VERSION ""

NS_ :

BS_:

BU_: TestTool AFL_AHL LDM_LH LDM_RH
VAL_TABLE_ GFAVity 1 "present" 0 "not present" ;

BO_ 3221225472 VECTOR__INDEPENDENT_SIG_MSG: 0 Vector__XXX
 SG_ HdLmpLvlgMtrRtdCurr : 0|11@0+ (1,0) [0|0] "" Vector__XXX
 SG_ LftPrkLmpDimValue : 0|8@0+ (1,0) [0|0] "" Vector__XXX
 SG_ LftPrkLmpCmd : 0|3@0+ (1,0) [0|0] "" Vector__XXX
 SG_ SystmStat_OvrVltgFail_GFHB_LH : 0|1@0+ (1,0) [0|1] "" Vector__XXX
 SG_ SystmStat_IntrnlSysFail_GFHB_LH : 0|1@0+ (1,0) [0|1] "" Vector__XXX
 SG_ SystmStat_OpnLoadFail_GFHB_LH : 0|1@0+ (1,0) [0|1] "" Vector__XXX
 SG_ SystmStat_ShrtCirctFail_GFHB_LH : 0|1@0+ (1,0) [0|1] "" Vector__XXX
 SG_ SystmStat_OverTempFail_GFHB_LH : 0|1@0+ (1,0) [0|1] "" Vector__XXX
 SG_ SystmStat_MstrMsgFail_GFHB_LH : 0|1@0+ (1,0) [0|1] "" Vector__XXX
 SG_ SystmStat_FanFail_GFHB_LH : 0|1@0+ (1,0) [0|1] "" Vector__XXX
 SG_ SystmStat_CurntCdngFail_GFHB_LH : 0|1@0+ (1,0) [0|1] "" Vector__XXX
 SG_ SystmStat_ExtTempFail_GFHB_LH : 0|1@0+ (1,0) [0|1] "" Vector__XXX
 SG_ SystmStat_IntnlTempFail_GFHB_LH : 0|1@0+ (1,0) [0|1] "" Vector__XXX
 SG_ SystmStat_ActutorFail_GFHB_LH : 0|1@0+ (1,0) [0|1] "" Vector__XXX
 SG_ SystmStat_UndVltgFail_GFHB_LH : 0|1@0+ (1,0) [0|1] "" Vector__XXX
 SG_ SystmStat_FnctnStat_GFHB_LH : 0|1@0+ (1,0) [0|1] "" Vector__XXX
 SG_ SystmStat_R_L_DtctnFail_GFHB_LH : 0|1@0+ (1,0) [0|1] "" Vector__XXX
 SG_ SystmStat_CSorMCFail_GFHB_LH : 0|1@0+ (1,0) [0|1] "" Vector__XXX
 SG_ SystmStat_IncCompFail_GFHB_LH : 0|1@0+ (1,0) [0|1] "" Vector__XXX
 SG_ SystmStat_OvrVltgFail_GFHB_RH : 0|1@0+ (1,0) [0|1] "" Vector__XXX
 SG_ SystmStat_IntrnlSysFail_GFHB_RH : 0|1@0+ (1,0) [0|1] "" Vector__XXX
 SG_ SystmStat_OpnLoadFail_GFHB_RH : 0|1@0+ (1,0) [0|1] "" Vector__XXX
 SG_ SystmStat_ShrtCirctFail_GFHB_RH : 0|1@0+ (1,0) [0|1] "" Vector__XXX
 SG_ SystmStat_OverTempFail_GFHB_RH : 0|1@0+ (1,0) [0|1] "" Vector__XXX
 SG_ SystmStat_MstrMsgFail_GFHB_RH : 0|1@0+ (1,0) [0|1] "" Vector__XXX
 SG_ SystmStat_FanFail_GFHB_RH : 0|1@0+ (1,0) [0|1] "" Vector__XXX
 SG_ SystmStat_CurntCdngFail_GFHB_RH : 0|1@0+ (1,0) [0|1] "" Vector__XXX
 SG_ SystmStat_ExtTempFail_GFHB_RH : 0|1@0+ (1,0) [0|1] "" Vector__XXX
 SG_ SystmStat_IntnlTempFail_GFHB_RH : 0|1@0+ (1,0) [0|1] "" Vector__XXX
 SG_ SystmStat_ActutorFail_GFHB_RH : 0|1@0+ (1,0) [0|1] "" Vector__XXX
 SG_ SystmStat_UndVltgFail_GFHB_RH : 0|1@0+ (1,0) [0|1] "" Vector__XXX
 SG_ SystmStat_FnctnStat_GFHB_RH : 0|1@0+ (1,0) [0|1] "" Vector__XXX
 SG_ SystmStat_R_L_DtctnFail_GFHB_RH : 0|1@0+ (1,0) [0|1] "" Vector__XXX
 SG_ SystmStat_CSorMCFail_GFHB_RH : 0|1@0+ (1,0) [0|1] "" Vector__XXX
 SG_ SystmStat_IncCompFail_GFHB_RH : 0|1@0+ (1,0) [0|1] "" Vector__XXX
 SG_ SystmStat_OvrVltgFail_LDS_LH : 0|1@0+ (1,0) [0|0] "" Vector__XXX
 SG_ SystmStat_IntrnlSysFail_LDS_LH : 0|1@0+ (1,0) [0|1] "" Vector__XXX
 SG_ SystmStat_OpnLoadFail_LDS_LH : 0|1@0+ (1,0) [0|0] "" Vector__XXX
 SG_ SystmStat_ShrtCirctFail_LDS_LH : 0|1@0+ (1,0) [0|0] "" Vector__XXX
 SG_ SystmStat_OverTempFail_LDS_LH : 0|1@0+ (1,0) [0|0] "" Vector__XXX
 SG_ SystmStat_MstrMsgFail_LDS_LH : 0|1@0+ (1,0) [0|0] "" Vector__XXX
 SG_ SystmStat_FanFail_LDS_LH : 0|1@0+ (1,0) [0|0] "" Vector__XXX
 SG_ SystmStat_CurntCdngFail_LDS_LH : 0|1@0+ (1,0) [0|0] "" Vector__XXX
 SG_ SystmStat_ExtTempFail_LDS_LH : 0|1@0+ (1,0) [0|0] "" Vector__XXX
 SG_ SystmStat_IntnlTempFail_LDS_LH : 0|1@0+ (1,0) [0|0] "" Vector__XXX
 SG_ SystmStat_ActutorFail_LDS_LH : 0|1@0+ (1,0) [0|0] "" Vector__XXX
 SG_ SystmStat_UndVltgFail_LDS_LH : 0|1@0+ (1,0) [0|0] "" Vector__XXX
 SG_ SystmStat_FnctnStat_LDS_LH : 0|1@0+ (1,0) [0|1] "" Vector__XXX
 SG_ SystmStat_R_L_DtctnFail_LDS_LH : 0|1@0+ (1,0) [0|0] "" Vector__XXX
 SG_ SystmStat_CSorMCFail_LDS_LH : 0|1@0+ (1,0) [0|0] "" Vector__XXX
 SG_ SystmStat_IncCompFail_LDS_LH : 0|1@0+ (1,0) [0|0] "" Vector__XXX
 SG_ SystmStat_OvrVltgFail_LDS_RH : 0|1@0+ (1,0) [0|0] "" Vector__XXX
 SG_ SystmStat_IntrnlSysFail_LDS_RH : 0|1@0+ (1,0) [0|0] "" Vector__XXX
 SG_ SystmStat_OpnLoadFail_LDS_RH : 0|1@0+ (1,0) [0|0] "" Vector__XXX
 SG_ SystmStat_ShrtCirctFail_LDS_RH : 0|1@0+ (1,0) [0|0] "" Vector__XXX
 SG_ SystmStat_OverTempFail_LDS_RH : 0|1@0+ (1,0) [0|0] "" Vector__XXX
 SG_ SystmStat_MstrMsgFail_LDS_RH : 0|1@0+ (1,0) [0|0] "" Vector__XXX
 SG_ SystmStat_FanFail_LDS_RH : 0|1@0+ (1,0) [0|0] "" Vector__XXX
 SG_ SystmStat_CurntCdngFail_LDS_RH : 0|1@0+ (1,0) [0|0] "" Vector__XXX
 SG_ SystmStat_ExtTempFail_LDS_RH : 0|1@0+ (1,0) [0|0] "" Vector__XXX
 SG_ SystmStat_IntnlTempFail_LDS_RH : 0|1@0+ (1,0) [0|0] "" Vector__XXX
 SG_ SystmStat_ActutorFail_LDS_RH : 0|1@0+ (1,0) [0|0] "" Vector__XXX
 SG_ SystmStat_UndVltgFail_LDS_RH : 0|1@0+ (1,0) [0|0] "" Vector__XXX
 SG_ SystmStat_FnctnStat_LDS_RH : 0|1@0+ (1,0) [0|1] "" Vector__XXX
 SG_ SystmStat_R_L_DtctnFail_LDS_RH : 0|1@0+ (1,0) [0|0] "" Vector__XXX
 SG_ SystmStat_CSorMCFail_LDS_RH : 0|1@0+ (1,0) [0|0] "" Vector__XXX
 SG_ SystmStat_IncCompFail_LDS_RH : 0|1@0+ (1,0) [0|0] "" Vector__XXX
 SG_ SystmStat_OvrVltgFail_SBLS_LH : 0|1@0+ (1,0) [0|1] "" Vector__XXX
 SG_ SystmStat_IntrnlSysFail_SBLS_LH : 0|1@0+ (1,0) [0|1] "" Vector__XXX
 SG_ SystmStat_OpnLoadFail_SBLS_LH : 0|1@0+ (1,0) [0|1] "" Vector__XXX
 SG_ SystmStat_ShrtCirctFail_SBLS_LH : 0|1@0+ (1,0) [0|1] "" Vector__XXX
 SG_ SystmStat_OverTempFail_SBLS_LH : 0|1@0+ (1,0) [0|1] "" Vector__XXX
 SG_ SystmStat_MstrMsgFail_SBLS_LH : 0|1@0+ (1,0) [0|1] "" Vector__XXX
 SG_ SystmStat_FanFail_SBLS_LH : 0|1@0+ (1,0) [0|1] "" Vector__XXX
 SG_ SystmStat_CurntCdngFail_SBLS_LH : 0|1@0+ (1,0) [0|1] "" Vector__XXX
 SG_ SystmStat_ExtTempFail_SBLS_LH : 0|1@0+ (1,0) [0|1] "" Vector__XXX
 SG_ SystmStat_IntnlTempFail_SBLS_LH : 0|1@0+ (1,0) [0|1] "" Vector__XXX
 SG_ SystmStat_ActutorFail_SBLS_LH : 0|1@0+ (1,0) [0|1] "" Vector__XXX
 SG_ SystmStat_UndVltgFail_SBLS_LH : 0|1@0+ (1,0) [0|1] "" Vector__XXX
 SG_ SystmStat_FnctnStat_SBLS_LH : 0|1@0+ (1,0) [0|1] "" Vector__XXX
 SG_ SystmStat_R_L_DtctnFail_SBLS_LH : 0|1@0+ (1,0) [0|1] "" Vector__XXX
 SG_ SystmStat_CSorMCFail_SBLS_LH : 0|1@0+ (1,0) [0|0] "" Vector__XXX
 SG_ SystmStat_IncCompFail_SBLS_LH : 0|1@0+ (1,0) [0|1] "" Vector__XXX
 SG_ SystmStat_OvrVltgFail_SBLS_RH : 0|1@0+ (1,0) [0|1] "" Vector__XXX
 SG_ SystmStat_IntrnlSysFail_SBLS_RH : 0|1@0+ (1,0) [0|1] "" Vector__XXX
 SG_ SystmStat_OpnLoadFail_SBLS_RH : 0|1@0+ (1,0) [0|1] "" Vector__XXX
 SG_ SystmStat_ShrtCirctFail_SBLS_RH : 0|1@0+ (1,0) [0|1] "" Vector__XXX
 SG_ SystmStat_OverTempFail_SBLS_RH : 0|1@0+ (1,0) [0|1] "" Vector__XXX
 SG_ SystmStat_MstrMsgFail_SBLS_RH : 0|1@0+ (1,0) [0|1] "" Vector__XXX
 SG_ SystmStat_FanFail_SBLS_RH : 0|1@0+ (1,0) [0|1] "" Vector__XXX
 SG_ SystmStat_CurntCdngFail_SBLS_RH : 0|1@0+ (1,0) [0|1] "" Vector__XXX
 SG_ SystmStat_ExtTempFail_SBLS_RH : 0|1@0+ (1,0) [0|1] "" Vector__XXX
 SG_ SystmStat_IntnlTempFail_SBLS_RH : 0|1@0+ (1,0) [0|1] "" Vector__XXX
 SG_ SystmStat_ActutorFail_SBLS_RH : 0|1@0+ (1,0) [0|1] "" Vector__XXX
 SG_ SystmStat_UndVltgFail_SBLS_RH : 0|1@0+ (1,0) [0|1] "" Vector__XXX
 SG_ SystmStat_FnctnStat_SBLS_RH : 0|1@0+ (1,0) [0|1] "" Vector__XXX
 SG_ SystmStat_R_L_DtctnFail_SBLS_RH : 0|1@0+ (1,0) [0|1] "" Vector__XXX
 SG_ SystmStat_CSorMCFail_SBLS_RH : 0|1@0+ (1,0) [0|1] "" Vector__XXX
 SG_ SystmStat_IncCompFail_SBLS_RH : 0|1@0+ (1,0) [0|1] "" Vector__XXX
 SG_ LftGFHBMsgCnt : 0|4@0+ (1,0) [0|15] "" Vector__XXX
 SG_ LftGFHBSysPwr : 0|8@0+ (0.1,0) [0|25.5] "V" Vector__XXX
 SG_ LftGFHBLampTemp : 0|8@0+ (1,-50) [-50|205] "°„C" Vector__XXX
 SG_ LftGFHBLdmTemp : 0|8@0+ (1,-50) [-50|205] "°„C" Vector__XXX
 SG_ LftGFHBVINSts : 0|1@0+ (1,0) [0|1] "Enum" Vector__XXX
 SG_ LftGFHBSysCaliSts : 0|2@0+ (1,0) [0|3] "Enum" Vector__XXX
 SG_ LftGFHBDerateSts : 0|2@0+ (1,0) [0|3] "Enum" Vector__XXX
 SG_ LftGFHBDhlInitSts : 0|2@0+ (1,0) [0|3] "" Vector__XXX
 SG_ GFHBMsgCnt : 0|4@0+ (1,0) [0|15] "" Vector__XXX
 SG_ RtGFHBSysPwr : 0|8@0+ (0.1,0) [0|25.5] "V" Vector__XXX
 SG_ RtGFHBLampTemp : 0|8@0+ (1,-50) [-50|205] "°„C" Vector__XXX
 SG_ RtGFHBLdmTemp : 0|8@0+ (1,-50) [-50|205] "°„C" Vector__XXX
 SG_ RtGFHBVINSts : 0|1@0+ (1,0) [0|1] "Enum" Vector__XXX
 SG_ RtGFHBSysCaliSts : 0|2@0+ (1,0) [0|3] "Enum" Vector__XXX
 SG_ RtGFHBDerateSts : 0|2@0+ (1,0) [0|3] "Enum" Vector__XXX
 SG_ RtGFHBDhlInitSts : 0|2@0+ (1,0) [0|3] "" Vector__XXX
 SG_ LftDistrMsgCnt : 0|4@0+ (1,0) [0|15] "" Vector__XXX
 SG_ LftDistrSysPwr : 0|8@0+ (0.1,0) [0|25.5] "V" Vector__XXX
 SG_ LftDistrLampTemp : 0|8@0+ (1,-50) [-50|205] "deg" Vector__XXX
 SG_ LftDistrLdmTemp : 0|8@0+ (1,-50) [-50|205] "deg" Vector__XXX
 SG_ LftDistrVINSts : 0|1@0+ (1,0) [0|1] "" Vector__XXX
 SG_ LftDistrSysCaliSts : 0|2@0+ (1,0) [0|3] "" Vector__XXX
 SG_ LftDistrDerateSts : 0|2@0+ (1,0) [0|3] "" Vector__XXX
 SG_ LftDistrDhlInitSts : 0|2@0+ (1,0) [0|3] "" Vector__XXX
 SG_ DistrMsgCnt : 0|4@0+ (1,0) [0|15] "" Vector__XXX
 SG_ RtDistrSysPwr : 0|8@0+ (0.1,0) [0|25.5] "V" Vector__XXX
 SG_ RtDistrLampTemp : 0|8@0+ (1,-50) [-50|205] "deg" Vector__XXX
 SG_ RtDistrLdmTemp : 0|8@0+ (1,-50) [-50|205] "deg" Vector__XXX
 SG_ RtDistrVINSts : 0|1@0+ (1,0) [0|1] "" Vector__XXX
 SG_ RtDistrSysCaliSts : 0|2@0+ (1,0) [0|3] "" Vector__XXX
 SG_ RtDistrDerateSts : 0|2@0+ (1,0) [0|3] "" Vector__XXX
 SG_ RtDistrDhlInitSts : 0|2@0+ (1,0) [0|4] "" Vector__XXX
 SG_ LftBndSysPwr : 0|8@0+ (0.1,0) [0|25.5] "V" Vector__XXX
 SG_ LftBndLampTemp : 0|8@0+ (1,-50) [-50|205] "°„C" Vector__XXX
 SG_ LftBndLdmTemp : 0|8@0+ (1,-50) [-50|205] "°„C" Vector__XXX
 SG_ LftBndVINSts : 0|1@0+ (1,0) [0|0] "" Vector__XXX
 SG_ LftBndSysCaliSts : 0|2@0+ (1,0) [0|3] "Enum" Vector__XXX
 SG_ LftBndDerateSts : 0|2@0+ (1,0) [0|3] "Enum" Vector__XXX
 SG_ LftBndDhlInitSts : 0|2@0+ (1,0) [0|3] "Enum" Vector__XXX
 SG_ RtBndSysPwr : 0|8@0+ (0.1,0) [0|25.5] "V" Vector__XXX
 SG_ RtBndLampTemp : 0|8@0+ (1,-50) [-50|205] "°„C" Vector__XXX
 SG_ RtBndLdmTemp : 0|8@0+ (1,-50) [-50|205] "°„C" Vector__XXX
 SG_ RtBndVINSts : 0|1@0+ (1,0) [0|1] "Enum" Vector__XXX
 SG_ RtBndSysCaliSts : 0|2@0+ (1,0) [0|3] "Enum" Vector__XXX
 SG_ RtBndDerateSts : 0|2@0+ (1,0) [0|3] "Enum" Vector__XXX
 SG_ RtBndDhlInitSts : 0|2@0+ (1,0) [0|3] "Enum" Vector__XXX
 SG_ RtLdmInfoId0 : 0|8@0+ (1,0) [0|255] "" Vector__XXX
 SG_ RtLdmInfoId1 : 0|8@0+ (1,0) [0|255] "" Vector__XXX
 SG_ RtLdmInfoId2 : 0|8@0+ (1,0) [0|255] "" Vector__XXX
 SG_ RtLdmInfoId3 : 0|8@0+ (1,0) [0|255] "" Vector__XXX
 SG_ RtLdmInfoId4 : 0|8@0+ (1,0) [0|255] "" Vector__XXX
 SG_ RtLdmInfoId5 : 0|8@0+ (1,0) [0|255] "" Vector__XXX
 SG_ RtLdmInfoId6 : 0|8@0+ (1,0) [0|255] "" Vector__XXX
 SG_ RtLdmInfoId7 : 0|8@0+ (1,0) [0|255] "" Vector__XXX
 SG_ RtLdmInfoId0 : 0|8@0+ (1,0) [0|255] "" Vector__XXX
 SG_ RtLdmInfoId1 : 0|8@0+ (1,0) [0|255] "" Vector__XXX
 SG_ RtLdmInfoId2 : 0|8@0+ (1,0) [0|255] "" Vector__XXX
 SG_ RtLdmInfoId3 : 0|8@0+ (1,0) [0|255] "" Vector__XXX
 SG_ RtLdmInfoId4 : 0|8@0+ (1,0) [0|255] "" Vector__XXX
 SG_ RtLdmInfoId5 : 0|8@0+ (1,0) [0|255] "" Vector__XXX
 SG_ RtLdmInfoId6 : 0|8@0+ (1,0) [0|255] "" Vector__XXX
 SG_ RtLdmInfoId7 : 0|8@0+ (1,0) [0|255] "" Vector__XXX
 SG_ RtLdmInfoId0 : 0|8@0+ (1,0) [0|255] "" Vector__XXX
 SG_ RtLdmInfoId1 : 0|8@0+ (1,0) [0|255] "" Vector__XXX
 SG_ RtLdmInfoId2 : 0|8@0+ (1,0) [0|255] "" Vector__XXX
 SG_ RtLdmInfoId3 : 0|8@0+ (1,0) [0|255] "" Vector__XXX
 SG_ RtLdmInfoId4 : 0|8@0+ (1,0) [0|255] "" Vector__XXX
 SG_ RtLdmInfoId5 : 0|8@0+ (1,0) [0|255] "" Vector__XXX
 SG_ RtLdmInfoId6 : 0|8@0+ (1,0) [0|255] "" Vector__XXX
 SG_ RtLdmInfoId7 : 0|8@0+ (1,0) [0|255] "" Vector__XXX
 SG_ VIN_7 : 0|8@0+ (1,0) [0|0] "VIN_7_Units" Vector__XXX
 SG_ SystmStat_OvrVltgFail_DRLS_LH : 0|1@0+ (1,0) [0|0] "" Vector__XXX
 SG_ SystmStat_IntrnlSysFail_DRLS_LH : 0|1@0+ (1,0) [0|0] "" Vector__XXX
 SG_ SystmStat_OpnLoadFail_DRLS_LH : 0|1@0+ (1,0) [0|0] "" Vector__XXX
 SG_ SystmStat_ShrtCirctFail_DRLS_LH : 0|1@0+ (1,0) [0|0] "" Vector__XXX
 SG_ SystmStat_OverTempFail_DRLS_LH : 0|1@0+ (1,0) [0|0] "" Vector__XXX
 SG_ SystmStat_MstrMsgFail_DRLS_LH : 0|1@0+ (1,0) [0|0] "" Vector__XXX
 SG_ SystmStat_FanFail_DRLS_LH : 0|1@0+ (1,0) [0|0] "" Vector__XXX
 SG_ SystmStat_CurntCdngFail_DRLS_LH : 0|1@0+ (1,0) [0|0] "" Vector__XXX
 SG_ SystmStat_ExtTempFail_DRLS_LH : 0|1@0+ (1,0) [0|0] "" Vector__XXX
 SG_ SystmStat_IntnlTempFail_DRLS_LH : 0|1@0+ (1,0) [0|0] "" Vector__XXX
 SG_ SystmStat_ActutorFail_DRLS_LH : 0|1@0+ (1,0) [0|0] "" Vector__XXX
 SG_ SystmStat_UndVltgFail_DRLS_LH : 0|1@0+ (1,0) [0|0] "" Vector__XXX
 SG_ SystmStat_FnctnStat_DRLS_LH : 0|1@0+ (1,0) [0|0] "" Vector__XXX
 SG_ SystmStat_R_L_DtctnFail_DRLS_LH : 0|1@0+ (1,0) [0|0] "" Vector__XXX
 SG_ SystmStat_CSorMCFail_DRLS_LH : 0|1@0+ (1,0) [0|0] "" Vector__XXX
 SG_ SystmStat_IncCompFail_DRLS_LH : 0|1@0+ (1,0) [0|0] "" Vector__XXX
 SG_ SystmStat_SpplyVltgVal_DRLS_LH : 0|8@0+ (1,0) [0|0] "SystmStat_SpplyVltgVal_DRLS_LH_U" Vector__XXX
 SG_ SystmStat_ExtTempVal_DRLS_LH : 0|8@0+ (1,0) [0|0] "SystmStat_ExtTempVal_DRLS_LH_Uni" Vector__XXX
 SG_ SystmStat_IntTempVal_DRLS_LH : 0|8@0+ (1,0) [0|0] "SystmStat_IntTempVal_DRLS_LH_Uni" Vector__XXX
 SG_ SystmStat_VINStat_DRLS_LH : 0|1@0+ (1,0) [0|0] "" Vector__XXX
 SG_ SystmStat_SysCalibStat_DRLS_LH : 0|2@0+ (1,0) [0|0] "" Vector__XXX
 SG_ SystmStat_DertngStat_DRLS_LH : 0|2@0+ (1,0) [0|0] "" Vector__XXX
 SG_ SystmStat_RefrncRunStat_DRLS_LH : 0|2@0+ (1,0) [0|0] "" Vector__XXX
 SG_ SystmStat_OvrVltgFail_DRLS_RH : 0|1@0+ (1,0) [0|0] "" Vector__XXX
 SG_ SystmStat_IntrnlSysFail_DRLS_RH : 0|1@0+ (1,0) [0|0] "" Vector__XXX
 SG_ SystmStat_OpnLoadFail_DRLS_RH : 0|1@0+ (1,0) [0|0] "" Vector__XXX
 SG_ SystmStat_ShrtCirctFail_DRLS_RH : 0|1@0+ (1,0) [0|0] "" Vector__XXX
 SG_ SystmStat_OverTempFail_DRLS_RH : 0|1@0+ (1,0) [0|0] "" Vector__XXX
 SG_ SystmStat_MstrMsgFail_DRLS_RH : 0|1@0+ (1,0) [0|0] "" Vector__XXX
 SG_ SystmStat_FanFail_DRLS_RH : 0|1@0+ (1,0) [0|0] "" Vector__XXX
 SG_ SystmStat_CurntCdngFail_DRLS_RH : 0|1@0+ (1,0) [0|0] "" Vector__XXX
 SG_ SystmStat_ExtTempFail_DRLS_RH : 0|1@0+ (1,0) [0|0] "" Vector__XXX
 SG_ SystmStat_IntnlTempFail_DRLS_RH : 0|1@0+ (1,0) [0|0] "" Vector__XXX
 SG_ SystmStat_ActutorFail_DRLS_RH : 0|1@0+ (1,0) [0|0] "" Vector__XXX
 SG_ SystmStat_UndVltgFail_DRLS_RH : 0|1@0+ (1,0) [0|0] "" Vector__XXX
 SG_ SystmStat_FnctnStat_DRLS_RH : 0|1@0+ (1,0) [0|0] "" Vector__XXX
 SG_ SystmStat_R_L_DtctnFail_DRLS_RH : 0|1@0+ (1,0) [0|0] "" Vector__XXX
 SG_ SystmStat_CSorMCFail_DRLS_RH : 0|1@0+ (1,0) [0|0] "" Vector__XXX
 SG_ SystmStat_IncCompFail_DRLS_RH : 0|1@0+ (1,0) [0|0] "" Vector__XXX
 SG_ SystmStat_SpplyVltgVal_DRLS_RH : 0|8@0+ (1,0) [0|0] "SystmStat_SpplyVltgVal_DRLS_RH_U" Vector__XXX
 SG_ SystmStat_ExtTempVal_DRLS_RH : 0|8@0+ (1,0) [0|0] "SystmStat_ExtTempVal_DRLS_RH_Uni" Vector__XXX
 SG_ SystmStat_IntTempVal_DRLS_RH : 0|8@0+ (1,0) [0|0] "SystmStat_IntTempVal_DRLS_RH_Uni" Vector__XXX
 SG_ SystmStat_VINStat_DRLS_RH : 0|1@0+ (1,0) [0|0] "" Vector__XXX
 SG_ SystmStat_SysCalibStat_DRLS_RH : 0|2@0+ (1,0) [0|0] "" Vector__XXX
 SG_ SystmStat_DertngStat_DRLS_RH : 0|2@0+ (1,0) [0|0] "" Vector__XXX
 SG_ SystmStat_RefrncRunStat_DRLS_RH : 0|2@0+ (1,0) [0|0] "" Vector__XXX
 SG_ SystmStat_Chcksm_HLS_LH : 0|8@0+ (1,0) [0|255] "" Vector__XXX
 SG_ SystmStat_OvrVltgFail_HLS_LH : 0|1@0+ (1,0) [0|1] "" Vector__XXX
 SG_ SystmStat_IntrnlSysFail_HLS_LH : 0|1@0+ (1,0) [0|1] "" Vector__XXX
 SG_ SystmStat_OpnLoadFail_HLS_LH : 0|1@0+ (1,0) [0|1] "" Vector__XXX
 SG_ SystmStat_ShrtCirctFail_HLS_LH : 0|1@0+ (1,0) [0|1] "" Vector__XXX
 SG_ SystmStat_MssgCntr_HLS_LH : 0|4@0+ (1,0) [0|15] "" Vector__XXX
 SG_ SystmStat_OverTempFail_HLS_LH : 0|1@0+ (1,0) [0|1] "" Vector__XXX
 SG_ SystmStat_MstrMsgFail_HLS_LH : 0|1@0+ (1,0) [0|1] "" Vector__XXX
 SG_ SystmStat_FanFail_HLS_LH : 0|1@0+ (1,0) [0|1] "" Vector__XXX
 SG_ SystmStat_CurntCdngFail_HLS_LH : 0|1@0+ (1,0) [0|1] "" Vector__XXX
 SG_ SystmStat_ExtTempFail_HLS_LH : 0|1@0+ (1,0) [0|1] "" Vector__XXX
 SG_ SystmStat_IntnlTempFail_HLS_LH : 0|1@0+ (1,0) [0|1] "" Vector__XXX
 SG_ SystmStat_ActutorFail_HLS_LH : 0|1@0+ (1,0) [0|1] "" Vector__XXX
 SG_ SystmStat_UndVltgFail_HLS_LH : 0|1@0+ (1,0) [0|1] "" Vector__XXX
 SG_ SystmStat_FnctnStat_HLS_LH : 0|1@0+ (1,0) [0|1] "" Vector__XXX
 SG_ SystmStat_R_L_DtctnFail_HLS_LH : 0|1@0+ (1,0) [0|1] "" Vector__XXX
 SG_ SystmStat_CSorMCFail_HLS_LH : 0|1@0+ (1,0) [0|1] "" Vector__XXX
 SG_ SystmStat_IncCompFail_HLS_LH : 0|1@0+ (1,0) [0|1] "" Vector__XXX
 SG_ SystmStat_SpplyVltgVal_HLS_LH : 0|8@0+ (0.1,0) [0|25.5] "V" Vector__XXX
 SG_ SystmStat_ExtTempVal_HLS_LH : 0|8@0+ (1,-50) [-50|205] "°„C" Vector__XXX
 SG_ SystmStat_IntTempVal_HLS_LH : 0|8@0+ (1,-50) [-50|205] "°„C" Vector__XXX
 SG_ SystmStat_VINStat_HLS_LH : 0|1@0+ (1,0) [0|1] "Enum" Vector__XXX
 SG_ SystmStat_SysCalibStat_HLS_LH : 0|2@0+ (1,0) [0|3] "Enum" Vector__XXX
 SG_ SystmStat_DertngStat_HLS_LH : 0|2@0+ (1,0) [0|3] "Enum" Vector__XXX
 SG_ SystmStat_RefrncRunStat_HLS_LH : 0|2@0+ (1,0) [0|3] "Enum" Vector__XXX
 SG_ SystmStat_Chcksm_HLS_RH : 0|8@0+ (1,0) [0|255] "" Vector__XXX
 SG_ SystmStat_OvrVltgFail_HLS_RH : 0|1@0+ (1,0) [0|1] "" Vector__XXX
 SG_ SystmStat_IntrnlSysFail_HLS_RH : 0|1@0+ (1,0) [0|1] "" Vector__XXX
 SG_ SystmStat_OpnLoadFail_HLS_RH : 0|1@0+ (1,0) [0|1] "" Vector__XXX
 SG_ SystmStat_ShrtCirctFail_HLS_RH : 0|1@0+ (1,0) [0|1] "" Vector__XXX
 SG_ SystmStat_MssgCntr_HLS_RH : 0|4@0+ (1,0) [0|15] "" Vector__XXX
 SG_ SystmStat_OverTempFail_HLS_RH : 0|1@0+ (1,0) [0|1] "" Vector__XXX
 SG_ SystmStat_MstrMsgFail_HLS_RH : 0|1@0+ (1,0) [0|1] "" Vector__XXX
 SG_ SystmStat_FanFail_HLS_RH : 0|1@0+ (1,0) [0|1] "" Vector__XXX
 SG_ SystmStat_CurntCdngFail_HLS_RH : 0|1@0+ (1,0) [0|1] "" Vector__XXX
 SG_ SystmStat_ExtTempFail_HLS_RH : 0|1@0+ (1,0) [0|1] "" Vector__XXX
 SG_ SystmStat_IntnlTempFail_HLS_RH : 0|1@0+ (1,0) [0|1] "" Vector__XXX
 SG_ SystmStat_ActutorFail_HLS_RH : 0|1@0+ (1,0) [0|1] "" Vector__XXX
 SG_ SystmStat_UndVltgFail_HLS_RH : 0|1@0+ (1,0) [0|1] "" Vector__XXX
 SG_ SystmStat_FnctnStat_HLS_RH : 0|1@0+ (1,0) [0|1] "" Vector__XXX
 SG_ SystmStat_R_L_DtctnFail_HLS_RH : 0|1@0+ (1,0) [0|1] "" Vector__XXX
 SG_ SystmStat_CSorMCFail_HLS_RH : 0|1@0+ (1,0) [0|1] "" Vector__XXX
 SG_ SystmStat_IncCompFail_HLS_RH : 0|1@0+ (1,0) [0|1] "" Vector__XXX
 SG_ SystmStat_SpplyVltgVal_HLS_RH : 0|8@0+ (0.1,0) [0|25.5] "V" Vector__XXX
 SG_ SystmStat_ExtTempVal_HLS_RH : 0|8@0+ (1,-50) [-50|205] "°„C" Vector__XXX
 SG_ SystmStat_IntTempVal_HLS_RH : 0|8@0+ (1,-50) [-50|205] "°„C" Vector__XXX
 SG_ SystmStat_VINStat_HLS_RH : 0|1@0+ (1,0) [0|1] "Enum" Vector__XXX
 SG_ SystmStat_SysCalibStat_HLS_RH : 0|2@0+ (1,0) [0|3] "Enum" Vector__XXX
 SG_ SystmStat_DertngStat_HLS_RH : 0|2@0+ (1,0) [0|3] "Enum" Vector__XXX
 SG_ SystmStat_RefrncRunStat_HLS_RH : 0|2@0+ (1,0) [0|3] "" Vector__XXX
 SG_ SystmStat_Chcksm_DBLS_LH : 0|8@0+ (1,0) [0|0] "" Vector__XXX
 SG_ SystmStat_OvrVltgFail_DBLS_LH : 0|1@0+ (1,0) [0|0] "" Vector__XXX
 SG_ SystmStat_IntrnlSysFail_DBLS_LH : 0|1@0+ (1,0) [0|0] "" Vector__XXX
 SG_ SystmStat_OpnLoadFail_DBLS_LH : 0|1@0+ (1,0) [0|0] "" Vector__XXX
 SG_ SystmStat_ShrtCirctFail_DBLS_LH : 0|1@0+ (1,0) [0|0] "" Vector__XXX
 SG_ SystmStat_MssgCntr_DBLS_LH : 0|4@0+ (1,0) [0|0] "" Vector__XXX
 SG_ SystmStat_OverTempFail_DBLS_LH : 0|1@0+ (1,0) [0|0] "" Vector__XXX
 SG_ SystmStat_MstrMsgFail_DBLS_LH : 0|1@0+ (1,0) [0|0] "" Vector__XXX
 SG_ SystmStat_FanFail_DBLS_LH : 0|1@0+ (1,0) [0|0] "" Vector__XXX
 SG_ SystmStat_CurntCdngFail_DBLS_LH : 0|1@0+ (1,0) [0|0] "" Vector__XXX
 SG_ SystmStat_ExtTempFail_DBLS_LH : 0|1@0+ (1,0) [0|0] "" Vector__XXX
 SG_ SystmStat_IntnlTempFail_DBLS_LH : 0|1@0+ (1,0) [0|0] "" Vector__XXX
 SG_ SystmStat_ActutorFail_DBLS_LH : 0|1@0+ (1,0) [0|0] "" Vector__XXX
 SG_ SystmStat_UndVltgFail_DBLS_LH : 0|1@0+ (1,0) [0|0] "" Vector__XXX
 SG_ SystmStat_FnctnStat_DBLS_LH : 0|1@0+ (1,0) [0|0] "" Vector__XXX
 SG_ SystmStat_R_L_DtctnFail_DBLS_LH : 0|1@0+ (1,0) [0|0] "" Vector__XXX
 SG_ SystmStat_CSorMCFail_DBLS_LH : 0|1@0+ (1,0) [0|0] "" Vector__XXX
 SG_ SystmStat_IncCompFail_DBLS_LH : 0|1@0+ (1,0) [0|0] "" Vector__XXX
 SG_ SystmStat_SpplyVltgVal_DBLS_LH : 0|8@0+ (1,0) [0|0] "SystmStat_SpplyVltgVal_DBLS_LH_U" Vector__XXX
 SG_ SystmStat_ExtTempVal_DBLS_LH : 0|8@0+ (1,0) [0|0] "SystmStat_ExtTempVal_DBLS_LH_Uni" Vector__XXX
 SG_ SystmStat_IntTempVal_DBLS_LH : 0|8@0+ (1,0) [0|0] "SystmStat_IntTempVal_DBLS_LH_Uni" Vector__XXX
 SG_ SystmStat_VINStat_DBLS_LH : 0|1@0+ (1,0) [0|0] "" Vector__XXX
 SG_ SystmStat_SysCalibStat_DBLS_LH : 0|2@0+ (1,0) [0|0] "" Vector__XXX
 SG_ SystmStat_DertngStat_DBLS_LH : 0|2@0+ (1,0) [0|0] "" Vector__XXX
 SG_ SystmStat_RefrncRunStat_DBLS_LH : 0|2@0+ (1,0) [0|0] "" Vector__XXX
 SG_ SystmStat_Chcksm_DBLS_RH : 0|8@0+ (1,0) [0|0] "" Vector__XXX
 SG_ SystmStat_OvrVltgFail_DBLS_RH : 0|1@0+ (1,0) [0|0] "" Vector__XXX
 SG_ SystmStat_IntrnlSysFail_DBLS_RH : 0|1@0+ (1,0) [0|0] "" Vector__XXX
 SG_ SystmStat_OpnLoadFail_DBLS_RH : 0|1@0+ (1,0) [0|0] "" Vector__XXX
 SG_ SystmStat_ShrtCirctFail_DBLS_RH : 0|1@0+ (1,0) [0|0] "" Vector__XXX
 SG_ SystmStat_MssgCntr_DBLS_RH : 0|4@0+ (1,0) [0|0] "" Vector__XXX
 SG_ SystmStat_OverTempFail_DBLS_RH : 0|1@0+ (1,0) [0|0] "" Vector__XXX
 SG_ SystmStat_MstrMsgFail_DBLS_RH : 0|1@0+ (1,0) [0|0] "" Vector__XXX
 SG_ SystmStat_FanFail_DBLS_RH : 0|1@0+ (1,0) [0|0] "" Vector__XXX
 SG_ SystmStat_CurntCdngFail_DBLS_RH : 0|1@0+ (1,0) [0|0] "" Vector__XXX
 SG_ SystmStat_ExtTempFail_DBLS_RH : 0|1@0+ (1,0) [0|0] "" Vector__XXX
 SG_ SystmStat_IntnlTempFail_DBLS_RH : 0|1@0+ (1,0) [0|0] "" Vector__XXX
 SG_ SystmStat_ActutorFail_DBLS_RH : 0|1@0+ (1,0) [0|0] "" Vector__XXX
 SG_ SystmStat_UndVltgFail_DBLS_RH : 0|1@0+ (1,0) [0|0] "" Vector__XXX
 SG_ SystmStat_FnctnStat_DBLS_RH : 0|1@0+ (1,0) [0|0] "" Vector__XXX
 SG_ SystmStat_R_L_DtctnFail_DBLS_RH : 0|1@0+ (1,0) [0|0] "" Vector__XXX
 SG_ SystmStat_CSorMCFail_DBLS_RH : 0|1@0+ (1,0) [0|0] "" Vector__XXX
 SG_ SystmStat_IncCompFail_DBLS_RH : 0|1@0+ (1,0) [0|0] "" Vector__XXX
 SG_ SystmStat_SpplyVltgVal_DBLS_RH : 0|8@0+ (1,0) [0|0] "SystmStat_SpplyVltgVal_DBLS_RH_U" Vector__XXX
 SG_ SystmStat_ExtTempVal_DBLS_RH : 0|8@0+ (1,0) [0|0] "SystmStat_ExtTempVal_DBLS_RH_Uni" Vector__XXX
 SG_ SystmStat_IntTempVal_DBLS_RH : 0|8@0+ (1,0) [0|0] "SystmStat_IntTempVal_DBLS_RH_Uni" Vector__XXX
 SG_ SystmStat_VINStat_DBLS_RH : 0|1@0+ (1,0) [0|0] "" Vector__XXX
 SG_ SystmStat_SysCalibStat_DBLS_RH : 0|2@0+ (1,0) [0|0] "" Vector__XXX
 SG_ SystmStat_DertngStat_DBLS_RH : 0|2@0+ (1,0) [0|0] "" Vector__XXX
 SG_ SystmStat_RefrncRunStat_DBLS_RH : 0|2@0+ (1,0) [0|0] "" Vector__XXX
 SG_ SystmStat_Chcksm_MLS_LH : 0|8@0+ (1,0) [0|0] "" Vector__XXX
 SG_ SystmStat_OvrVltgFail_MLS_LH : 0|1@0+ (1,0) [0|0] "" Vector__XXX
 SG_ SystmStat_IntrnlSysFail_MLS_LH : 0|1@0+ (1,0) [0|0] "" Vector__XXX
 SG_ SystmStat_OpnLoadFail_MLS_LH : 0|1@0+ (1,0) [0|0] "" Vector__XXX
 SG_ SystmStat_ShrtCirctFail_MLS_LH : 0|1@0+ (1,0) [0|0] "" Vector__XXX
 SG_ SystmStat_MssgCntr_MLS_LH : 0|4@0+ (1,0) [0|0] "" Vector__XXX
 SG_ SystmStat_OverTempFail_MLS_LH : 0|1@0+ (1,0) [0|0] "" Vector__XXX
 SG_ SystmStat_MstrMsgFail_MLS_LH : 0|1@0+ (1,0) [0|0] "" Vector__XXX
 SG_ SystmStat_FanFail_MLS_LH : 0|1@0+ (1,0) [0|0] "" Vector__XXX
 SG_ SystmStat_CurntCdngFail_MLS_LH : 0|1@0+ (1,0) [0|0] "" Vector__XXX
 SG_ SystmStat_ExtTempFail_MLS_LH : 0|1@0+ (1,0) [0|0] "" Vector__XXX
 SG_ SystmStat_IntnlTempFail_MLS_LH : 0|1@0+ (1,0) [0|0] "" Vector__XXX
 SG_ SystmStat_ActutorFail_MLS_LH : 0|1@0+ (1,0) [0|0] "" Vector__XXX
 SG_ SystmStat_UndVltgFail_MLS_LH : 0|1@0+ (1,0) [0|0] "" Vector__XXX
 SG_ SystmStat_FnctnStat_MLS_LH : 0|1@0+ (1,0) [0|0] "" Vector__XXX
 SG_ SystmStat_R_L_DtctnFail_MLS_LH : 0|1@0+ (1,0) [0|0] "" Vector__XXX
 SG_ SystmStat_CSorMCFail_MLS_LH : 0|1@0+ (1,0) [0|0] "" Vector__XXX
 SG_ SystmStat_IncCompFail_MLS_LH : 0|1@0+ (1,0) [0|0] "" Vector__XXX
 SG_ SystmStat_SpplyVltgVal_MLS_LH : 0|8@0+ (1,0) [0|0] "SystmStat_SpplyVltgVal_MLS_LH_Un" Vector__XXX
 SG_ SystmStat_ExtTempVal_MLS_LH : 0|8@0+ (1,0) [0|0] "SystmStat_ExtTempVal_MLS_LH_Unit" Vector__XXX
 SG_ SystmStat_IntTempVal_MLS_LH : 0|8@0+ (1,0) [0|0] "SystmStat_IntTempVal_MLS_LH_Unit" Vector__XXX
 SG_ SystmStat_VINStat_MLS_LH : 0|1@0+ (1,0) [0|0] "" Vector__XXX
 SG_ SystmStat_SysCalibStat_MLS_LH : 0|2@0+ (1,0) [0|0] "" Vector__XXX
 SG_ SystmStat_DertngStat_MLS_LH : 0|2@0+ (1,0) [0|0] "" Vector__XXX
 SG_ SystmStat_RefrncRunStat_MLS_LH : 0|2@0+ (1,0) [0|0] "" Vector__XXX
 SG_ SystmStat_Chcksm_MLS_RH : 0|8@0+ (1,0) [0|0] "" Vector__XXX
 SG_ SystmStat_OvrVltgFail_MLS_RH : 0|1@0+ (1,0) [0|0] "" Vector__XXX
 SG_ SystmStat_IntrnlSysFail_MLS_RH : 0|1@0+ (1,0) [0|0] "" Vector__XXX
 SG_ SystmStat_OpnLoadFail_MLS_RH : 0|1@0+ (1,0) [0|0] "" Vector__XXX
 SG_ SystmStat_ShrtCirctFail_MLS_RH : 0|1@0+ (1,0) [0|0] "" Vector__XXX
 SG_ SystmStat_MssgCntr_MLS_RH : 0|4@0+ (1,0) [0|0] "" Vector__XXX
 SG_ SystmStat_OverTempFail_MLS_RH : 0|1@0+ (1,0) [0|0] "" Vector__XXX
 SG_ SystmStat_MstrMsgFail_MLS_RH : 0|1@0+ (1,0) [0|0] "" Vector__XXX
 SG_ SystmStat_FanFail_MLS_RH : 0|1@0+ (1,0) [0|0] "" Vector__XXX
 SG_ SystmStat_CurntCdngFail_MLS_RH : 0|1@0+ (1,0) [0|0] "" Vector__XXX
 SG_ SystmStat_ExtTempFail_MLS_RH : 0|1@0+ (1,0) [0|0] "" Vector__XXX
 SG_ SystmStat_IntnlTempFail_MLS_RH : 0|1@0+ (1,0) [0|0] "" Vector__XXX
 SG_ SystmStat_ActutorFail_MLS_RH : 0|1@0+ (1,0) [0|0] "" Vector__XXX
 SG_ SystmStat_UndVltgFail_MLS_RH : 0|1@0+ (1,0) [0|0] "" Vector__XXX
 SG_ SystmStat_FnctnStat_MLS_RH : 0|1@0+ (1,0) [0|0] "" Vector__XXX
 SG_ SystmStat_R_L_DtctnFail_MLS_RH : 0|1@0+ (1,0) [0|0] "" Vector__XXX
 SG_ SystmStat_CSorMCFail_MLS_RH : 0|1@0+ (1,0) [0|0] "" Vector__XXX
 SG_ SystmStat_IncCompFail_MLS_RH : 0|1@0+ (1,0) [0|0] "" Vector__XXX
 SG_ SystmStat_SpplyVltgVal_MLS_RH : 0|8@0+ (1,0) [0|0] "SystmStat_SpplyVltgVal_MLS_RH_Un" Vector__XXX
 SG_ SystmStat_ExtTempVal_MLS_RH : 0|8@0+ (1,0) [0|0] "SystmStat_ExtTempVal_MLS_RH_Unit" Vector__XXX
 SG_ SystmStat_IntTempVal_MLS_RH : 0|8@0+ (1,0) [0|0] "SystmStat_IntTempVal_MLS_RH_Unit" Vector__XXX
 SG_ SystmStat_VINStat_MLS_RH : 0|1@0+ (1,0) [0|0] "" Vector__XXX
 SG_ SystmStat_SysCalibStat_MLS_RH : 0|2@0+ (1,0) [0|0] "" Vector__XXX
 SG_ SystmStat_DertngStat_MLS_RH : 0|2@0+ (1,0) [0|0] "" Vector__XXX
 SG_ SystmStat_RefrncRunStat_MLS_RH : 0|2@0+ (1,0) [0|0] "" Vector__XXX
 SG_ SystmStat_OvrVltgFail_PLS_LH : 0|1@0+ (1,0) [0|0] "" Vector__XXX
 SG_ SystmStat_IntrnlSysFail_PLS_LH : 0|1@0+ (1,0) [0|0] "" Vector__XXX
 SG_ SystmStat_OpnLoadFail_PLS_LH : 0|1@0+ (1,0) [0|0] "" Vector__XXX
 SG_ SystmStat_ShrtCirctFail_PLS_LH : 0|1@0+ (1,0) [0|0] "" Vector__XXX
 SG_ SystmStat_OverTempFail_PLS_LH : 0|1@0+ (1,0) [0|0] "" Vector__XXX
 SG_ SystmStat_MstrMsgFail_PLS_LH : 0|1@0+ (1,0) [0|0] "" Vector__XXX
 SG_ SystmStat_FanFail_PLS_LH : 0|1@0+ (1,0) [0|0] "" Vector__XXX
 SG_ SystmStat_CurntCdngFail_PLS_LH : 0|1@0+ (1,0) [0|0] "" Vector__XXX
 SG_ SystmStat_ExtTempFail_PLS_LH : 0|1@0+ (1,0) [0|0] "" Vector__XXX
 SG_ SystmStat_IntnlTempFail_PLS_LH : 0|1@0+ (1,0) [0|0] "" Vector__XXX
 SG_ SystmStat_ActutorFail_PLS_LH : 0|1@0+ (1,0) [0|0] "" Vector__XXX
 SG_ SystmStat_UndVltgFail_PLS_LH : 0|1@0+ (1,0) [0|0] "" Vector__XXX
 SG_ SystmStat_FnctnStat_PLS_LH : 0|1@0+ (1,0) [0|0] "" Vector__XXX
 SG_ SystmStat_R_L_DtctnFail_PLS_LH : 0|1@0+ (1,0) [0|0] "" Vector__XXX
 SG_ SystmStat_CSorMCFail_PLS_LH : 0|1@0+ (1,0) [0|0] "" Vector__XXX
 SG_ SystmStat_IncCompFail_PLS_LH : 0|1@0+ (1,0) [0|0] "" Vector__XXX
 SG_ SystmStat_SpplyVltgVal_PLS_LH : 0|8@0+ (1,0) [0|0] "SystmStat_SpplyVltgVal_PLS_LH_Un" Vector__XXX
 SG_ SystmStat_ExtTempVal_PLS_LH : 0|8@0+ (1,0) [0|0] "SystmStat_ExtTempVal_PLS_LH_Unit" Vector__XXX
 SG_ SystmStat_IntTempVal_PLS_LH : 0|8@0+ (1,0) [0|0] "SystmStat_IntTempVal_PLS_LH_Unit" Vector__XXX
 SG_ SystmStat_VINStat_PLS_LH : 0|1@0+ (1,0) [0|0] "" Vector__XXX
 SG_ SystmStat_SysCalibStat_PLS_LH : 0|2@0+ (1,0) [0|0] "" Vector__XXX
 SG_ SystmStat_DertngStat_PLS_LH : 0|2@0+ (1,0) [0|0] "" Vector__XXX
 SG_ SystmStat_RefrncRunStat_PLS_LH : 0|2@0+ (1,0) [0|0] "" Vector__XXX
 SG_ SystmStat_OvrVltgFail_PLS_RH : 0|1@0+ (1,0) [0|0] "" Vector__XXX
 SG_ SystmStat_IntrnlSysFail_PLS_RH : 0|1@0+ (1,0) [0|0] "" Vector__XXX
 SG_ SystmStat_OpnLoadFail_PLS_RH : 0|1@0+ (1,0) [0|0] "" Vector__XXX
 SG_ SystmStat_ShrtCirctFail_PLS_RH : 0|1@0+ (1,0) [0|0] "" Vector__XXX
 SG_ SystmStat_OverTempFail_PLS_RH : 0|1@0+ (1,0) [0|0] "" Vector__XXX
 SG_ SystmStat_MstrMsgFail_PLS_RH : 0|1@0+ (1,0) [0|0] "" Vector__XXX
 SG_ SystmStat_FanFail_PLS_RH : 0|1@0+ (1,0) [0|0] "" Vector__XXX
 SG_ SystmStat_CurntCdngFail_PLS_RH : 0|1@0+ (1,0) [0|0] "" Vector__XXX
 SG_ SystmStat_ExtTempFail_PLS_RH : 0|1@0+ (1,0) [0|0] "" Vector__XXX
 SG_ SystmStat_IntnlTempFail_PLS_RH : 0|1@0+ (1,0) [0|0] "" Vector__XXX
 SG_ SystmStat_ActutorFail_PLS_RH : 0|1@0+ (1,0) [0|0] "" Vector__XXX
 SG_ SystmStat_UndVltgFail_PLS_RH : 0|1@0+ (1,0) [0|0] "" Vector__XXX
 SG_ SystmStat_FnctnStat_PLS_RH : 0|1@0+ (1,0) [0|0] "" Vector__XXX
 SG_ SystmStat_R_L_DtctnFail_PLS_RH : 0|1@0+ (1,0) [0|0] "" Vector__XXX
 SG_ SystmStat_CSorMCFail_PLS_RH : 0|1@0+ (1,0) [0|0] "" Vector__XXX
 SG_ SystmStat_IncCompFail_PLS_RH : 0|1@0+ (1,0) [0|0] "" Vector__XXX
 SG_ SystmStat_SpplyVltgVal_PLS_RH : 0|8@0+ (1,0) [0|0] "SystmStat_SpplyVltgVal_PLS_RH_Un" Vector__XXX
 SG_ SystmStat_ExtTempVal_PLS_RH : 0|8@0+ (1,0) [0|0] "SystmStat_ExtTempVal_PLS_RH_Unit" Vector__XXX
 SG_ SystmStat_IntTempVal_PLS_RH : 0|8@0+ (1,0) [0|0] "SystmStat_IntTempVal_PLS_RH_Unit" Vector__XXX
 SG_ SystmStat_VINStat_PLS_RH : 0|1@0+ (1,0) [0|0] "" Vector__XXX
 SG_ SystmStat_SysCalibStat_PLS_RH : 0|2@0+ (1,0) [0|0] "" Vector__XXX
 SG_ SystmStat_DertngStat_PLS_RH : 0|2@0+ (1,0) [0|0] "" Vector__XXX
 SG_ SystmStat_RefrncRunStat_PLS_RH : 0|2@0+ (1,0) [0|0] "" Vector__XXX
 SG_ SystmStat_Chcksm_TILS_LH : 0|8@0+ (1,0) [0|0] "" Vector__XXX
 SG_ SystmStat_OvrVltgFail_TILS_LH : 0|1@0+ (1,0) [0|0] "" Vector__XXX
 SG_ SystmStat_IntrnlSysFail_TILS_LH : 0|1@0+ (1,0) [0|0] "" Vector__XXX
 SG_ SystmStat_OpnLoadFail_TILS_LH : 0|1@0+ (1,0) [0|0] "" Vector__XXX
 SG_ SystmStat_ShrtCirctFail_TILS_LH : 0|1@0+ (1,0) [0|0] "" Vector__XXX
 SG_ SystmStat_MssgCntr_TILS_LH : 0|4@0+ (1,0) [0|0] "" Vector__XXX
 SG_ SystmStat_OverTempFail_TILS_LH : 0|1@0+ (1,0) [0|0] "" Vector__XXX
 SG_ SystmStat_MstrMsgFail_TILS_LH : 0|1@0+ (1,0) [0|0] "" Vector__XXX
 SG_ SystmStat_FanFail_TILS_LH : 0|1@0+ (1,0) [0|0] "" Vector__XXX
 SG_ SystmStat_CurntCdngFail_TILS_LH : 0|1@0+ (1,0) [0|0] "" Vector__XXX
 SG_ SystmStat_ExtTempFail_TILS_LH : 0|1@0+ (1,0) [0|0] "" Vector__XXX
 SG_ SystmStat_IntnlTempFail_TILS_LH : 0|1@0+ (1,0) [0|0] "" Vector__XXX
 SG_ SystmStat_ActutorFail_TILS_LH : 0|1@0+ (1,0) [0|0] "" Vector__XXX
 SG_ SystmStat_UndVltgFail_TILS_LH : 0|1@0+ (1,0) [0|0] "" Vector__XXX
 SG_ SystmStat_FnctnStat_TILS_LH : 0|1@0+ (1,0) [0|0] "" Vector__XXX
 SG_ SystmStat_R_L_DtctnFail_TILS_LH : 0|1@0+ (1,0) [0|0] "" Vector__XXX
 SG_ SystmStat_CSorMCFail_TILS_LH : 0|1@0+ (1,0) [0|0] "" Vector__XXX
 SG_ SystmStat_IncCompFail_TILS_LH : 0|1@0+ (1,0) [0|0] "" Vector__XXX
 SG_ SystmStat_SpplyVltgVal_TILS_LH : 0|8@0+ (1,0) [0|0] "SystmStat_SpplyVltgVal_TILS_LH_U" Vector__XXX
 SG_ SystmStat_ExtTempVal_TILS_LH : 0|8@0+ (1,0) [0|0] "SystmStat_ExtTempVal_TILS_LH_Uni" Vector__XXX
 SG_ SystmStat_IntTempVal_TILS_LH : 0|8@0+ (1,0) [0|0] "SystmStat_IntTempVal_TILS_LH_Uni" Vector__XXX
 SG_ SystmStat_VINStat_TILS_LH : 0|1@0+ (1,0) [0|0] "" Vector__XXX
 SG_ SystmStat_SysCalibStat_TILS_LH : 0|2@0+ (1,0) [0|0] "" Vector__XXX
 SG_ SystmStat_DertngStat_TILS_LH : 0|2@0+ (1,0) [0|0] "" Vector__XXX
 SG_ SystmStat_RefrncRunStat_TILS_LH : 0|2@0+ (1,0) [0|0] "" Vector__XXX
 SG_ SystmStat_Chcksm_TILS_RH : 0|8@0+ (1,0) [0|0] "" Vector__XXX
 SG_ SystmStat_OvrVltgFail_TILS_RH : 0|1@0+ (1,0) [0|0] "" Vector__XXX
 SG_ SystmStat_IntrnlSysFail_TILS_RH : 0|1@0+ (1,0) [0|0] "" Vector__XXX
 SG_ SystmStat_OpnLoadFail_TILS_RH : 0|1@0+ (1,0) [0|0] "" Vector__XXX
 SG_ SystmStat_ShrtCirctFail_TILS_RH : 0|1@0+ (1,0) [0|0] "" Vector__XXX
 SG_ SystmStat_MssgCntr_TILS_RH : 0|4@0+ (1,0) [0|0] "" Vector__XXX
 SG_ SystmStat_OverTempFail_TILS_RH : 0|1@0+ (1,0) [0|0] "" Vector__XXX
 SG_ SystmStat_MstrMsgFail_TILS_RH : 0|1@0+ (1,0) [0|0] "" Vector__XXX
 SG_ SystmStat_FanFail_TILS_RH : 0|1@0+ (1,0) [0|0] "" Vector__XXX
 SG_ SystmStat_CurntCdngFail_TILS_RH : 0|1@0+ (1,0) [0|0] "" Vector__XXX
 SG_ SystmStat_ExtTempFail_TILS_RH : 0|1@0+ (1,0) [0|0] "" Vector__XXX
 SG_ SystmStat_IntnlTempFail_TILS_RH : 0|1@0+ (1,0) [0|0] "" Vector__XXX
 SG_ SystmStat_ActutorFail_TILS_RH : 0|1@0+ (1,0) [0|0] "" Vector__XXX
 SG_ SystmStat_UndVltgFail_TILS_RH : 0|1@0+ (1,0) [0|0] "" Vector__XXX
 SG_ SystmStat_FnctnStat_TILS_RH : 0|1@0+ (1,0) [0|0] "" Vector__XXX
 SG_ SystmStat_R_L_DtctnFail_TILS_RH : 0|1@0+ (1,0) [0|0] "" Vector__XXX
 SG_ SystmStat_CSorMCFail_TILS_RH : 0|1@0+ (1,0) [0|0] "" Vector__XXX
 SG_ SystmStat_IncCompFail_TILS_RH : 0|1@0+ (1,0) [0|0] "" Vector__XXX
 SG_ SystmStat_SpplyVltgVal_TILS_RH : 0|8@0+ (1,0) [0|0] "SystmStat_SpplyVltgVal_TILS_RH_U" Vector__XXX
 SG_ SystmStat_ExtTempVal_TILS_RH : 0|8@0+ (1,0) [0|0] "SystmStat_ExtTempVal_TILS_RH_Uni" Vector__XXX
 SG_ SystmStat_IntTempVal_TILS_RH : 0|8@0+ (1,0) [0|0] "SystmStat_IntTempVal_TILS_RH_Uni" Vector__XXX
 SG_ SystmStat_VINStat_TILS_RH : 0|1@0+ (1,0) [0|0] "" Vector__XXX
 SG_ SystmStat_SysCalibStat_TILS_RH : 0|2@0+ (1,0) [0|0] "" Vector__XXX
 SG_ SystmStat_DertngStat_TILS_RH : 0|2@0+ (1,0) [0|0] "" Vector__XXX
 SG_ SystmStat_RefrncRunStat_TILS_RH : 0|2@0+ (1,0) [0|0] "" Vector__XXX
 SG_ SystmStat_Chcksm_LBLS_LH : 0|8@0+ (1,0) [0|0] "" Vector__XXX
 SG_ SystmStat_OvrVltgFail_LBLS_LH : 0|1@0+ (1,0) [0|0] "" Vector__XXX
 SG_ SystmStat_IntrnlSysFail_LBLS_LH : 0|1@0+ (1,0) [0|0] "" Vector__XXX
 SG_ SystmStat_OpnLoadFail_LBLS_LH : 0|1@0+ (1,0) [0|0] "" Vector__XXX
 SG_ SystmStat_ShrtCirctFail_LBLS_LH : 0|1@0+ (1,0) [0|0] "" Vector__XXX
 SG_ SystmStat_MssgCntr_LBLS_LH : 0|4@0+ (1,0) [0|0] "" Vector__XXX
 SG_ SystmStat_OverTempFail_LBLS_LH : 0|1@0+ (1,0) [0|0] "" Vector__XXX
 SG_ SystmStat_MstrMsgFail_LBLS_LH : 0|1@0+ (1,0) [0|0] "" Vector__XXX
 SG_ SystmStat_FanFail_LBLS_LH : 0|1@0+ (1,0) [0|0] "" Vector__XXX
 SG_ SystmStat_CurntCdngFail_LBLS_LH : 0|1@0+ (1,0) [0|0] "" Vector__XXX
 SG_ SystmStat_ExtTempFail_LBLS_LH : 0|1@0+ (1,0) [0|0] "" Vector__XXX
 SG_ SystmStat_IntnlTempFail_LBLS_LH : 0|1@0+ (1,0) [0|0] "" Vector__XXX
 SG_ SystmStat_ActutorFail_LBLS_LH : 0|1@0+ (1,0) [0|0] "" Vector__XXX
 SG_ SystmStat_UndVltgFail_LBLS_LH : 0|1@0+ (1,0) [0|0] "" Vector__XXX
 SG_ SystmStat_FnctnStat_LBLS_LH : 0|1@0+ (1,0) [0|0] "" Vector__XXX
 SG_ SystmStat_R_L_DtctnFail_LBLS_LH : 0|1@0+ (1,0) [0|0] "" Vector__XXX
 SG_ SystmStat_CSorMCFail_LBLS_LH : 0|1@0+ (1,0) [0|0] "" Vector__XXX
 SG_ SystmStat_IncCompFail_LBLS_LH : 0|1@0+ (1,0) [0|0] "" Vector__XXX
 SG_ SystmStat_SpplyVltgVal_LBLS_LH : 0|8@0+ (1,0) [0|0] "SystmStat_SpplyVltgVal_LBLS_LH_U" Vector__XXX
 SG_ SystmStat_ExtTempVal_LBLS_LH : 0|8@0+ (1,0) [0|0] "SystmStat_ExtTempVal_LBLS_LH_Uni" Vector__XXX
 SG_ SystmStat_IntTempVal_LBLS_LH : 0|8@0+ (1,0) [0|0] "SystmStat_IntTempVal_LBLS_LH_Uni" Vector__XXX
 SG_ SystmStat_VINStat_LBLS_LH : 0|1@0+ (1,0) [0|0] "" Vector__XXX
 SG_ SystmStat_SysCalibStat_LBLS_LH : 0|2@0+ (1,0) [0|0] "" Vector__XXX
 SG_ SystmStat_DertngStat_LBLS_LH : 0|2@0+ (1,0) [0|0] "" Vector__XXX
 SG_ SystmStat_RefrncRunStat_LBLS_LH : 0|2@0+ (1,0) [0|0] "" Vector__XXX
 SG_ SystmStat_Chcksm_LBLS_RH : 0|8@0+ (1,0) [0|0] "" Vector__XXX
 SG_ SystmStat_OvrVltgFail_LBLS_RH : 0|1@0+ (1,0) [0|0] "" Vector__XXX
 SG_ SystmStat_IntrnlSysFail_LBLS_RH : 0|1@0+ (1,0) [0|0] "" Vector__XXX
 SG_ SystmStat_OpnLoadFail_LBLS_RH : 0|1@0+ (1,0) [0|0] "" Vector__XXX
 SG_ SystmStat_ShrtCirctFail_LBLS_RH : 0|1@0+ (1,0) [0|0] "" Vector__XXX
 SG_ SystmStat_MssgCntr_LBLS_RH : 0|4@0+ (1,0) [0|0] "" Vector__XXX
 SG_ SystmStat_OverTempFail_LBLS_RH : 0|1@0+ (1,0) [0|0] "" Vector__XXX
 SG_ SystmStat_MstrMsgFail_LBLS_RH : 0|1@0+ (1,0) [0|0] "" Vector__XXX
 SG_ SystmStat_FanFail_LBLS_RH : 0|1@0+ (1,0) [0|0] "" Vector__XXX
 SG_ SystmStat_CurntCdngFail_LBLS_RH : 0|1@0+ (1,0) [0|0] "" Vector__XXX
 SG_ SystmStat_ExtTempFail_LBLS_RH : 0|1@0+ (1,0) [0|0] "" Vector__XXX
 SG_ SystmStat_IntnlTempFail_LBLS_RH : 0|1@0+ (1,0) [0|0] "" Vector__XXX
 SG_ SystmStat_ActutorFail_LBLS_RH : 0|1@0+ (1,0) [0|0] "" Vector__XXX
 SG_ SystmStat_UndVltgFail_LBLS_RH : 0|1@0+ (1,0) [0|0] "" Vector__XXX
 SG_ SystmStat_FnctnStat_LBLS_RH : 0|1@0+ (1,0) [0|0] "" Vector__XXX
 SG_ SystmStat_R_L_DtctnFail_LBLS_RH : 0|1@0+ (1,0) [0|0] "" Vector__XXX
 SG_ SystmStat_CSorMCFail_LBLS_RH : 0|1@0+ (1,0) [0|0] "" Vector__XXX
 SG_ SystmStat_IncCompFail_LBLS_RH : 0|1@0+ (1,0) [0|0] "" Vector__XXX
 SG_ SystmStat_SpplyVltgVal_LBLS_RH : 0|8@0+ (1,0) [0|0] "SystmStat_SpplyVltgVal_LBLS_RH_U" Vector__XXX
 SG_ SystmStat_ExtTempVal_LBLS_RH : 0|8@0+ (1,0) [0|0] "SystmStat_ExtTempVal_LBLS_RH_Uni" Vector__XXX
 SG_ SystmStat_IntTempVal_LBLS_RH : 0|8@0+ (1,0) [0|0] "SystmStat_IntTempVal_LBLS_RH_Uni" Vector__XXX
 SG_ SystmStat_VINStat_LBLS_RH : 0|1@0+ (1,0) [0|0] "" Vector__XXX
 SG_ SystmStat_SysCalibStat_LBLS_RH : 0|2@0+ (1,0) [0|0] "" Vector__XXX
 SG_ SystmStat_DertngStat_LBLS_RH : 0|2@0+ (1,0) [0|0] "" Vector__XXX
 SG_ SystmStat_RefrncRunStat_LBLS_RH : 0|2@0+ (1,0) [0|0] "" Vector__XXX
 SG_ SystmStat_Chcksm_HBLS_LH : 0|8@0+ (1,0) [0|0] "" Vector__XXX
 SG_ SystmStat_OvrVltgFail_HBLS_LH : 0|1@0+ (1,0) [0|0] "" Vector__XXX
 SG_ SystmStat_IntrnlSysFail_HBLS_LH : 0|1@0+ (1,0) [0|0] "" Vector__XXX
 SG_ SystmStat_OpnLoadFail_HBLS_LH : 0|1@0+ (1,0) [0|0] "" Vector__XXX
 SG_ SystmStat_ShrtCirctFail_HBLS_LH : 0|1@0+ (1,0) [0|0] "" Vector__XXX
 SG_ SystmStat_MssgCntr_HBLS_LH : 0|4@0+ (1,0) [0|0] "" Vector__XXX
 SG_ SystmStat_OverTempFail_HBLS_LH : 0|1@0+ (1,0) [0|0] "" Vector__XXX
 SG_ SystmStat_MstrMsgFail_HBLS_LH : 0|1@0+ (1,0) [0|0] "" Vector__XXX
 SG_ SystmStat_FanFail_HBLS_LH : 0|1@0+ (1,0) [0|0] "" Vector__XXX
 SG_ SystmStat_CurntCdngFail_HBLS_LH : 0|1@0+ (1,0) [0|0] "" Vector__XXX
 SG_ SystmStat_ExtTempFail_HBLS_LH : 0|1@0+ (1,0) [0|0] "" Vector__XXX
 SG_ SystmStat_IntnlTempFail_HBLS_LH : 0|1@0+ (1,0) [0|0] "" Vector__XXX
 SG_ SystmStat_ActutorFail_HBLS_LH : 0|1@0+ (1,0) [0|0] "" Vector__XXX
 SG_ SystmStat_UndVltgFail_HBLS_LH : 0|1@0+ (1,0) [0|0] "" Vector__XXX
 SG_ SystmStat_FnctnStat_HBLS_LH : 0|1@0+ (1,0) [0|1] "Enum" Vector__XXX
 SG_ SystmStat_R_L_DtctnFail_HBLS_LH : 0|1@0+ (1,0) [0|0] "" Vector__XXX
 SG_ SystmStat_CSorMCFail_HBLS_LH : 0|1@0+ (1,0) [0|0] "" Vector__XXX
 SG_ SystmStat_IncCompFail_HBLS_LH : 0|1@0+ (1,0) [0|0] "" Vector__XXX
 SG_ SystmStat_SpplyVltgVal_HBLS_LH : 0|8@0+ (1,0) [0|0] "SystmStat_SpplyVltgVal_HBLS_LH_U" Vector__XXX
 SG_ SystmStat_ExtTempVal_HBLS_LH : 0|8@0+ (1,0) [0|0] "SystmStat_ExtTempVal_HBLS_LH_Uni" Vector__XXX
 SG_ SystmStat_IntTempVal_HBLS_LH : 0|8@0+ (1,0) [0|0] "SystmStat_IntTempVal_HBLS_LH_Uni" Vector__XXX
 SG_ SystmStat_VINStat_HBLS_LH : 0|1@0+ (1,0) [0|0] "" Vector__XXX
 SG_ SystmStat_SysCalibStat_HBLS_LH : 0|2@0+ (1,0) [0|0] "" Vector__XXX
 SG_ SystmStat_DertngStat_HBLS_LH : 0|2@0+ (1,0) [0|0] "" Vector__XXX
 SG_ SystmStat_RefrncRunStat_HBLS_LH : 0|2@0+ (1,0) [0|0] "" Vector__XXX
 SG_ SystmStat_Chcksm_HBLS_RH : 0|8@0+ (1,0) [0|0] "" Vector__XXX
 SG_ SystmStat_OvrVltgFail_HBLS_RH : 0|1@0+ (1,0) [0|0] "" Vector__XXX
 SG_ SystmStat_IntrnlSysFail_HBLS_RH : 0|1@0+ (1,0) [0|0] "" Vector__XXX
 SG_ SystmStat_OpnLoadFail_HBLS_RH : 0|1@0+ (1,0) [0|0] "" Vector__XXX
 SG_ SystmStat_ShrtCirctFail_HBLS_RH : 0|1@0+ (1,0) [0|0] "" Vector__XXX
 SG_ SystmStat_MssgCntr_HBLS_RH : 0|4@0+ (1,0) [0|0] "" Vector__XXX
 SG_ SystmStat_OverTempFail_HBLS_RH : 0|1@0+ (1,0) [0|0] "" Vector__XXX
 SG_ SystmStat_MstrMsgFail_HBLS_RH : 0|1@0+ (1,0) [0|0] "" Vector__XXX
 SG_ SystmStat_FanFail_HBLS_RH : 0|1@0+ (1,0) [0|0] "" Vector__XXX
 SG_ SystmStat_CurntCdngFail_HBLS_RH : 0|1@0+ (1,0) [0|0] "" Vector__XXX
 SG_ SystmStat_ExtTempFail_HBLS_RH : 0|1@0+ (1,0) [0|0] "" Vector__XXX
 SG_ SystmStat_IntnlTempFail_HBLS_RH : 0|1@0+ (1,0) [0|0] "" Vector__XXX
 SG_ SystmStat_ActutorFail_HBLS_RH : 0|1@0+ (1,0) [0|0] "" Vector__XXX
 SG_ SystmStat_UndVltgFail_HBLS_RH : 0|1@0+ (1,0) [0|0] "" Vector__XXX
 SG_ SystmStat_FnctnStat_HBLS_RH : 0|1@0+ (1,0) [0|0] "" Vector__XXX
 SG_ SystmStat_R_L_DtctnFail_HBLS_RH : 0|1@0+ (1,0) [0|0] "" Vector__XXX
 SG_ SystmStat_CSorMCFail_HBLS_RH : 0|1@0+ (1,0) [0|0] "" Vector__XXX
 SG_ SystmStat_IncCompFail_HBLS_RH : 0|1@0+ (1,0) [0|0] "" Vector__XXX
 SG_ SystmStat_SpplyVltgVal_HBLS_RH : 0|8@0+ (1,0) [0|0] "SystmStat_SpplyVltgVal_HBLS_RH_U" Vector__XXX
 SG_ SystmStat_ExtTempVal_HBLS_RH : 0|8@0+ (1,0) [0|0] "SystmStat_ExtTempVal_HBLS_RH_Uni" Vector__XXX
 SG_ SystmStat_IntTempVal_HBLS_RH : 0|8@0+ (1,0) [0|0] "SystmStat_IntTempVal_HBLS_RH_Uni" Vector__XXX
 SG_ SystmStat_VINStat_HBLS_RH : 0|1@0+ (1,0) [0|0] "" Vector__XXX
 SG_ SystmStat_SysCalibStat_HBLS_RH : 0|2@0+ (1,0) [0|0] "" Vector__XXX
 SG_ SystmStat_DertngStat_HBLS_RH : 0|2@0+ (1,0) [0|0] "" Vector__XXX
 SG_ SystmStat_RefrncRunStat_HBLS_RH : 0|2@0+ (1,0) [0|0] "" Vector__XXX
 SG_ RtAuxDrlPlCtrlSts : 0|3@0+ (1,0) [0|7] "" Vector__XXX
 SG_ RtAuxLbCtrlSts : 0|3@0+ (1,0) [0|7] "" Vector__XXX
 SG_ RtDrlPlCtrlSts : 0|3@0+ (1,0) [0|7] "" Vector__XXX
 SG_ RtLdmConf : 0|2@0+ (1,0) [0|0] "" Vector__XXX
 SG_ RtFrtTrnCtrlSts : 0|2@0+ (1,0) [0|3] "" Vector__XXX
 SG_ RtBndCtrlSts : 0|1@0+ (1,0) [0|0] "" Vector__XXX
 SG_ RtBndActDim : 0|7@0+ (1,0) [0|127] "" Vector__XXX
 SG_ RtHgBmCtrlSts : 0|3@0+ (1,0) [0|7] "" Vector__XXX
 SG_ RtLwBmCtrlSts : 0|3@0+ (1,0) [0|7] "" Vector__XXX
 SG_ RtHdlmpLgtShowWrkSts : 0|5@0+ (1,0) [0|31] "" Vector__XXX
 SG_ LftAuxDrlPlCtrlSts : 0|2@0+ (1,0) [0|3] "" Vector__XXX
 SG_ LftAuxLbCtrlSts : 0|3@0+ (1,0) [0|7] "" Vector__XXX
 SG_ LftDrlPlCtrlSts : 0|3@0+ (1,0) [0|7] "" Vector__XXX
 SG_ LftLdmConf : 0|2@0+ (1,0) [0|0] "" Vector__XXX
 SG_ LftFrtTrnCtrlSts : 0|3@0+ (1,0) [0|7] "" Vector__XXX
 SG_ LftBndCtrlSts : 0|1@0+ (1,0) [0|0] "" Vector__XXX
 SG_ LftBndActDim : 0|7@0+ (1,0) [0|127] "" Vector__XXX
 SG_ LftHgBmCtrlSts : 0|3@0+ (1,0) [0|7] "" Vector__XXX
 SG_ LftLwBmCtrlSts : 0|3@0+ (1,0) [0|7] "" Vector__XXX
 SG_ LftHdlmpLgtShowWrkSts : 0|5@0+ (1,0) [0|31] "" Vector__XXX
 SG_ RtLdmPwrChn9Flt : 0|1@0+ (1,0) [0|0] "" Vector__XXX
 SG_ RtLdmUnderVltgFlt : 0|1@0+ (1,0) [0|0] "" Vector__XXX
 SG_ RtLdmOverVltgFlt : 0|1@0+ (1,0) [0|0] "" Vector__XXX
 SG_ RtLdmBstFlt : 0|1@0+ (1,0) [0|0] "" Vector__XXX
 SG_ RtLdmUartCan2Flt : 0|2@0+ (1,0) [0|3] "" Vector__XXX
 SG_ RtLdmUartCan1Flt : 0|2@0+ (1,0) [0|3] "" Vector__XXX
 SG_ RtLdmMtrDrvLst : 0|1@0+ (1,0) [0|0] "" Vector__XXX
 SG_ RtLdmBcmLst : 0|1@0+ (1,0) [0|0] "" Vector__XXX
 SG_ RtLdmSubCanBusOff : 0|1@0+ (1,0) [0|0] "" Vector__XXX
 SG_ RtLdmMtrxLedFlt : 0|8@0+ (1,0) [0|0] "" Vector__XXX
 SG_ RtLdmMtrxLst : 0|8@0+ (1,0) [0|0] "" Vector__XXX
 SG_ RtLdmPwrChnFlt : 0|8@0+ (1,0) [0|0] "" Vector__XXX
 SG_ RtLdmNtcFlt : 0|8@0+ (1,0) [0|0] "" Vector__XXX
 SG_ RtLdmBinFlt : 0|8@0+ (1,0) [0|0] "" Vector__XXX
 SG_ LftLdmPwrChn9Flt : 0|1@0+ (1,0) [0|0] "" Vector__XXX
 SG_ LftLdmUnderVltgFlt : 0|1@0+ (1,0) [0|0] "" Vector__XXX
 SG_ LftLdmOverVltgFlt : 0|1@0+ (1,0) [0|0] "" Vector__XXX
 SG_ LftLdmBstFlt : 0|1@0+ (1,0) [0|0] "" Vector__XXX
 SG_ LftLdmUartCan2Flt : 0|2@0+ (1,0) [0|3] "" Vector__XXX
 SG_ LftLdmUartCan1Flt : 0|2@0+ (1,0) [0|3] "" Vector__XXX
 SG_ LftLdmMtrDrvLst : 0|1@0+ (1,0) [0|0] "" Vector__XXX
 SG_ LftLdmBcmLst : 0|1@0+ (1,0) [0|0] "" Vector__XXX
 SG_ LftLdmSubCanBusOff : 0|1@0+ (1,0) [0|0] "" Vector__XXX
 SG_ LftLdmMtrxLedFlt : 0|8@0+ (1,0) [0|0] "" Vector__XXX
 SG_ LftLdmMtrxLst : 0|8@0+ (1,0) [0|0] "" Vector__XXX
 SG_ LftLdmPwrChnFlt : 0|8@0+ (1,0) [0|0] "" Vector__XXX
 SG_ LftLdmNtcFlt : 0|8@0+ (1,0) [0|0] "" Vector__XXX
 SG_ LftLdmBinFlt : 0|8@0+ (1,0) [0|0] "" Vector__XXX
 SG_ LftPlCksm : 0|8@0+ (1,0) [0|255] "" Vector__XXX
 SG_ RtPlCksm : 0|8@0+ (1,0) [0|255] "" Vector__XXX
 SG_ RtBndCmd : 0|8@0+ (1,0) [0|0] "" Vector__XXX
 SG_ LftBndCmd : 0|8@0+ (1,0) [0|0] "" Vector__XXX
 SG_ HgBmMdSelt : 0|3@0+ (1,0) [0|7] "" Vector__XXX
 SG_ SlpRdy : 0|1@0+ (1,0) [0|0] "" Vector__XXX
 SG_ LghtDstrbtnSelt : 0|4@0+ (1,0) [0|0] "" Vector__XXX
 SG_ LDS_GFHBLghtDstrbtnMtrwyLvl_3_RH : 0|1@0+ (1,0) [0|1] "" Vector__XXX
 SG_ LDS_GFHBLghtDstrbtnMtrwyLvl_2_RH : 0|1@0+ (1,0) [0|1] "" Vector__XXX
 SG_ LDS_GFHBLghtDstrbtnMtrwyLvl_3_LH : 0|1@0+ (1,0) [0|1] "" Vector__XXX
 SG_ LDS_GFHBLghtDstrbtnMtrwyLvl_2_LH : 0|1@0+ (1,0) [0|1] "" Vector__XXX
 SG_ LDS_MtrwyLghtDstrbtnLvl_E0_RH : 0|1@0+ (1,0) [0|1] "" Vector__XXX
 SG_ LDS_MtrwyLghtDstrbtnLvl_E3_LH : 0|1@0+ (1,0) [0|1] "" Vector__XXX
 SG_ LDS_MtrwyLghtDstrbtnLvl_E3_RH : 0|1@0+ (1,0) [0|1] "" Vector__XXX
 SG_ LDS_MtrwyLghtDstrbtnLvl_E1_RH : 0|1@0+ (1,0) [0|1] "" Vector__XXX
 SG_ Resp_LDML_DgnInf : 0|64@0+ (1,0) [0|1.84467440737096E+019] "" Vector__XXX
 SG_ Req_LDMR_DgnInf : 0|64@0+ (1,0) [0|1.84467440737096E+019] "" Vector__XXX
 SG_ Req_LDML_DgnInf : 0|64@0+ (1,0) [0|1.84467440737096E+019] "" Vector__XXX
 SG_ LghtDistrbMd : 0|32@0+ (1,0) [0|4294967295] "" Vector__XXX
 SG_ LghtDistrCksm : 0|8@0+ (1,0) [0|255] "" Vector__XXX
 SG_ LftPrkLmpDimValue : 0|7@0+ (1,0) [0|0] "" Vector__XXX
 SG_ LftPrkLmpCmd : 0|3@0+ (1,0) [0|0] "" Vector__XXX
 SG_ LftFrtTrnLmpCmd : 0|3@0+ (1,0) [0|0] "" Vector__XXX
 SG_ LftDRLDimValue : 0|7@0+ (1,0) [0|0] "" Vector__XXX
 SG_ RtPrkLmpDimValue : 0|7@0+ (1,0) [0|0] "" Vector__XXX
 SG_ RtPrkLmpCmd : 0|3@0+ (1,0) [0|7] "" Vector__XXX
 SG_ RtFrtTrnLmpCmd : 0|3@0+ (1,0) [0|7] "" Vector__XXX
 SG_ RtDRLDimValue : 0|7@0+ (1,0) [0|0] "" Vector__XXX
 SG_ RtDRLCmd : 0|3@0+ (1,0) [0|7] "" Vector__XXX
 SG_ LftDRLCmd : 0|3@0+ (1,0) [0|0] "" Vector__XXX
 SG_ LftHgBmDimValue : 0|7@0+ (1,0) [0|0] "" Vector__XXX
 SG_ LftHgBmCmd : 0|3@0+ (1,0) [0|0] "" Vector__XXX
 SG_ RtHgBmDimValue : 0|7@0+ (1,0) [0|0] "" Vector__XXX
 SG_ RtHgBmCmd : 0|3@0+ (1,0) [0|0] "" Vector__XXX
 SG_ RtLowBmDimValue : 0|7@0+ (1,0) [0|0] "" Vector__XXX
 SG_ RtLowBmCmd : 0|3@0+ (1,0) [0|0] "" Vector__XXX
 SG_ LftLowBmDimValue : 0|7@0+ (1,0) [0|0] "" Vector__XXX
 SG_ LftLowBmCmd : 0|3@0+ (1,0) [0|0] "" Vector__XXX
 SG_ FrntShwType : 0|3@0+ (1,0) [0|0] "" Vector__XXX
 SG_ FrntShwMd : 0|5@0+ (1,0) [0|0] "" Vector__XXX
 SG_ NMData7 : 0|8@0+ (1,0) [0|0] "" Vector__XXX
 SG_ NMData6 : 0|8@0+ (1,0) [0|0] "" Vector__XXX
 SG_ NMData5 : 0|8@0+ (1,0) [0|0] "" Vector__XXX
 SG_ NMData4 : 0|8@0+ (1,0) [0|0] "" Vector__XXX
 SG_ NMData3 : 0|8@0+ (1,0) [0|0] "" Vector__XXX
 SG_ NMData2 : 0|8@0+ (1,0) [0|0] "" Vector__XXX
 SG_ NMData1 : 0|8@0+ (1,0) [0|0] "" Vector__XXX
 SG_ NMData0 : 0|8@0+ (1,0) [0|0] "" Vector__XXX
 SG_ RespFromECU1_SoftwareProg_LH : 0|64@1+ (1,0) [0|1.84467440737096E+019] "" Vector__XXX
 SG_ ReqToECU3_SoftwareProg_LH : 0|64@1+ (1,0) [0|1.84467440737096E+019] "" Vector__XXX
 SG_ RespFromECU3_SoftwareProg_RH : 0|64@1+ (1,0) [0|1.84467440737096E+019] "" Vector__XXX
 SG_ ReqToECU1_SoftwareProg_LH : 0|64@1+ (1,0) [0|1.84467440737096E+019] "" Vector__XXX
 SG_ ReqToECU1_SoftwareProg_RH : 0|64@1+ (1,0) [0|1.84467440737096E+019] "" Vector__XXX
 SG_ RespFromECU3_SoftwareProg_LH : 0|64@1+ (1,0) [0|1.84467440737096E+019] "" Vector__XXX
 SG_ ReqToECU3_SoftwareProg_RH : 0|64@1+ (1,0) [0|1.84467440737096E+019] "" Vector__XXX
 SG_ LftLdm2Info : 0|56@0+ (1,0) [0|7.20575940379279E+016] "" Vector__XXX
 SG_ LftLdm2InfoIdx : 0|8@0+ (1,0) [0|255] "" Vector__XXX
 SG_ RtLdm2Info : 0|56@0+ (1,0) [0|7.20575940379279E+016] "" Vector__XXX
 SG_ RtLdm2InfoIdx : 0|8@0+ (1,0) [0|255] "" Vector__XXX
 SG_ LftLdm3InfoIdx : 0|8@0+ (1,0) [0|255] "" Vector__XXX
 SG_ LftLdm3Info : 0|56@0+ (1,0) [0|7.20575940379279E+016] "" Vector__XXX
 SG_ RtLdm3InfoIdx : 0|8@0+ (1,0) [0|255] "" Vector__XXX
 SG_ RtLdm3Info : 0|56@0+ (1,0) [0|7.20575940379279E+016] "" Vector__XXX
 SG_ LftFuncReq_8 : 0|1@0+ (1,0) [0|1] "" Vector__XXX
 SG_ LftFuncReq_7 : 0|1@0+ (1,0) [0|1] "" Vector__XXX
 SG_ LftFuncReq_6 : 0|1@0+ (1,0) [0|1] "" Vector__XXX
 SG_ LftFuncReq_5 : 0|1@0+ (1,0) [0|1] "" Vector__XXX
 SG_ LftFuncReq_4 : 0|1@0+ (1,0) [0|1] "" Vector__XXX
 SG_ LftFuncReq_3 : 0|1@0+ (1,0) [0|1] "" Vector__XXX
 SG_ LftFuncReq_2 : 0|1@0+ (1,0) [0|1] "" Vector__XXX
 SG_ RtFuncReq_8 : 0|1@0+ (1,0) [0|1] "" Vector__XXX
 SG_ RtFuncReq_7 : 0|1@0+ (1,0) [0|1] "" Vector__XXX
 SG_ RtFuncReq_6 : 0|1@0+ (1,0) [0|1] "" Vector__XXX
 SG_ RtFuncReq_5 : 0|1@0+ (1,0) [0|1] "" Vector__XXX
 SG_ RtFuncReq_4 : 0|1@0+ (1,0) [0|1] "" Vector__XXX
 SG_ RtFuncReq_3 : 0|1@0+ (1,0) [0|1] "" Vector__XXX
 SG_ RtFuncReq_2 : 0|1@0+ (1,0) [0|1] "" Vector__XXX
 SG_ VIN : 0|56@0+ (1,0) [0|7.20575940379279E+016] "" Vector__XXX
 SG_ LftRoutineCtrl : 0|1@0+ (1,0) [0|1] "" Vector__XXX
 SG_ LftFuncReq : 0|9@0+ (1,0) [0|1] "" Vector__XXX
 SG_ RtRoutineCtrl : 0|1@0+ (1,0) [0|1] "" Vector__XXX
 SG_ RtFuncReq : 0|8@0+ (1,0) [0|1] "" Vector__XXX
 SG_ LftDiagLed8 : 0|1@0+ (1,0) [0|0] "" Vector__XXX
 SG_ LftDiagLed7 : 0|1@0+ (1,0) [0|0] "" Vector__XXX
 SG_ LftDiagLed6 : 0|1@0+ (1,0) [0|0] "" Vector__XXX
 SG_ LftDiagLed5 : 0|1@0+ (1,0) [0|0] "" Vector__XXX
 SG_ LftDiagLed4 : 0|1@0+ (1,0) [0|0] "" Vector__XXX
 SG_ LftDiagLed3 : 0|1@0+ (1,0) [0|0] "" Vector__XXX
 SG_ LftDiagLed2 : 0|1@0+ (1,0) [0|0] "" Vector__XXX
 SG_ RtDiagLed8 : 0|1@0+ (1,0) [0|0] "" Vector__XXX
 SG_ RtDiagLed7 : 0|1@0+ (1,0) [0|0] "" Vector__XXX
 SG_ RtDiagLed6 : 0|1@0+ (1,0) [0|0] "" Vector__XXX
 SG_ RtDiagLed5 : 0|1@0+ (1,0) [0|0] "" Vector__XXX
 SG_ RtDiagLed4 : 0|1@0+ (1,0) [0|0] "" Vector__XXX
 SG_ RtDiagLed3 : 0|1@0+ (1,0) [0|0] "" Vector__XXX
 SG_ RtDiagLed2 : 0|1@0+ (1,0) [0|0] "" Vector__XXX

BO_ 480 GlareFreeHighBeamControl_LH: 2 AFL_AHL
 SG_ LftDiagLed : 15|8@0+ (1,0) [0|0] ""  LDM_LH
 SG_ LftRoutineCtrl : 7|1@0+ (1,0) [0|0] ""  LDM_LH

BO_ 370 AHL_AFL_NM_Frame: 8 AFL_AHL
 SG_ NM_Signal : 23|48@0+ (1,0) [0|0] ""  LDM_LH,LDM_RH

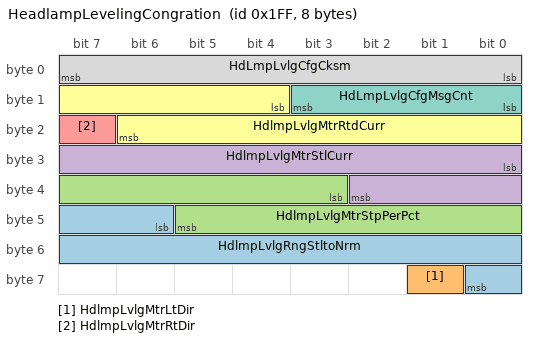
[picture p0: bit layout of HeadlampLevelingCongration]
BO_ 511 HeadlampLevelingCongration: 8 AFL_AHL
 SG_ HdlmpLvlgRngStltoNrm : 46|11@1- (0.01,0) [-10.24|10.23] ""  LDM_RH,LDM_LH
 SG_ HdlmpLvlgMtrLtDir : 57|1@1+ (1,0) [0|1] ""  LDM_RH,LDM_LH
 SG_ HdlmpLvlgMtrStpPerPct : 35|11@1+ (1,0) [0|0] ""  LDM_RH,LDM_LH
 SG_ HdlmpLvlgMtrStlCurr : 24|11@1+ (1,0) [0|2048] ""  LDM_RH,LDM_LH
 SG_ HdlmpLvlgMtrRtDir : 23|1@1+ (1,0) [0|1] ""  LDM_LH,LDM_RH
 SG_ HdlmpLvlgMtrRtdCurr : 12|11@1+ (1,0) [0|2048] ""  LDM_RH,LDM_LH
 SG_ HdLmpLvlgCfgMsgCnt : 8|4@1+ (1,0) [0|15] ""  LDM_RH,LDM_LH
 SG_ HdLmpLvlgCfgCksm : 0|8@1+ (1,0) [0|255] ""  LDM_RH,LDM_LH

CM_ BO_ 3221225472 "This is a message for not used signals, created by Vector CANdb++ DBC OLE DB Provider.";
CM_ SG_ 3221225472 SystmStat_OvrVltgFail_GFHB_LH "System Status Glare Free High Beam Left Headlamp Information : Left Headlamp Glare Free High Beam Over Voltage Failed";
CM_ SG_ 3221225472 SystmStat_IntrnlSysFail_GFHB_LH "System Status Glare Free High Beam Left Headlamp Information : Left Headlamp Glare Free High Beam Internal System Failed";
CM_ SG_ 3221225472 SystmStat_OpnLoadFail_GFHB_LH "System Status Glare Free High Beam Left Headlamp Information : Left Headlamp Glare Free High Beam Open Load Failed";
CM_ SG_ 3221225472 SystmStat_ShrtCirctFail_GFHB_LH "System Status Glare Free High Beam Left Headlamp Information : Left Headlamp Glare Free High Beam Short Circuit Failed";
CM_ SG_ 3221225472 SystmStat_OverTempFail_GFHB_LH "System Status Glare Free High Beam Left Headlamp Information : Left Headlamp Glare Free High Beam Over Temperature Failed";
CM_ SG_ 3221225472 SystmStat_MstrMsgFail_GFHB_LH "System Status Glare Free High Beam Left Headlamp Information : Left Headlamp Glare Free High Beam Master ECU Message Failed";
CM_ SG_ 3221225472 SystmStat_FanFail_GFHB_LH "System Status Glare Free High Beam Left Headlamp Information : Left Headlamp Glare Free High Beam FAN Failed";
CM_ SG_ 3221225472 SystmStat_CurntCdngFail_GFHB_LH "System Status Glare Free High Beam Left Headlamp Information : Left Headlamp Glare Free High Beam Current Coding Failed";
CM_ SG_ 3221225472 SystmStat_ExtTempFail_GFHB_LH "System Status Glare Free High Beam Left Headlamp Information : Left Headlamp Glare Free High Beam External Temperature Failed";
CM_ SG_ 3221225472 SystmStat_IntnlTempFail_GFHB_LH "System Status Glare Free High Beam Left Headlamp Information : Left Headlamp Glare Free High Beam Internal Temperature Failed";
CM_ SG_ 3221225472 SystmStat_ActutorFail_GFHB_LH "System Status Glare Free High Beam Left Headlamp Information : Left Headlamp Glare Free High Beam Actuator Failed";
CM_ SG_ 3221225472 SystmStat_UndVltgFail_GFHB_LH "System Status Glare Free High Beam Left Headlamp Information : Left Headlamp Glare Free High Beam Under Voltage Failed";
CM_ SG_ 3221225472 SystmStat_FnctnStat_GFHB_LH "System Status Glare Free High Beam Left Headlamp Information : Left Headlamp Glare Free High Beam Function Status";
CM_ SG_ 3221225472 SystmStat_R_L_DtctnFail_GFHB_LH "System Status Glare Free High Beam Left Headlamp Information : Left Headlamp Glare Free High Beam Right/Left Side Detection Failed";
CM_ SG_ 3221225472 SystmStat_CSorMCFail_GFHB_LH "System Status Glare Free High Beam Left Headlamp Information : Left Headlamp Glare Free High Beam Cksm or Message Counter Failed";
CM_ SG_ 3221225472 SystmStat_IncCompFail_GFHB_LH "System Status Glare Free High Beam Left Headlamp Information : Left Headlamp Glare Free High Beam Incorrect Component Failed";
CM_ SG_ 3221225472 SystmStat_OvrVltgFail_GFHB_RH "System Status Glare Free High Beam Right Headlamp Information : Right Headlamp Glare Free High Beam Over Voltage Failed";
CM_ SG_ 3221225472 SystmStat_IntrnlSysFail_GFHB_RH "System Status Glare Free High Beam Right Headlamp Information : Right Headlamp Glare Free High Beam Internal System Failed";
CM_ SG_ 3221225472 SystmStat_OpnLoadFail_GFHB_RH "System Status Glare Free High Beam Right Headlamp Information : Right Headlamp Glare Free High Beam Open Load Failed";
CM_ SG_ 3221225472 SystmStat_ShrtCirctFail_GFHB_RH "System Status Glare Free High Beam Right Headlamp Information : Right Headlamp Glare Free High Beam Short Circuit Failed";
CM_ SG_ 3221225472 SystmStat_OverTempFail_GFHB_RH "System Status Glare Free High Beam Right Headlamp Information : Right Headlamp Glare Free High Beam Over Temperature Failed";
CM_ SG_ 3221225472 SystmStat_MstrMsgFail_GFHB_RH "System Status Glare Free High Beam Right Headlamp Information : Right Headlamp Glare Free High Beam Master ECU Message Failed";
CM_ SG_ 3221225472 SystmStat_FanFail_GFHB_RH "System Status Glare Free High Beam Right Headlamp Information : Right Headlamp Glare Free High Beam FAN Failed";
CM_ SG_ 3221225472 SystmStat_CurntCdngFail_GFHB_RH "System Status Glare Free High Beam Right Headlamp Information : Right Headlamp Glare Free High Beam Current Coding Failed";
CM_ SG_ 3221225472 SystmStat_ExtTempFail_GFHB_RH "System Status Glare Free High Beam Right Headlamp Information : Right Headlamp Glare Free High Beam External Temperature Failed";
CM_ SG_ 3221225472 SystmStat_IntnlTempFail_GFHB_RH "System Status Glare Free High Beam Right Headlamp Information : Right Headlamp Glare Free High Beam Internal Temperature Failed";
CM_ SG_ 3221225472 SystmStat_ActutorFail_GFHB_RH "System Status Glare Free High Beam Right Headlamp Information : Right Headlamp Glare Free High Beam Actuator Failed";
CM_ SG_ 3221225472 SystmStat_UndVltgFail_GFHB_RH "System Status Glare Free High Beam Right Headlamp Information : Right Headlamp Glare Free High Beam Under Voltage Failed";
CM_ SG_ 3221225472 SystmStat_FnctnStat_GFHB_RH "System Status Glare Free High Beam Right Headlamp Information : Right Headlamp Glare Free High Beam Function Status";
CM_ SG_ 3221225472 SystmStat_R_L_DtctnFail_GFHB_RH "System Status Glare Free High Beam Right Headlamp Information : Right Headlamp Glare Free High Beam Right/Left Side Detection Failed";
CM_ SG_ 3221225472 SystmStat_CSorMCFail_GFHB_RH "System Status Glare Free High Beam Right Headlamp Information : Right Headlamp Glare Free High Beam Cksm or Message Counter Failed";
CM_ SG_ 3221225472 SystmStat_IncCompFail_GFHB_RH "System Status Glare Free High Beam Right Headlamp Information : Right Headlamp Glare Free High Beam Incorrect Component Failed";
CM_ SG_ 3221225472 SystmStat_OvrVltgFail_LDS_LH "System Status Light Distribution Left Headlamp Information : Left Headlamp Light Distribution Over Voltage Failed";
CM_ SG_ 3221225472 SystmStat_IntrnlSysFail_LDS_LH "System Status Light Distribution Left Headlamp Information : Left Headlamp Light Distribution Internal System Failed";
CM_ SG_ 3221225472 SystmStat_OpnLoadFail_LDS_LH "System Status Light Distribution Left Headlamp Information : Left Headlamp Light Distribution Open Load Failed";
CM_ SG_ 3221225472 SystmStat_ShrtCirctFail_LDS_LH "System Status Light Distribution Left Headlamp Information : Left Headlamp Light Distribution Short Circuit Failed";
CM_ SG_ 3221225472 SystmStat_OverTempFail_LDS_LH "System Status Light Distribution Left Headlamp Information : Left Headlamp Light Distribution Over Temperature Failed";
CM_ SG_ 3221225472 SystmStat_MstrMsgFail_LDS_LH "System Status Light Distribution Left Headlamp Information : Left Headlamp Light Distribution Master ECU Message Failed";
CM_ SG_ 3221225472 SystmStat_FanFail_LDS_LH "System Status Light Distribution Left Headlamp Information : Left Headlamp Light Distribution FAN Failed";
CM_ SG_ 3221225472 SystmStat_CurntCdngFail_LDS_LH "System Status Light Distribution Left Headlamp Information : Left Headlamp Light Distribution Current Coding Failed";
CM_ SG_ 3221225472 SystmStat_ExtTempFail_LDS_LH "System Status Light Distribution Left Headlamp Information : Left Headlamp Light Distribution External Temperature Failed";
CM_ SG_ 3221225472 SystmStat_IntnlTempFail_LDS_LH "System Status Light Distribution Left Headlamp Information : Left Headlamp Light Distribution Internal Temperature Failed";
CM_ SG_ 3221225472 SystmStat_ActutorFail_LDS_LH "System Status Light Distribution Left Headlamp Information : Left Headlamp Light Distribution Actuator Failed";
CM_ SG_ 3221225472 SystmStat_UndVltgFail_LDS_LH "System Status Light Distribution Left Headlamp Information : Left Headlamp Light Distribution Under Voltage Failed";
CM_ SG_ 3221225472 SystmStat_FnctnStat_LDS_LH "System Status Light Distribution Left Headlamp Information : Left Headlamp Light Distribution Function Status";
CM_ SG_ 3221225472 SystmStat_R_L_DtctnFail_LDS_LH "System Status Light Distribution Left Headlamp Information : Left Headlamp Light Distribution Right/Left Side Detection Failed";
CM_ SG_ 3221225472 SystmStat_CSorMCFail_LDS_LH "System Status Light Distribution Left Headlamp Information : Left Headlamp Light Distribution Cksm or Message Counter Failed";
CM_ SG_ 3221225472 SystmStat_IncCompFail_LDS_LH "System Status Light Distribution Left Headlamp Information : Left Headlamp Light Distribution Incorrect Component Failed";
CM_ SG_ 3221225472 SystmStat_OvrVltgFail_LDS_RH "System Status Light Distribution Right Headlamp Information : Right Headlamp Light Distribution Over Voltage Failed";
CM_ SG_ 3221225472 SystmStat_IntrnlSysFail_LDS_RH "System Status Light Distribution Right Headlamp Information : Right Headlamp Light Distribution Internal System Failed";
CM_ SG_ 3221225472 SystmStat_OpnLoadFail_LDS_RH "System Status Light Distribution Right Headlamp Information : Right Headlamp Light Distribution Open Load Failed";
CM_ SG_ 3221225472 SystmStat_ShrtCirctFail_LDS_RH "System Status Light Distribution Right Headlamp Information : Right Headlamp Light Distribution Short Circuit Failed";
CM_ SG_ 3221225472 SystmStat_OverTempFail_LDS_RH "System Status Light Distribution Right Headlamp Information : Right Headlamp Light Distribution Over Temperature Failed";
CM_ SG_ 3221225472 SystmStat_MstrMsgFail_LDS_RH "System Status Light Distribution Right Headlamp Information : Right Headlamp Light Distribution Master ECU Message Failed";
CM_ SG_ 3221225472 SystmStat_FanFail_LDS_RH "System Status Light Distribution Right Headlamp Information : Right Headlamp Light Distribution FAN Failed";
CM_ SG_ 3221225472 SystmStat_CurntCdngFail_LDS_RH "System Status Light Distribution Right Headlamp Information : Right Headlamp Light Distribution Current Coding Failed";
CM_ SG_ 3221225472 SystmStat_ExtTempFail_LDS_RH "System Status Light Distribution Right Headlamp Information : Right Headlamp Light Distribution External Temperature Failed";
CM_ SG_ 3221225472 SystmStat_IntnlTempFail_LDS_RH "System Status Light Distribution Right Headlamp Information : Right Headlamp Light Distribution Internal Temperature Failed";
CM_ SG_ 3221225472 SystmStat_ActutorFail_LDS_RH "System Status Light Distribution Right Headlamp Information : Right Headlamp Light Distribution Actuator Failed";
CM_ SG_ 3221225472 SystmStat_UndVltgFail_LDS_RH "System Status Light Distribution Right Headlamp Information : Right Headlamp Light Distribution Under Voltage Failed";
CM_ SG_ 3221225472 SystmStat_FnctnStat_LDS_RH "System Status Light Distribution Right Headlamp Information : Right Headlamp Light Distribution Function Status";
CM_ SG_ 3221225472 SystmStat_R_L_DtctnFail_LDS_RH "System Status Light Distribution Right Headlamp Information : Right Headlamp Light Distribution Right/Left Side Detection Failed";
CM_ SG_ 3221225472 SystmStat_CSorMCFail_LDS_RH "System Status Light Distribution Right Headlamp Information : Right Headlamp Light Distribution Cksm or Message Counter Failed";
CM_ SG_ 3221225472 SystmStat_IncCompFail_LDS_RH "System Status Light Distribution Right Headlamp Information : Right Headlamp Light Distribution Incorrect Component Failed";
CM_ SG_ 3221225472 SystmStat_OvrVltgFail_SBLS_LH "System Status Static Bending Light/Cornering Light Left Headlamp Information : Left Headlamp Static Bending Light Over Voltage Failed";
CM_ SG_ 3221225472 SystmStat_IntrnlSysFail_SBLS_LH "System Status Static Bending Light/Cornering Light Left Headlamp Information : Left Headlamp Static Bending Light Internal System Failed";
CM_ SG_ 3221225472 SystmStat_OpnLoadFail_SBLS_LH "System Status Static Bending Light/Cornering Light Left Headlamp Information : Left Headlamp Static Bending Light Open Load Failed";
CM_ SG_ 3221225472 SystmStat_ShrtCirctFail_SBLS_LH "System Status Static Bending Light/Cornering Light Left Headlamp Information : Left Headlamp Static Bending Light Short Circuit Failed";
CM_ SG_ 3221225472 SystmStat_OverTempFail_SBLS_LH "System Status Static Bending Light/Cornering Light Left Headlamp Information : Left Headlamp Static Bending Light Over Temperature Failed";
CM_ SG_ 3221225472 SystmStat_MstrMsgFail_SBLS_LH "System Status Static Bending Light/Cornering Light Left Headlamp Information : Left Headlamp Static Bending Light Master ECU Message Failed";
CM_ SG_ 3221225472 SystmStat_FanFail_SBLS_LH "System Status Static Bending Light/Cornering Light Left Headlamp Information : Left Headlamp Static Bending Light FAN Failed";
CM_ SG_ 3221225472 SystmStat_CurntCdngFail_SBLS_LH "System Status Static Bending Light/Cornering Light Left Headlamp Information : Left Headlamp Static Bending Light Current Coding Failed";
CM_ SG_ 3221225472 SystmStat_ExtTempFail_SBLS_LH "System Status Static Bending Light/Cornering Light Left Headlamp Information : Left Headlamp Static Bending Light External Temperature Failed";
CM_ SG_ 3221225472 SystmStat_IntnlTempFail_SBLS_LH "System Status Static Bending Light/Cornering Light Left Headlamp Information : Left Headlamp Static Bending Light Internal Temperature Failed";
CM_ SG_ 3221225472 SystmStat_ActutorFail_SBLS_LH "System Status Static Bending Light/Cornering Light Left Headlamp Information : Left Headlamp Static Bending Light Actuator Failed";
CM_ SG_ 3221225472 SystmStat_UndVltgFail_SBLS_LH "System Status Static Bending Light/Cornering Light Left Headlamp Information : Left Headlamp Static Bending Light Under Voltage Failed";
CM_ SG_ 3221225472 SystmStat_FnctnStat_SBLS_LH "System Status Static Bending Light/Cornering Light Left Headlamp Information : Left Headlamp Static Bending Light Function Status";
CM_ SG_ 3221225472 SystmStat_R_L_DtctnFail_SBLS_LH "System Status Static Bending Light/Cornering Light Left Headlamp Information : Left Headlamp Static Bending Light Right/Left Side Detection Failed";
CM_ SG_ 3221225472 SystmStat_CSorMCFail_SBLS_LH "System Status Static Bending Light/Cornering Light Left Headlamp Information : Left Headlamp Static Bending Light Cksm or Message Counter Failed";
CM_ SG_ 3221225472 SystmStat_IncCompFail_SBLS_LH "System Status Static Bending Light/Cornering Light Left Headlamp Information : Left Headlamp Static Bending Light Incorrect Component Failed";
CM_ SG_ 3221225472 SystmStat_OvrVltgFail_SBLS_RH "System Status Static Bending Light/Cornering Light Right Headlamp Information : Right Headlamp Static Bending Light Over Voltage Failed";
CM_ SG_ 3221225472 SystmStat_IntrnlSysFail_SBLS_RH "System Status Static Bending Light/Cornering Light Right Headlamp Information : Right Headlamp Static Bending Light Internal System Failed";
CM_ SG_ 3221225472 SystmStat_OpnLoadFail_SBLS_RH "System Status Static Bending Light/Cornering Light Right Headlamp Information : Right Headlamp Static Bending Light Open Load Failed";
CM_ SG_ 3221225472 SystmStat_ShrtCirctFail_SBLS_RH "System Status Static Bending Light/Cornering Light Right Headlamp Information : Right Headlamp Static Bending Light Short Circuit Failed";
CM_ SG_ 3221225472 SystmStat_OverTempFail_SBLS_RH "System Status Static Bending Light/Cornering Light Right Headlamp Information : Right Headlamp Static Bending Light Over Temperature Failed";
CM_ SG_ 3221225472 SystmStat_MstrMsgFail_SBLS_RH "System Status Static Bending Light/Cornering Light Right Headlamp Information : Right Headlamp Static Bending Light Master ECU Message Failed";
CM_ SG_ 3221225472 SystmStat_FanFail_SBLS_RH "System Status Static Bending Light/Cornering Light Right Headlamp Information : Right Headlamp Static Bending Light FAN Failed";
CM_ SG_ 3221225472 SystmStat_CurntCdngFail_SBLS_RH "System Status Static Bending Light/Cornering Light Right Headlamp Information : Right Headlamp Static Bending Light Current Coding Failed";
CM_ SG_ 3221225472 SystmStat_ExtTempFail_SBLS_RH "System Status Static Bending Light/Cornering Light Right Headlamp Information : Right Headlamp Static Bending Light External Temperature Failed";
CM_ SG_ 3221225472 SystmStat_IntnlTempFail_SBLS_RH "System Status Static Bending Light/Cornering Light Right Headlamp Information : Right Headlamp Static Bending Light Internal Temperature Failed";
CM_ SG_ 3221225472 SystmStat_ActutorFail_SBLS_RH "System Status Static Bending Light/Cornering Light Right Headlamp Information : Right Headlamp Static Bending Light Actuator Failed";
CM_ SG_ 3221225472 SystmStat_UndVltgFail_SBLS_RH "System Status Static Bending Light/Cornering Light Right Headlamp Information : Right Headlamp Static Bending Light Under Voltage Failed";
CM_ SG_ 3221225472 SystmStat_FnctnStat_SBLS_RH "System Status Static Bending Light/Cornering Light Right Headlamp Information : Right Headlamp Static Bending Light Function Status";
CM_ SG_ 3221225472 SystmStat_R_L_DtctnFail_SBLS_RH "System Status Static Bending Light/Cornering Light Right Headlamp Information : Right Headlamp Static Bending Light Right/Left Side Detection Failed";
CM_ SG_ 3221225472 SystmStat_CSorMCFail_SBLS_RH "System Status Static Bending Light/Cornering Light Right Headlamp Information : Right Headlamp Static Bending Light Cksm or Message Counter Failed";
CM_ SG_ 3221225472 SystmStat_IncCompFail_SBLS_RH "System Status Static Bending Light/Cornering Light Right Headlamp Information : Right Headlamp Static Bending Light Incorrect Component Failed";
CM_ SG_ 3221225472 LftGFHBMsgCnt "System Status Glare Free High Beam Left Headlamp Information : Left Headlamp Glare Free High Beam Message Counter";
CM_ SG_ 3221225472 LftGFHBSysPwr "System Status Glare Free High Beam Left Headlamp Information : Left Headlamp Glare Free High Beam Supply Voltage Value";
CM_ SG_ 3221225472 LftGFHBLampTemp "System Status Glare Free High Beam Left Headlamp Information : Left Headlamp Glare Free High Beam External Temperature Value";
CM_ SG_ 3221225472 LftGFHBLdmTemp "System Status Glare Free High Beam Left Headlamp Information : Left Headlamp Glare Free High Beam Internal Temperature Value";
CM_ SG_ 3221225472 LftGFHBVINSts "System Status Glare Free High Beam Left Headlamp Information : Left Headlamp Glare Free High Beam VIN Status";
CM_ SG_ 3221225472 LftGFHBSysCaliSts "System Status Glare Free High Beam Left Headlamp Information : Left Headlamp Glare Free High Beam System Calibration Status";
CM_ SG_ 3221225472 LftGFHBDerateSts "System Status Glare Free High Beam Left Headlamp Information : Left Headlamp Glare Free High Beam Derating Status";
CM_ SG_ 3221225472 LftGFHBDhlInitSts "System Status Glare Free High Beam Left Headlamp Information : Left Headlamp Glare Free High Beam Reference Run Status";
CM_ SG_ 3221225472 GFHBMsgCnt "System Status Glare Free High Beam Right Headlamp Information : Right Headlamp Glare Free High Beam Message Counter";
CM_ SG_ 3221225472 RtGFHBSysPwr "System Status Glare Free High Beam Right Headlamp Information : Right Headlamp Glare Free High Beam Supply Voltage Value";
CM_ SG_ 3221225472 RtGFHBLampTemp "System Status Glare Free High Beam Right Headlamp Information : Right Headlamp Glare Free High Beam External Temperature Value";
CM_ SG_ 3221225472 RtGFHBLdmTemp "System Status Glare Free High Beam Right Headlamp Information : Right Headlamp Glare Free High Beam Internal Temperature Value";
CM_ SG_ 3221225472 RtGFHBVINSts "System Status Glare Free High Beam Right Headlamp Information : Right Headlamp Glare Free High Beam VIN Status";
CM_ SG_ 3221225472 RtGFHBSysCaliSts "System Status Glare Free High Beam Right Headlamp Information : Right Headlamp Glare Free High Beam System Calibration Status";
CM_ SG_ 3221225472 RtGFHBDerateSts "System Status Glare Free High Beam Right Headlamp Information : Right Headlamp Glare Free High Beam Derating Status";
CM_ SG_ 3221225472 RtGFHBDhlInitSts "System Status Glare Free High Beam Right Headlamp Information : Right Headlamp Glare Free High Beam Reference Run Status";
CM_ SG_ 3221225472 LftDistrMsgCnt "System Status Light Distribution Left Headlamp Information : Left Headlamp Light Distribution Message Counter";
CM_ SG_ 3221225472 LftDistrSysPwr "System Status Light Distribution Left Headlamp Information : Left Headlamp Light Distribution Supply Voltage Value";
CM_ SG_ 3221225472 LftDistrLampTemp "System Status Light Distribution Left Headlamp Information : Left Headlamp Light Distribution External Temperature Value";
CM_ SG_ 3221225472 LftDistrLdmTemp "System Status Light Distribution Left Headlamp Information : Left Headlamp Light Distribution Internal Temperature Value";
CM_ SG_ 3221225472 LftDistrVINSts "System Status Light Distribution Left Headlamp Information : Left Headlamp Light Distribution VIN Status";
CM_ SG_ 3221225472 LftDistrSysCaliSts "System Status Light Distribution Left Headlamp Information : Left Headlamp Light Distribution System Information Calibration Status";
CM_ SG_ 3221225472 LftDistrDerateSts "System Status Light Distribution Left Headlamp Information : Left Headlamp Light Distribution Derating Status";
CM_ SG_ 3221225472 LftDistrDhlInitSts "System Status Light Distribution Left Headlamp Information : Left Headlamp Light Distribution Reference Run Status";
CM_ SG_ 3221225472 DistrMsgCnt "System Status Light Distribution Right Headlamp Information : Right Headlamp Light Distribution Message Counter";
CM_ SG_ 3221225472 RtDistrSysPwr "System Status Light Distribution Right Headlamp Information : Right Headlamp Light Distribution Supply Voltage Value";
CM_ SG_ 3221225472 RtDistrLampTemp "System Status Light Distribution Right Headlamp Information : Right Headlamp Light Distribution External Temperature Value";
CM_ SG_ 3221225472 RtDistrLdmTemp "System Status Light Distribution Right Headlamp Information : Right Headlamp Light Distribution Internal Temperature Value";
CM_ SG_ 3221225472 RtDistrVINSts "System Status Light Distribution Right Headlamp Information : Right Headlamp Light Distribution VIN Status";
CM_ SG_ 3221225472 RtDistrSysCaliSts "System Status Light Distribution Right Headlamp Information : Right Headlamp Light Distribution System Information Calibration Status";
CM_ SG_ 3221225472 RtDistrDerateSts "System Status Light Distribution Right Headlamp Information : Right Headlamp Light Distribution Derating Status";
CM_ SG_ 3221225472 RtDistrDhlInitSts "System Status Light Distribution Right Headlamp Information : Right Headlamp Light Distribution Reference Run Status";
CM_ SG_ 3221225472 LftBndSysPwr "System Status Static Bending Light/Cornering Light Left Headlamp Information : Left Headlamp Static Bending Light Supply Voltage Value";
CM_ SG_ 3221225472 LftBndLampTemp "System Status Static Bending Light/Cornering Light Left Headlamp Information : Left Headlamp Static Bending Light External Temperature Value";
CM_ SG_ 3221225472 LftBndLdmTemp "System Status Static Bending Light/Cornering Light Left Headlamp Information : Left Headlamp Static Bending Light Internal Temperature Value";
CM_ SG_ 3221225472 LftBndVINSts "System Status Static Bending Light/Cornering Light Left Headlamp Information : Left Headlamp Static Bending Light VIN Status";
CM_ SG_ 3221225472 LftBndSysCaliSts "System Status Static Bending Light/Cornering Light Left Headlamp Information : Left Headlamp Static Bending Light System Calibration Status";
CM_ SG_ 3221225472 LftBndDerateSts "System Status Static Bending Light/Cornering Light Left Headlamp Information : Left Headlamp Static Bending Light Derating Status";
CM_ SG_ 3221225472 LftBndDhlInitSts "System Status Static Bending Light/Cornering Light Left Headlamp Information : Left Headlamp Static Bending Light Reference Run Status";
CM_ SG_ 3221225472 RtBndSysPwr "System Status Static Bending Light/Cornering Light Right Headlamp Information : Right Headlamp Static Bending Light Supply Voltage Value";
CM_ SG_ 3221225472 RtBndLampTemp "System Status Static Bending Light/Cornering Light Right Headlamp Information : Right Headlamp Static Bending Light External Temperature Value";
CM_ SG_ 3221225472 RtBndLdmTemp "System Status Static Bending Light/Cornering Light Right Headlamp Information : Right Headlamp Static Bending Light Internal Temperature Value";
CM_ SG_ 3221225472 RtBndVINSts "System Status Static Bending Light/Cornering Light Right Headlamp Information : Right Headlamp Static Bending Light VIN Status";
CM_ SG_ 3221225472 RtBndSysCaliSts "System Status Static Bending Light/Cornering Light Right Headlamp Information : Right Headlamp Static Bending Light System Calibration Status";
CM_ SG_ 3221225472 RtBndDerateSts "System Status Static Bending Light/Cornering Light Right Headlamp Information : Right Headlamp Static Bending Light Derating Status";
CM_ SG_ 3221225472 RtBndDhlInitSts "System Status Static Bending Light/Cornering Light Right Headlamp Information : Right Headlamp Static Bending Light Reference Run Status";
CM_ SG_ 3221225472 RtLdmInfoId0 "ECU 1 Right Headlamp Identification Information : Identification Byte 0ECU 2 Right Headlamp Identification Information : Identification Byte 0ECU 3 Right Headlamp Identification Information : Identification Byte 0";
CM_ SG_ 3221225472 RtLdmInfoId1 "ECU 1 Right Headlamp Identification Information : Identification Byte 1ECU 2 Right Headlamp Identification Information : Identification Byte 1ECU 3 Right Headlamp Identification Information : Identification Byte 1";
CM_ SG_ 3221225472 RtLdmInfoId2 "ECU 1 Right Headlamp Identification Information : Identification Byte 2ECU 2 Right Headlamp Identification Information : Identification Byte 2ECU 3 Right Headlamp Identification Information : Identification Byte 2";
CM_ SG_ 3221225472 RtLdmInfoId3 "ECU 1 Right Headlamp Identification Information : Identification Byte 3ECU 2 Right Headlamp Identification Information : Identification Byte 3ECU 3 Right Headlamp Identification Information : Identification Byte 3";
CM_ SG_ 3221225472 RtLdmInfoId4 "ECU 1 Right Headlamp Identification Information : Identification Byte 4ECU 2 Right Headlamp Identification Information : Identification Byte 4ECU 3 Right Headlamp Identification Information : Identification Byte 4";
CM_ SG_ 3221225472 RtLdmInfoId5 "ECU 1 Right Headlamp Identification Information : Identification Byte 5ECU 2 Right Headlamp Identification Information : Identification Byte 5ECU 3 Right Headlamp Identification Information : Identification Byte 5";
CM_ SG_ 3221225472 RtLdmInfoId6 "ECU 1 Right Headlamp Identification Information : Identification Byte 6ECU 2 Right Headlamp Identification Information : Identification Byte 6ECU 3 Right Headlamp Identification Information : Identification Byte 6";
CM_ SG_ 3221225472 RtLdmInfoId7 "ECU 1 Right Headlamp Identification Information : Identification Byte 7ECU 2 Right Headlamp Identification Information : Identification Byte 7ECU 3 Right Headlamp Identification Information : Identification Byte 7";
CM_ SG_ 3221225472 VIN_7 "Vehicle Identification Number Information : VIN Byte 7";
CM_ SG_ 3221225472 SystmStat_OvrVltgFail_DRLS_LH "System Status Daytime Running Light Left Headlamp Information : Left Headlamp Daytime Running Light Over Voltage Failed";
CM_ SG_ 3221225472 SystmStat_IntrnlSysFail_DRLS_LH "System Status Daytime Running Light Left Headlamp Information : Left Headlamp Daytime Running Light Internal System Failed";
CM_ SG_ 3221225472 SystmStat_OpnLoadFail_DRLS_LH "System Status Daytime Running Light Left Headlamp Information : Left Headlamp Daytime Running Light Open Load Failed";
CM_ SG_ 3221225472 SystmStat_ShrtCirctFail_DRLS_LH "System Status Daytime Running Light Left Headlamp Information : Left Headlamp Daytime Running Light Short Circuit Failed";
CM_ SG_ 3221225472 SystmStat_OverTempFail_DRLS_LH "System Status Daytime Running Light Left Headlamp Information : Left Headlamp Daytime Running Light Over Temperature Failed";
CM_ SG_ 3221225472 SystmStat_MstrMsgFail_DRLS_LH "System Status Daytime Running Light Left Headlamp Information : Left Headlamp Daytime Running Light Master ECU Message Failed";
CM_ SG_ 3221225472 SystmStat_FanFail_DRLS_LH "System Status Daytime Running Light Left Headlamp Information : Left Headlamp Daytime Running Light FAN Failed";
CM_ SG_ 3221225472 SystmStat_CurntCdngFail_DRLS_LH "System Status Daytime Running Light Left Headlamp Information : Left Headlamp Daytime Running Light Current Coding Failed";
CM_ SG_ 3221225472 SystmStat_ExtTempFail_DRLS_LH "System Status Daytime Running Light Left Headlamp Information : Left Headlamp Daytime Running Light External Temperature Failed";
CM_ SG_ 3221225472 SystmStat_IntnlTempFail_DRLS_LH "System Status Daytime Running Light Left Headlamp Information : Left Headlamp Daytime Running Light Internal Temperature Failed";
CM_ SG_ 3221225472 SystmStat_ActutorFail_DRLS_LH "System Status Daytime Running Light Left Headlamp Information : Left Headlamp Daytime Running Light Actuator Failed";
CM_ SG_ 3221225472 SystmStat_UndVltgFail_DRLS_LH "System Status Daytime Running Light Left Headlamp Information : Left Headlamp Daytime Running Light Under Voltage Failed";
CM_ SG_ 3221225472 SystmStat_FnctnStat_DRLS_LH "System Status Daytime Running Light Left Headlamp Information : Left Headlamp Daytime Running Light Function Status";
CM_ SG_ 3221225472 SystmStat_R_L_DtctnFail_DRLS_LH "System Status Daytime Running Light Left Headlamp Information : Left Headlamp Daytime Running Light Right/Left Side Detection Failed";
CM_ SG_ 3221225472 SystmStat_CSorMCFail_DRLS_LH "System Status Daytime Running Light Left Headlamp Information : Left Headlamp Daytime Running Light Cksm or Message Counter Failed";
CM_ SG_ 3221225472 SystmStat_IncCompFail_DRLS_LH "System Status Daytime Running Light Left Headlamp Information : Left Headlamp Daytime Running Light Incorrect Component Failed";
CM_ SG_ 3221225472 SystmStat_SpplyVltgVal_DRLS_LH "System Status Daytime Running Light Left Headlamp Information : Left Headlamp Daytime Running Light Supply Voltage Value";
CM_ SG_ 3221225472 SystmStat_ExtTempVal_DRLS_LH "System Status Daytime Running Light Left Headlamp Information : Left Headlamp Daytime Running Light External Temperature Value";
CM_ SG_ 3221225472 SystmStat_IntTempVal_DRLS_LH "System Status Daytime Running Light Left Headlamp Information : Left Headlamp Daytime Running Light Internal Temperature Value";
CM_ SG_ 3221225472 SystmStat_VINStat_DRLS_LH "System Status Daytime Running Light Left Headlamp Information : Left Headlamp Daytime Running Light VIN Status";
CM_ SG_ 3221225472 SystmStat_SysCalibStat_DRLS_LH "System Status Daytime Running Light Left Headlamp Information : Left Headlamp Daytime Running Light System Information Calibration Status";
CM_ SG_ 3221225472 SystmStat_DertngStat_DRLS_LH "System Status Daytime Running Light Left Headlamp Information : Left Headlamp Daytime Running Light Derating Status";
CM_ SG_ 3221225472 SystmStat_RefrncRunStat_DRLS_LH "System Status Daytime Running Light Left Headlamp Information : Left Headlamp Daytime Running Light Reference Run Status";
CM_ SG_ 3221225472 SystmStat_OvrVltgFail_DRLS_RH "System Status Daytime Running Light Right Headlamp Information : Right Headlamp Daytime Running Light Over Voltage Failed";
CM_ SG_ 3221225472 SystmStat_IntrnlSysFail_DRLS_RH "System Status Daytime Running Light Right Headlamp Information : Right Headlamp Daytime Running Light Internal System Failed";
CM_ SG_ 3221225472 SystmStat_OpnLoadFail_DRLS_RH "System Status Daytime Running Light Right Headlamp Information : Right Headlamp Daytime Running Light Open Load Failed";
CM_ SG_ 3221225472 SystmStat_ShrtCirctFail_DRLS_RH "System Status Daytime Running Light Right Headlamp Information : Right Headlamp Daytime Running Light Short Circuit Failed";
CM_ SG_ 3221225472 SystmStat_OverTempFail_DRLS_RH "System Status Daytime Running Light Right Headlamp Information : Right Headlamp Daytime Running Light Over Temperature Failed";
CM_ SG_ 3221225472 SystmStat_MstrMsgFail_DRLS_RH "System Status Daytime Running Light Right Headlamp Information : Right Headlamp Daytime Running Light Master ECU Message Failed";
CM_ SG_ 3221225472 SystmStat_FanFail_DRLS_RH "System Status Daytime Running Light Right Headlamp Information : Right Headlamp Daytime Running Light FAN Failed";
CM_ SG_ 3221225472 SystmStat_CurntCdngFail_DRLS_RH "System Status Daytime Running Light Right Headlamp Information : Right Headlamp Daytime Running Light Current Coding Failed";
CM_ SG_ 3221225472 SystmStat_ExtTempFail_DRLS_RH "System Status Daytime Running Light Right Headlamp Information : Right Headlamp Daytime Running Light External Temperature Failed";
CM_ SG_ 3221225472 SystmStat_IntnlTempFail_DRLS_RH "System Status Daytime Running Light Right Headlamp Information : Right Headlamp Daytime Running Light Internal Temperature Failed";
CM_ SG_ 3221225472 SystmStat_ActutorFail_DRLS_RH "System Status Daytime Running Light Right Headlamp Information : Right Headlamp Daytime Running Light Actuator Failed";
CM_ SG_ 3221225472 SystmStat_UndVltgFail_DRLS_RH "System Status Daytime Running Light Right Headlamp Information : Right Headlamp Daytime Running Light Under Voltage Failed";
CM_ SG_ 3221225472 SystmStat_FnctnStat_DRLS_RH "System Status Daytime Running Light Right Headlamp Information : Right Headlamp Daytime Running Light Function Status";
CM_ SG_ 3221225472 SystmStat_R_L_DtctnFail_DRLS_RH "System Status Daytime Running Light Right Headlamp Information : Right Headlamp Daytime Running Light Right/Left Side Detection Failed";
CM_ SG_ 3221225472 SystmStat_CSorMCFail_DRLS_RH "System Status Daytime Running Light Right Headlamp Information : Right Headlamp Daytime Running Light Cksm or Message Counter Failed";
CM_ SG_ 3221225472 SystmStat_IncCompFail_DRLS_RH "System Status Daytime Running Light Right Headlamp Information : Right Headlamp Daytime Running Light Incorrect Component Failed";
CM_ SG_ 3221225472 SystmStat_SpplyVltgVal_DRLS_RH "System Status Daytime Running Light Right Headlamp Information : Right Headlamp Daytime Running Light Supply Voltage Value";
CM_ SG_ 3221225472 SystmStat_ExtTempVal_DRLS_RH "System Status Daytime Running Light Right Headlamp Information : Right Headlamp Daytime Running Light External Temperature Value";
CM_ SG_ 3221225472 SystmStat_IntTempVal_DRLS_RH "System Status Daytime Running Light Right Headlamp Information : Right Headlamp Daytime Running Light Internal Temperature Value";
CM_ SG_ 3221225472 SystmStat_VINStat_DRLS_RH "System Status Daytime Running Light Right Headlamp Information : Right Headlamp Daytime Running Light VIN Status";
CM_ SG_ 3221225472 SystmStat_SysCalibStat_DRLS_RH "System Status Daytime Running Light Right Headlamp Information : Right Headlamp Daytime Running Light System Information Calibration Status";
CM_ SG_ 3221225472 SystmStat_DertngStat_DRLS_RH "System Status Daytime Running Light Right Headlamp Information : Right Headlamp Daytime Running Light Derating Status";
CM_ SG_ 3221225472 SystmStat_RefrncRunStat_DRLS_RH "System Status Daytime Running Light Right Headlamp Information : Right Headlamp Daytime Running Light Reference Run Status";
CM_ SG_ 3221225472 SystmStat_Chcksm_HLS_LH "System Status Levelling System Left Headlamp Information : Left Headlamp Levelling Cksm";
CM_ SG_ 3221225472 SystmStat_OvrVltgFail_HLS_LH "System Status Levelling System Left Headlamp Information : Left Headlamp Levelling Over Voltage Failed";
CM_ SG_ 3221225472 SystmStat_IntrnlSysFail_HLS_LH "System Status Levelling System Left Headlamp Information : Left Headlamp Levelling Internal System Failed";
CM_ SG_ 3221225472 SystmStat_OpnLoadFail_HLS_LH "System Status Levelling System Left Headlamp Information : Left Headlamp Levelling Open Load Failed";
CM_ SG_ 3221225472 SystmStat_ShrtCirctFail_HLS_LH "System Status Levelling System Left Headlamp Information : Left Headlamp Levelling Short Circuit Failed";
CM_ SG_ 3221225472 SystmStat_MssgCntr_HLS_LH "System Status Levelling System Left Headlamp Information : Left Headlamp Levelling Message Counter";
CM_ SG_ 3221225472 SystmStat_OverTempFail_HLS_LH "System Status Levelling System Left Headlamp Information : Left Headlamp Levelling Over Temperature Failed";
CM_ SG_ 3221225472 SystmStat_MstrMsgFail_HLS_LH "System Status Levelling System Left Headlamp Information : Left Headlamp Levelling Master ECU Message Failed";
CM_ SG_ 3221225472 SystmStat_FanFail_HLS_LH "System Status Levelling System Left Headlamp Information : Left Headlamp Levelling FAN Failed";
CM_ SG_ 3221225472 SystmStat_CurntCdngFail_HLS_LH "System Status Levelling System Left Headlamp Information : Left Headlamp Levelling Current Coding Failed";
CM_ SG_ 3221225472 SystmStat_ExtTempFail_HLS_LH "System Status Levelling System Left Headlamp Information : Left Headlamp Levelling External Temperature Failed";
CM_ SG_ 3221225472 SystmStat_IntnlTempFail_HLS_LH "System Status Levelling System Left Headlamp Information : Left Headlamp Levelling Internal Temperature Failed";
CM_ SG_ 3221225472 SystmStat_ActutorFail_HLS_LH "System Status Levelling System Left Headlamp Information : Left Headlamp Levelling Actuator Failed";
CM_ SG_ 3221225472 SystmStat_UndVltgFail_HLS_LH "System Status Levelling System Left Headlamp Information : Left Headlamp Levelling Under Voltage Failed";
CM_ SG_ 3221225472 SystmStat_FnctnStat_HLS_LH "System Status Levelling System Left Headlamp Information : Left Headlamp Levelling Function Status";
CM_ SG_ 3221225472 SystmStat_R_L_DtctnFail_HLS_LH "System Status Levelling System Left Headlamp Information : Left Headlamp Levelling Right/Left Side Detection Failed";
CM_ SG_ 3221225472 SystmStat_CSorMCFail_HLS_LH "System Status Levelling System Left Headlamp Information : Left Headlamp Levelling Cksm or Message Counter Failed";
CM_ SG_ 3221225472 SystmStat_IncCompFail_HLS_LH "System Status Levelling System Left Headlamp Information : Left Headlamp Levelling Incorrect Component Failed";
CM_ SG_ 3221225472 SystmStat_SpplyVltgVal_HLS_LH "System Status Levelling System Left Headlamp Information : Left Headlamp Levelling Supply Voltage Value";
CM_ SG_ 3221225472 SystmStat_ExtTempVal_HLS_LH "System Status Levelling System Left Headlamp Information : Left Headlamp Levelling External Temperature Value";
CM_ SG_ 3221225472 SystmStat_IntTempVal_HLS_LH "System Status Levelling System Left Headlamp Information : Left Headlamp Levelling Internal Temperature Value";
CM_ SG_ 3221225472 SystmStat_VINStat_HLS_LH "System Status Levelling System Left Headlamp Information : Left Headlamp Levelling VIN Status";
CM_ SG_ 3221225472 SystmStat_SysCalibStat_HLS_LH "System Status Levelling System Left Headlamp Information : Left Headlamp Levelling System Information Calibration Status";
CM_ SG_ 3221225472 SystmStat_DertngStat_HLS_LH "System Status Levelling System Left Headlamp Information : Left Headlamp Levelling Derating Status";
CM_ SG_ 3221225472 SystmStat_RefrncRunStat_HLS_LH "System Status Levelling System Left Headlamp Information : Left Headlamp Levelling Reference Run Status";
CM_ SG_ 3221225472 SystmStat_Chcksm_HLS_RH "System Status Levelling System Right Headlamp Information : Right Headlamp Levelling Cksm";
CM_ SG_ 3221225472 SystmStat_OvrVltgFail_HLS_RH "System Status Levelling System Right Headlamp Information : Right Headlamp Levelling Over Voltage Failed";
CM_ SG_ 3221225472 SystmStat_IntrnlSysFail_HLS_RH "System Status Levelling System Right Headlamp Information : Right Headlamp Levelling Internal System Failed";
CM_ SG_ 3221225472 SystmStat_OpnLoadFail_HLS_RH "System Status Levelling System Right Headlamp Information : Right Headlamp Levelling Open Load Failed";
CM_ SG_ 3221225472 SystmStat_ShrtCirctFail_HLS_RH "System Status Levelling System Right Headlamp Information : Right Headlamp Levelling Short Circuit Failed";
CM_ SG_ 3221225472 SystmStat_MssgCntr_HLS_RH "System Status Levelling System Right Headlamp Information : Right Headlamp Levelling Message Counter";
CM_ SG_ 3221225472 SystmStat_OverTempFail_HLS_RH "System Status Levelling System Right Headlamp Information : Right Headlamp Levelling Over Temperature Failed";
CM_ SG_ 3221225472 SystmStat_MstrMsgFail_HLS_RH "System Status Levelling System Right Headlamp Information : Right Headlamp Levelling Master ECU Message Failed";
CM_ SG_ 3221225472 SystmStat_FanFail_HLS_RH "System Status Levelling System Right Headlamp Information : Right Headlamp Levelling FAN Failed";
CM_ SG_ 3221225472 SystmStat_CurntCdngFail_HLS_RH "System Status Levelling System Right Headlamp Information : Right Headlamp Levelling Current Coding Failed";
CM_ SG_ 3221225472 SystmStat_ExtTempFail_HLS_RH "System Status Levelling System Right Headlamp Information : Right Headlamp Levelling External Temperature Failed";
CM_ SG_ 3221225472 SystmStat_IntnlTempFail_HLS_RH "System Status Levelling System Right Headlamp Information : Right Headlamp Levelling Internal Temperature Failed";
CM_ SG_ 3221225472 SystmStat_ActutorFail_HLS_RH "System Status Levelling System Right Headlamp Information : Right Headlamp Levelling Actuator Failed";
CM_ SG_ 3221225472 SystmStat_UndVltgFail_HLS_RH "System Status Levelling System Right Headlamp Information : Right Headlamp Levelling Under Voltage Failed";
CM_ SG_ 3221225472 SystmStat_FnctnStat_HLS_RH "System Status Levelling System Right Headlamp Information : Right Headlamp Levelling Function Status";
CM_ SG_ 3221225472 SystmStat_R_L_DtctnFail_HLS_RH "System Status Levelling System Right Headlamp Information : Right Headlamp Levelling Right/Left Side Detection Failed";
CM_ SG_ 3221225472 SystmStat_CSorMCFail_HLS_RH "System Status Levelling System Right Headlamp Information : Right Headlamp Levelling Cksm or Message Counter Failed";
CM_ SG_ 3221225472 SystmStat_IncCompFail_HLS_RH "System Status Levelling System Right Headlamp Information : Right Headlamp Levelling Incorrect Component Failed";
CM_ SG_ 3221225472 SystmStat_SpplyVltgVal_HLS_RH "System Status Levelling System Right Headlamp Information : Right Headlamp Levelling Supply Voltage Value";
CM_ SG_ 3221225472 SystmStat_ExtTempVal_HLS_RH "System Status Levelling System Right Headlamp Information : Right Headlamp Levelling External Temperature Value";
CM_ SG_ 3221225472 SystmStat_IntTempVal_HLS_RH "System Status Levelling System Right Headlamp Information : Right Headlamp Levelling Internal Temperature Value";
CM_ SG_ 3221225472 SystmStat_VINStat_HLS_RH "System Status Levelling System Right Headlamp Information : Right Headlamp Levelling VIN Status";
CM_ SG_ 3221225472 SystmStat_SysCalibStat_HLS_RH "System Status Levelling System Right Headlamp Information : Right Headlamp Levelling System Information Calibration Status";
CM_ SG_ 3221225472 SystmStat_DertngStat_HLS_RH "System Status Levelling System Right Headlamp Information : Right Headlamp Levelling Derating Status";
CM_ SG_ 3221225472 SystmStat_RefrncRunStat_HLS_RH "System Status Levelling System Right Headlamp Information : Right Headlamp Levelling Reference Run Status";
CM_ SG_ 3221225472 SystmStat_Chcksm_DBLS_LH "System Status Dynamic Bending Light Left Headlamp Information : Left Headlamp Dynamic Bending Light Cksm";
CM_ SG_ 3221225472 SystmStat_OvrVltgFail_DBLS_LH "System Status Dynamic Bending Light Left Headlamp Information : Left Headlamp Dynamic Bending Light Over Voltage Failed";
CM_ SG_ 3221225472 SystmStat_IntrnlSysFail_DBLS_LH "System Status Dynamic Bending Light Left Headlamp Information : Left Headlamp Dynamic Bending Light Internal System Failed";
CM_ SG_ 3221225472 SystmStat_OpnLoadFail_DBLS_LH "System Status Dynamic Bending Light Left Headlamp Information : Left Headlamp Dynamic Bending Light Open Load Failed";
CM_ SG_ 3221225472 SystmStat_ShrtCirctFail_DBLS_LH "System Status Dynamic Bending Light Left Headlamp Information : Left Headlamp Dynamic Bending Light Short Circuit Failed";
CM_ SG_ 3221225472 SystmStat_MssgCntr_DBLS_LH "System Status Dynamic Bending Light Left Headlamp Information : Left Headlamp Dynamic Bending Light Message Counter";
CM_ SG_ 3221225472 SystmStat_OverTempFail_DBLS_LH "System Status Dynamic Bending Light Left Headlamp Information : Left Headlamp Dynamic Bending Light Over Temperature Failed";
CM_ SG_ 3221225472 SystmStat_MstrMsgFail_DBLS_LH "System Status Dynamic Bending Light Left Headlamp Information : Left Headlamp Dynamic Bending Light Master ECU Message Failed";
CM_ SG_ 3221225472 SystmStat_FanFail_DBLS_LH "System Status Dynamic Bending Light Left Headlamp Information : Left Headlamp Dynamic Bending Light FAN Failed";
CM_ SG_ 3221225472 SystmStat_CurntCdngFail_DBLS_LH "System Status Dynamic Bending Light Left Headlamp Information : Left Headlamp Dynamic Bending Light Current Coding Failed";
CM_ SG_ 3221225472 SystmStat_ExtTempFail_DBLS_LH "System Status Dynamic Bending Light Left Headlamp Information : Left Headlamp Dynamic Bending Light External Temperature Failed";
CM_ SG_ 3221225472 SystmStat_IntnlTempFail_DBLS_LH "System Status Dynamic Bending Light Left Headlamp Information : Left Headlamp Dynamic Bending Light Internal Temperature Failed";
CM_ SG_ 3221225472 SystmStat_ActutorFail_DBLS_LH "System Status Dynamic Bending Light Left Headlamp Information : Left Headlamp Dynamic Bending Light Actuator Failed";
CM_ SG_ 3221225472 SystmStat_UndVltgFail_DBLS_LH "System Status Dynamic Bending Light Left Headlamp Information : Left Headlamp Dynamic Bending Light Under Voltage Failed";
CM_ SG_ 3221225472 SystmStat_FnctnStat_DBLS_LH "System Status Dynamic Bending Light Left Headlamp Information : Left Headlamp Dynamic Bending Light Function Status";
CM_ SG_ 3221225472 SystmStat_R_L_DtctnFail_DBLS_LH "System Status Dynamic Bending Light Left Headlamp Information : Left Headlamp Dynamic Bending Light Right/Left Side Detection Failed";
CM_ SG_ 3221225472 SystmStat_CSorMCFail_DBLS_LH "System Status Dynamic Bending Light Left Headlamp Information : Left Headlamp Dynamic Bending Light Cksm or Message Counter Failed";
CM_ SG_ 3221225472 SystmStat_IncCompFail_DBLS_LH "System Status Dynamic Bending Light Left Headlamp Information : Left Headlamp Dynamic Bending Light Incorrect Component Failed";
CM_ SG_ 3221225472 SystmStat_SpplyVltgVal_DBLS_LH "System Status Dynamic Bending Light Left Headlamp Information : Left Headlamp Dynamic Bending Light Supply Voltage Value";
CM_ SG_ 3221225472 SystmStat_ExtTempVal_DBLS_LH "System Status Dynamic Bending Light Left Headlamp Information : Left Headlamp Dynamic Bending Light External Temperature Value";
CM_ SG_ 3221225472 SystmStat_IntTempVal_DBLS_LH "System Status Dynamic Bending Light Left Headlamp Information : Left Headlamp Dynamic Bending Light Internal Temperature Value";
CM_ SG_ 3221225472 SystmStat_VINStat_DBLS_LH "System Status Dynamic Bending Light Left Headlamp Information : Left Headlamp Dynamic Bending Light VIN Status";
CM_ SG_ 3221225472 SystmStat_SysCalibStat_DBLS_LH "System Status Dynamic Bending Light Left Headlamp Information : Left Headlamp Dynamic Bending Light System Information Calibration Status";
CM_ SG_ 3221225472 SystmStat_DertngStat_DBLS_LH "System Status Dynamic Bending Light Left Headlamp Information : Left Headlamp Dynamic Bending Light Derating Status";
CM_ SG_ 3221225472 SystmStat_RefrncRunStat_DBLS_LH "System Status Dynamic Bending Light Left Headlamp Information : Left Headlamp Dynamic Bending Light Reference Run Status";
CM_ SG_ 3221225472 SystmStat_Chcksm_DBLS_RH "System Status Dynamic Bending Light Right Headlamp Information : Right Headlamp Dynamic Bending Light Cksm";
CM_ SG_ 3221225472 SystmStat_OvrVltgFail_DBLS_RH "System Status Dynamic Bending Light Right Headlamp Information : Right Headlamp Dynamic Bending Light Over Voltage Failed";
CM_ SG_ 3221225472 SystmStat_IntrnlSysFail_DBLS_RH "System Status Dynamic Bending Light Right Headlamp Information : Right Headlamp Dynamic Bending Light Internal System Failed";
CM_ SG_ 3221225472 SystmStat_OpnLoadFail_DBLS_RH "System Status Dynamic Bending Light Right Headlamp Information : Right Headlamp Dynamic Bending Light Open Load Failed";
CM_ SG_ 3221225472 SystmStat_ShrtCirctFail_DBLS_RH "System Status Dynamic Bending Light Right Headlamp Information : Right Headlamp Dynamic Bending Light Short Circuit Failed";
CM_ SG_ 3221225472 SystmStat_MssgCntr_DBLS_RH "System Status Dynamic Bending Light Right Headlamp Information : Right Headlamp Dynamic Bending Light Message Counter";
CM_ SG_ 3221225472 SystmStat_OverTempFail_DBLS_RH "System Status Dynamic Bending Light Right Headlamp Information : Right Headlamp Dynamic Bending Light Over Temperature Failed";
CM_ SG_ 3221225472 SystmStat_MstrMsgFail_DBLS_RH "System Status Dynamic Bending Light Right Headlamp Information : Right Headlamp Dynamic Bending Light Master ECU Message Failed";
CM_ SG_ 3221225472 SystmStat_FanFail_DBLS_RH "System Status Dynamic Bending Light Right Headlamp Information : Right Headlamp Dynamic Bending Light FAN Failed";
CM_ SG_ 3221225472 SystmStat_CurntCdngFail_DBLS_RH "System Status Dynamic Bending Light Right Headlamp Information : Right Headlamp Dynamic Bending Light Current Coding Failed";
CM_ SG_ 3221225472 SystmStat_ExtTempFail_DBLS_RH "System Status Dynamic Bending Light Right Headlamp Information : Right Headlamp Dynamic Bending Light External Temperature Failed";
CM_ SG_ 3221225472 SystmStat_IntnlTempFail_DBLS_RH "System Status Dynamic Bending Light Right Headlamp Information : Right Headlamp Dynamic Bending Light Internal Temperature Failed";
CM_ SG_ 3221225472 SystmStat_ActutorFail_DBLS_RH "System Status Dynamic Bending Light Right Headlamp Information : Right Headlamp Dynamic Bending Light Actuator Failed";
CM_ SG_ 3221225472 SystmStat_UndVltgFail_DBLS_RH "System Status Dynamic Bending Light Right Headlamp Information : Right Headlamp Dynamic Bending Light Under Voltage Failed";
CM_ SG_ 3221225472 SystmStat_FnctnStat_DBLS_RH "System Status Dynamic Bending Light Right Headlamp Information : Right Headlamp Dynamic Bending Light Function Status";
CM_ SG_ 3221225472 SystmStat_R_L_DtctnFail_DBLS_RH "System Status Dynamic Bending Light Right Headlamp Information : Right Headlamp Dynamic Bending Light Right/Left Side Detection Failed";
CM_ SG_ 3221225472 SystmStat_CSorMCFail_DBLS_RH "System Status Dynamic Bending Light Right Headlamp Information : Right Headlamp Dynamic Bending Light Cksm or Message Counter Failed";
CM_ SG_ 3221225472 SystmStat_IncCompFail_DBLS_RH "System Status Dynamic Bending Light Right Headlamp Information : Right Headlamp Dynamic Bending Light Incorrect Component Failed";
CM_ SG_ 3221225472 SystmStat_SpplyVltgVal_DBLS_RH "System Status Dynamic Bending Light Right Headlamp Information : Right Headlamp Dynamic Bending Light Supply Voltage Value";
CM_ SG_ 3221225472 SystmStat_ExtTempVal_DBLS_RH "System Status Dynamic Bending Light Right Headlamp Information : Right Headlamp Dynamic Bending Light External Temperature Value";
CM_ SG_ 3221225472 SystmStat_IntTempVal_DBLS_RH "System Status Dynamic Bending Light Right Headlamp Information : Right Headlamp Dynamic Bending Light Internal Temperature Value";
CM_ SG_ 3221225472 SystmStat_VINStat_DBLS_RH "System Status Dynamic Bending Light Right Headlamp Information : Right Headlamp Dynamic Bending Light VIN Status";
CM_ SG_ 3221225472 SystmStat_SysCalibStat_DBLS_RH "System Status Dynamic Bending Light Right Headlamp Information : Right Headlamp Dynamic Bending Light System Information Calibration Status";
CM_ SG_ 3221225472 SystmStat_DertngStat_DBLS_RH "System Status Dynamic Bending Light Right Headlamp Information : Right Headlamp Dynamic Bending Light Derating Status";
CM_ SG_ 3221225472 SystmStat_RefrncRunStat_DBLS_RH "System Status Dynamic Bending Light Right Headlamp Information : Right Headlamp Dynamic Bending Light Reference Run Status";
CM_ SG_ 3221225472 SystmStat_Chcksm_MLS_LH "System Status Marker Light Left Headlamp Information : Left Headlamp Marker Light Cksm";
CM_ SG_ 3221225472 SystmStat_OvrVltgFail_MLS_LH "System Status Marker Light Left Headlamp Information : Left Headlamp Marker Light Over Voltage Failed";
CM_ SG_ 3221225472 SystmStat_IntrnlSysFail_MLS_LH "System Status Marker Light Left Headlamp Information : Left Headlamp Marker Light Internal System Failed";
CM_ SG_ 3221225472 SystmStat_OpnLoadFail_MLS_LH "System Status Marker Light Left Headlamp Information : Left Headlamp Marker Light Open Load Failed";
CM_ SG_ 3221225472 SystmStat_ShrtCirctFail_MLS_LH "System Status Marker Light Left Headlamp Information : Left Headlamp Marker Light Short Circuit Failed";
CM_ SG_ 3221225472 SystmStat_MssgCntr_MLS_LH "System Status Marker Light Left Headlamp Information : Left Headlamp Marker Light Message Counter";
CM_ SG_ 3221225472 SystmStat_OverTempFail_MLS_LH "System Status Marker Light Left Headlamp Information : Left Headlamp Marker Light Over Temperature Failed";
CM_ SG_ 3221225472 SystmStat_MstrMsgFail_MLS_LH "System Status Marker Light Left Headlamp Information : Left Headlamp Marker Light Master ECU Message Failed";
CM_ SG_ 3221225472 SystmStat_FanFail_MLS_LH "System Status Marker Light Left Headlamp Information : Left Headlamp Marker Light FAN Failed";
CM_ SG_ 3221225472 SystmStat_CurntCdngFail_MLS_LH "System Status Marker Light Left Headlamp Information : Left Headlamp Marker Light Current Coding Failed";
CM_ SG_ 3221225472 SystmStat_ExtTempFail_MLS_LH "System Status Marker Light Left Headlamp Information : Left Headlamp Marker Light External Temperature Failed";
CM_ SG_ 3221225472 SystmStat_IntnlTempFail_MLS_LH "System Status Marker Light Left Headlamp Information : Left Headlamp Marker Light Internal Temperature Failed";
CM_ SG_ 3221225472 SystmStat_ActutorFail_MLS_LH "System Status Marker Light Left Headlamp Information : Left Headlamp Marker Light Actuator Failed";
CM_ SG_ 3221225472 SystmStat_UndVltgFail_MLS_LH "System Status Marker Light Left Headlamp Information : Left Headlamp Marker Light Under Voltage Failed";
CM_ SG_ 3221225472 SystmStat_FnctnStat_MLS_LH "System Status Marker Light Left Headlamp Information : Left Headlamp Marker Light Function Status";
CM_ SG_ 3221225472 SystmStat_R_L_DtctnFail_MLS_LH "System Status Marker Light Left Headlamp Information : Left Headlamp Marker Light Right/Left Side Detection Failed";
CM_ SG_ 3221225472 SystmStat_CSorMCFail_MLS_LH "System Status Marker Light Left Headlamp Information : Left Headlamp Marker Light Cksm or Message Counter Failed";
CM_ SG_ 3221225472 SystmStat_IncCompFail_MLS_LH "System Status Marker Light Left Headlamp Information : Left Headlamp Marker Light Incorrect Component Failed";
CM_ SG_ 3221225472 SystmStat_SpplyVltgVal_MLS_LH "System Status Marker Light Left Headlamp Information : Left Headlamp Marker Light Supply Voltage Value";
CM_ SG_ 3221225472 SystmStat_ExtTempVal_MLS_LH "System Status Marker Light Left Headlamp Information : Left Headlamp Marker Light External Temperature Value";
CM_ SG_ 3221225472 SystmStat_IntTempVal_MLS_LH "System Status Marker Light Left Headlamp Information : Left Headlamp Marker Light Internal Temperature Value";
CM_ SG_ 3221225472 SystmStat_VINStat_MLS_LH "System Status Marker Light Left Headlamp Information : Left Headlamp Marker Light VIN Status";
CM_ SG_ 3221225472 SystmStat_SysCalibStat_MLS_LH "System Status Marker Light Left Headlamp Information : Left Headlamp Marker Light System Calibration Status";
CM_ SG_ 3221225472 SystmStat_DertngStat_MLS_LH "System Status Marker Light Left Headlamp Information : Left Headlamp Marker Light Derating Status";
CM_ SG_ 3221225472 SystmStat_RefrncRunStat_MLS_LH "System Status Marker Light Left Headlamp Information : Left Headlamp Marker Light Reference Run Status";
CM_ SG_ 3221225472 SystmStat_Chcksm_MLS_RH "System Status Marker Light Right Headlamp Information : Right Headlamp Marker Light Cksm";
CM_ SG_ 3221225472 SystmStat_OvrVltgFail_MLS_RH "System Status Marker Light Right Headlamp Information : Right Headlamp Marker Light Over Voltage Failed";
CM_ SG_ 3221225472 SystmStat_IntrnlSysFail_MLS_RH "System Status Marker Light Right Headlamp Information : Right Headlamp Marker Light Internal System Failed";
CM_ SG_ 3221225472 SystmStat_OpnLoadFail_MLS_RH "System Status Marker Light Right Headlamp Information : Right Headlamp Marker Light Open Load Failed";
CM_ SG_ 3221225472 SystmStat_ShrtCirctFail_MLS_RH "System Status Marker Light Right Headlamp Information : Right Headlamp Marker Light Short Circuit Failed";
CM_ SG_ 3221225472 SystmStat_MssgCntr_MLS_RH "System Status Marker Light Right Headlamp Information : Right Headlamp Marker Light Message Counter";
CM_ SG_ 3221225472 SystmStat_OverTempFail_MLS_RH "System Status Marker Light Right Headlamp Information : Right Headlamp Marker Light Over Temperature Failed";
CM_ SG_ 3221225472 SystmStat_MstrMsgFail_MLS_RH "System Status Marker Light Right Headlamp Information : Right Headlamp Marker Light Master ECU Message Failed";
CM_ SG_ 3221225472 SystmStat_FanFail_MLS_RH "System Status Marker Light Right Headlamp Information : Right Headlamp Marker Light FAN Failed";
CM_ SG_ 3221225472 SystmStat_CurntCdngFail_MLS_RH "System Status Marker Light Right Headlamp Information : Right Headlamp Marker Light Current Coding Failed";
CM_ SG_ 3221225472 SystmStat_ExtTempFail_MLS_RH "System Status Marker Light Right Headlamp Information : Right Headlamp Marker Light External Temperature Failed";
CM_ SG_ 3221225472 SystmStat_IntnlTempFail_MLS_RH "System Status Marker Light Right Headlamp Information : Right Headlamp Marker Light Internal Temperature Failed";
CM_ SG_ 3221225472 SystmStat_ActutorFail_MLS_RH "System Status Marker Light Right Headlamp Information : Right Headlamp Marker Light Actuator Failed";
CM_ SG_ 3221225472 SystmStat_UndVltgFail_MLS_RH "System Status Marker Light Right Headlamp Information : Right Headlamp Marker Light Under Voltage Failed";
CM_ SG_ 3221225472 SystmStat_FnctnStat_MLS_RH "System Status Marker Light Right Headlamp Information : Right Headlamp Marker Light Function Status";
CM_ SG_ 3221225472 SystmStat_R_L_DtctnFail_MLS_RH "System Status Marker Light Right Headlamp Information : Right Headlamp Marker Light Right/Left Side Detection Failed";
CM_ SG_ 3221225472 SystmStat_CSorMCFail_MLS_RH "System Status Marker Light Right Headlamp Information : Right Headlamp Marker Light Cksm or Message Counter Failed";
CM_ SG_ 3221225472 SystmStat_IncCompFail_MLS_RH "System Status Marker Light Right Headlamp Information : Right Headlamp Marker Light Incorrect Component Failed";
CM_ SG_ 3221225472 SystmStat_SpplyVltgVal_MLS_RH "System Status Marker Light Right Headlamp Information : Right Headlamp Marker Light Supply Voltage Value";
CM_ SG_ 3221225472 SystmStat_ExtTempVal_MLS_RH "System Status Marker Light Right Headlamp Information : Right Headlamp Marker Light External Temperature Value";
CM_ SG_ 3221225472 SystmStat_IntTempVal_MLS_RH "System Status Marker Light Right Headlamp Information : Right Headlamp Marker Light Internal Temperature Value";
CM_ SG_ 3221225472 SystmStat_VINStat_MLS_RH "System Status Marker Light Right Headlamp Information : Right Headlamp Marker Light VIN Status";
CM_ SG_ 3221225472 SystmStat_SysCalibStat_MLS_RH "System Status Marker Light Right Headlamp Information : Right Headlamp Marker Light System Calibration Status";
CM_ SG_ 3221225472 SystmStat_DertngStat_MLS_RH "System Status Marker Light Right Headlamp Information : Right Headlamp Marker Light Derating Status";
CM_ SG_ 3221225472 SystmStat_RefrncRunStat_MLS_RH "System Status Marker Light Right Headlamp Information : Right Headlamp Marker Light Reference Run Status";
CM_ SG_ 3221225472 SystmStat_OvrVltgFail_PLS_LH "System Status Position Light Left Headlamp Information : Left Headlamp Position Light Over Voltage Failed";
CM_ SG_ 3221225472 SystmStat_IntrnlSysFail_PLS_LH "System Status Position Light Left Headlamp Information : Left Headlamp Position Light Internal System Failed";
CM_ SG_ 3221225472 SystmStat_OpnLoadFail_PLS_LH "System Status Position Light Left Headlamp Information : Left Headlamp Position Light Open Load Failed";
CM_ SG_ 3221225472 SystmStat_ShrtCirctFail_PLS_LH "System Status Position Light Left Headlamp Information : Left Headlamp Position Light Short Circuit Failed";
CM_ SG_ 3221225472 SystmStat_OverTempFail_PLS_LH "System Status Position Light Left Headlamp Information : Left Headlamp Position Light Over Temperature Failed";
CM_ SG_ 3221225472 SystmStat_MstrMsgFail_PLS_LH "System Status Position Light Left Headlamp Information : Left Headlamp Position Light Master ECU Message Failed";
CM_ SG_ 3221225472 SystmStat_FanFail_PLS_LH "System Status Position Light Left Headlamp Information : Left Headlamp Position Light FAN Failed";
CM_ SG_ 3221225472 SystmStat_CurntCdngFail_PLS_LH "System Status Position Light Left Headlamp Information : Left Headlamp Position Light Current Coding Failed";
CM_ SG_ 3221225472 SystmStat_ExtTempFail_PLS_LH "System Status Position Light Left Headlamp Information : Left Headlamp Position Light External Temperature Failed";
CM_ SG_ 3221225472 SystmStat_IntnlTempFail_PLS_LH "System Status Position Light Left Headlamp Information : Left Headlamp Position Light Internal Temperature Failed";
CM_ SG_ 3221225472 SystmStat_ActutorFail_PLS_LH "System Status Position Light Left Headlamp Information : Left Headlamp Position Light Actuator Failed";
CM_ SG_ 3221225472 SystmStat_UndVltgFail_PLS_LH "System Status Position Light Left Headlamp Information : Left Headlamp Position Light Under Voltage Failed";
CM_ SG_ 3221225472 SystmStat_FnctnStat_PLS_LH "System Status Position Light Left Headlamp Information : Left Headlamp Position Light Function Status";
CM_ SG_ 3221225472 SystmStat_R_L_DtctnFail_PLS_LH "System Status Position Light Left Headlamp Information : Left Headlamp Position Light Right/Left Side Detection Failed";
CM_ SG_ 3221225472 SystmStat_CSorMCFail_PLS_LH "System Status Position Light Left Headlamp Information : Left Headlamp Position Light Cksm or Message Counter Failed";
CM_ SG_ 3221225472 SystmStat_IncCompFail_PLS_LH "System Status Position Light Left Headlamp Information : Left Headlamp Position Light Incorrect Component Failed";
CM_ SG_ 3221225472 SystmStat_SpplyVltgVal_PLS_LH "System Status Position Light Left Headlamp Information : Left Headlamp Position Light Supply Voltage Value";
CM_ SG_ 3221225472 SystmStat_ExtTempVal_PLS_LH "System Status Position Light Left Headlamp Information : Left Headlamp Position Light External Temperature Value";
CM_ SG_ 3221225472 SystmStat_IntTempVal_PLS_LH "System Status Position Light Left Headlamp Information : Left Headlamp Position Light Internal Temperature Value";
CM_ SG_ 3221225472 SystmStat_VINStat_PLS_LH "System Status Position Light Left Headlamp Information : Left Headlamp Position Light VIN Status";
CM_ SG_ 3221225472 SystmStat_SysCalibStat_PLS_LH "System Status Position Light Left Headlamp Information : Left Headlamp Position Light System Information Calibration Status";
CM_ SG_ 3221225472 SystmStat_DertngStat_PLS_LH "System Status Position Light Left Headlamp Information : Left Headlamp Position Light Derating Status";
CM_ SG_ 3221225472 SystmStat_RefrncRunStat_PLS_LH "System Status Position Light Left Headlamp Information : Left Headlamp Position Light Reference Run Status";
CM_ SG_ 3221225472 SystmStat_OvrVltgFail_PLS_RH "System Status Position Light Right Headlamp Information : Right Headlamp Position Light Over Voltage Failed";
CM_ SG_ 3221225472 SystmStat_IntrnlSysFail_PLS_RH "System Status Position Light Right Headlamp Information : Right Headlamp Position Light Internal System Failed";
CM_ SG_ 3221225472 SystmStat_OpnLoadFail_PLS_RH "System Status Position Light Right Headlamp Information : Right Headlamp Position Light Open Load Failed";
CM_ SG_ 3221225472 SystmStat_ShrtCirctFail_PLS_RH "System Status Position Light Right Headlamp Information : Right Headlamp Position Light Short Circuit Failed";
CM_ SG_ 3221225472 SystmStat_OverTempFail_PLS_RH "System Status Position Light Right Headlamp Information : Right Headlamp Position Light Over Temperature Failed";
CM_ SG_ 3221225472 SystmStat_MstrMsgFail_PLS_RH "System Status Position Light Right Headlamp Information : Right Headlamp Position Light Master ECU Message Failed";
CM_ SG_ 3221225472 SystmStat_FanFail_PLS_RH "System Status Position Light Right Headlamp Information : Right Headlamp Position Light FAN Failed";
CM_ SG_ 3221225472 SystmStat_CurntCdngFail_PLS_RH "System Status Position Light Right Headlamp Information : Right Headlamp Position Light Current Coding Failed";
CM_ SG_ 3221225472 SystmStat_ExtTempFail_PLS_RH "System Status Position Light Right Headlamp Information : Right Headlamp Position Light External Temperature Failed";
CM_ SG_ 3221225472 SystmStat_IntnlTempFail_PLS_RH "System Status Position Light Right Headlamp Information : Right Headlamp Position Light Internal Temperature Failed";
CM_ SG_ 3221225472 SystmStat_ActutorFail_PLS_RH "System Status Position Light Right Headlamp Information : Right Headlamp Position Light Actuator Failed";
CM_ SG_ 3221225472 SystmStat_UndVltgFail_PLS_RH "System Status Position Light Right Headlamp Information : Right Headlamp Position Light Under Voltage Failed";
CM_ SG_ 3221225472 SystmStat_FnctnStat_PLS_RH "System Status Position Light Right Headlamp Information : Right Headlamp Position Light Function Status";
CM_ SG_ 3221225472 SystmStat_R_L_DtctnFail_PLS_RH "System Status Position Light Right Headlamp Information : Right Headlamp Position Light Right/Left Side Detection Failed";
CM_ SG_ 3221225472 SystmStat_CSorMCFail_PLS_RH "System Status Position Light Right Headlamp Information : Right Headlamp Position Light Cksm or Message Counter Failed";
CM_ SG_ 3221225472 SystmStat_IncCompFail_PLS_RH "System Status Position Light Right Headlamp Information : Right Headlamp Position Light Incorrect Component Failed";
CM_ SG_ 3221225472 SystmStat_SpplyVltgVal_PLS_RH "System Status Position Light Right Headlamp Information : Right Headlamp Position Light Supply Voltage Value";
CM_ SG_ 3221225472 SystmStat_ExtTempVal_PLS_RH "System Status Position Light Right Headlamp Information : Right Headlamp Position Light External Temperature Value";
CM_ SG_ 3221225472 SystmStat_IntTempVal_PLS_RH "System Status Position Light Right Headlamp Information : Right Headlamp Position Light Internal Temperature Value";
CM_ SG_ 3221225472 SystmStat_VINStat_PLS_RH "System Status Position Light Right Headlamp Information : Right Headlamp Position Light VIN Status";
CM_ SG_ 3221225472 SystmStat_SysCalibStat_PLS_RH "System Status Position Light Right Headlamp Information : Right Headlamp Position Light System Information Calibration Status";
CM_ SG_ 3221225472 SystmStat_DertngStat_PLS_RH "System Status Position Light Right Headlamp Information : Right Headlamp Position Light Derating Status";
CM_ SG_ 3221225472 SystmStat_RefrncRunStat_PLS_RH "System Status Position Light Right Headlamp Information : Right Headlamp Position Light Reference Run Status";
CM_ SG_ 3221225472 SystmStat_Chcksm_TILS_LH "System Status Turn Indication Left Headlamp Information : Left Headlamp Turn Indication Light Cksm";
CM_ SG_ 3221225472 SystmStat_OvrVltgFail_TILS_LH "System Status Turn Indication Left Headlamp Information : Left Headlamp Turn Indication Light Over Voltage Failed";
CM_ SG_ 3221225472 SystmStat_IntrnlSysFail_TILS_LH "System Status Turn Indication Left Headlamp Information : Left Headlamp Turn Indication Light Internal System Failed";
CM_ SG_ 3221225472 SystmStat_OpnLoadFail_TILS_LH "System Status Turn Indication Left Headlamp Information : Left Headlamp Turn Indication Light Open Load Failed";
CM_ SG_ 3221225472 SystmStat_ShrtCirctFail_TILS_LH "System Status Turn Indication Left Headlamp Information : Left Headlamp Turn Indication Light Short Circuit Failed";
CM_ SG_ 3221225472 SystmStat_MssgCntr_TILS_LH "System Status Turn Indication Left Headlamp Information : Left Headlamp Turn Indication Light Message Counter";
CM_ SG_ 3221225472 SystmStat_OverTempFail_TILS_LH "System Status Turn Indication Left Headlamp Information : Left Headlamp Turn Indication Light Over Temperature Failed";
CM_ SG_ 3221225472 SystmStat_MstrMsgFail_TILS_LH "System Status Turn Indication Left Headlamp Information : Left Headlamp Turn Indication Light Master ECU Message Failed";
CM_ SG_ 3221225472 SystmStat_FanFail_TILS_LH "System Status Turn Indication Left Headlamp Information : Left Headlamp Turn Indication Light FAN Failed";
CM_ SG_ 3221225472 SystmStat_CurntCdngFail_TILS_LH "System Status Turn Indication Left Headlamp Information : Left Headlamp Turn Indication Light Current Coding Failed";
CM_ SG_ 3221225472 SystmStat_ExtTempFail_TILS_LH "System Status Turn Indication Left Headlamp Information : Left Headlamp Turn Indication Light External Temperature Failed";
CM_ SG_ 3221225472 SystmStat_IntnlTempFail_TILS_LH "System Status Turn Indication Left Headlamp Information : Left Headlamp Turn Indication Light Internal Temperature Failed";
CM_ SG_ 3221225472 SystmStat_ActutorFail_TILS_LH "System Status Turn Indication Left Headlamp Information : Left Headlamp Turn Indication Light Actuator Failed";
CM_ SG_ 3221225472 SystmStat_UndVltgFail_TILS_LH "System Status Turn Indication Left Headlamp Information : Left Headlamp Turn Indication Light Under Voltage Failed";
CM_ SG_ 3221225472 SystmStat_FnctnStat_TILS_LH "System Status Turn Indication Left Headlamp Information : Left Headlamp Turn Indication Light Function Status";
CM_ SG_ 3221225472 SystmStat_R_L_DtctnFail_TILS_LH "System Status Turn Indication Left Headlamp Information : Left Headlamp Turn Indication Light Right/Left Side Detection Failed";
CM_ SG_ 3221225472 SystmStat_CSorMCFail_TILS_LH "System Status Turn Indication Left Headlamp Information : Left Headlamp Turn Indication Light Cksm or Message Counter Failed";
CM_ SG_ 3221225472 SystmStat_IncCompFail_TILS_LH "System Status Turn Indication Left Headlamp Information : Left Headlamp Turn Indication Light Incorrect Component Failed";
CM_ SG_ 3221225472 SystmStat_SpplyVltgVal_TILS_LH "System Status Turn Indication Left Headlamp Information : Left Headlamp Turn Indication Light Supply Voltage Value";
CM_ SG_ 3221225472 SystmStat_ExtTempVal_TILS_LH "System Status Turn Indication Left Headlamp Information : Left Headlamp Turn Indication Light External Temperature Value";
CM_ SG_ 3221225472 SystmStat_IntTempVal_TILS_LH "System Status Turn Indication Left Headlamp Information : Left Headlamp Turn Indication Light Internal Temperature Value";
CM_ SG_ 3221225472 SystmStat_VINStat_TILS_LH "System Status Turn Indication Left Headlamp Information : Left Headlamp Turn Indication Light VIN Status";
CM_ SG_ 3221225472 SystmStat_SysCalibStat_TILS_LH "System Status Turn Indication Left Headlamp Information : Left Headlamp Turn Indication Light System Information Calibration Status";
CM_ SG_ 3221225472 SystmStat_DertngStat_TILS_LH "System Status Turn Indication Left Headlamp Information : Left Headlamp Turn Indication Light Derating Status";
CM_ SG_ 3221225472 SystmStat_RefrncRunStat_TILS_LH "System Status Turn Indication Left Headlamp Information : Left Headlamp Turn Indication Light Reference Run Status";
CM_ SG_ 3221225472 SystmStat_Chcksm_TILS_RH "System Status Turn Indication Right Headlamp Information : Right Headlamp Turn Indication Light Cksm";
CM_ SG_ 3221225472 SystmStat_OvrVltgFail_TILS_RH "System Status Turn Indication Right Headlamp Information : Right Headlamp Turn Indication Light Over Voltage Failed";
CM_ SG_ 3221225472 SystmStat_IntrnlSysFail_TILS_RH "System Status Turn Indication Right Headlamp Information : Right Headlamp Turn Indication Light Internal System Failed";
CM_ SG_ 3221225472 SystmStat_OpnLoadFail_TILS_RH "System Status Turn Indication Right Headlamp Information : Right Headlamp Turn Indication Light Open Load Failed";
CM_ SG_ 3221225472 SystmStat_ShrtCirctFail_TILS_RH "System Status Turn Indication Right Headlamp Information : Right Headlamp Turn Indication Light Short Circuit Failed";
CM_ SG_ 3221225472 SystmStat_MssgCntr_TILS_RH "System Status Turn Indication Right Headlamp Information : Right Headlamp Turn Indication Light Message Counter";
CM_ SG_ 3221225472 SystmStat_OverTempFail_TILS_RH "System Status Turn Indication Right Headlamp Information : Right Headlamp Turn Indication Light Over Temperature Failed";
CM_ SG_ 3221225472 SystmStat_MstrMsgFail_TILS_RH "System Status Turn Indication Right Headlamp Information : Right Headlamp Turn Indication Light Master ECU Message Failed";
CM_ SG_ 3221225472 SystmStat_FanFail_TILS_RH "System Status Turn Indication Right Headlamp Information : Right Headlamp Turn Indication Light FAN Failed";
CM_ SG_ 3221225472 SystmStat_CurntCdngFail_TILS_RH "System Status Turn Indication Right Headlamp Information : Right Headlamp Turn Indication Light Current Coding Failed";
CM_ SG_ 3221225472 SystmStat_ExtTempFail_TILS_RH "System Status Turn Indication Right Headlamp Information : Right Headlamp Turn Indication Light External Temperature Failed";
CM_ SG_ 3221225472 SystmStat_IntnlTempFail_TILS_RH "System Status Turn Indication Right Headlamp Information : Right Headlamp Turn Indication Light Internal Temperature Failed";
CM_ SG_ 3221225472 SystmStat_ActutorFail_TILS_RH "System Status Turn Indication Right Headlamp Information : Right Headlamp Turn Indication Light Actuator Failed";
CM_ SG_ 3221225472 SystmStat_UndVltgFail_TILS_RH "System Status Turn Indication Right Headlamp Information : Right Headlamp Turn Indication Light Under Voltage Failed";
CM_ SG_ 3221225472 SystmStat_FnctnStat_TILS_RH "System Status Turn Indication Right Headlamp Information : Right Headlamp Turn Indication Light Function Status";
CM_ SG_ 3221225472 SystmStat_R_L_DtctnFail_TILS_RH "System Status Turn Indication Right Headlamp Information : Right Headlamp Turn Indication Light Right/Left Side Detection Failed";
CM_ SG_ 3221225472 SystmStat_CSorMCFail_TILS_RH "System Status Turn Indication Right Headlamp Information : Right Headlamp Turn Indication Light Cksm or Message Counter Failed";
CM_ SG_ 3221225472 SystmStat_IncCompFail_TILS_RH "System Status Turn Indication Right Headlamp Information : Right Headlamp Turn Indication Light Incorrect Component Failed";
CM_ SG_ 3221225472 SystmStat_SpplyVltgVal_TILS_RH "System Status Turn Indication Right Headlamp Information : Right Headlamp Turn Indication Light Supply Voltage Value";
CM_ SG_ 3221225472 SystmStat_ExtTempVal_TILS_RH "System Status Turn Indication Right Headlamp Information : Right Headlamp Turn Indication Light External Temperature Value";
CM_ SG_ 3221225472 SystmStat_IntTempVal_TILS_RH "System Status Turn Indication Right Headlamp Information : Right Headlamp Turn Indication Light Internal Temperature Value";
CM_ SG_ 3221225472 SystmStat_VINStat_TILS_RH "System Status Turn Indication Right Headlamp Information : Right Headlamp Turn Indication Light VIN Status";
CM_ SG_ 3221225472 SystmStat_SysCalibStat_TILS_RH "System Status Turn Indication Right Headlamp Information : Right Headlamp Turn Indication Light System Information Calibration Status";
CM_ SG_ 3221225472 SystmStat_DertngStat_TILS_RH "System Status Turn Indication Right Headlamp Information : Right Headlamp Turn Indication Light Derating Status";
CM_ SG_ 3221225472 SystmStat_RefrncRunStat_TILS_RH "System Status Turn Indication Right Headlamp Information : Right Headlamp Turn Indication Light Reference Run Status";
CM_ SG_ 3221225472 SystmStat_Chcksm_LBLS_LH "System Status Low Beam Light Left Headlamp Information : Left Headlamp Low Beam Light Cksm";
CM_ SG_ 3221225472 SystmStat_OvrVltgFail_LBLS_LH "System Status Low Beam Light Left Headlamp Information : Left Headlamp Low Beam Light Over Voltage Failed";
CM_ SG_ 3221225472 SystmStat_IntrnlSysFail_LBLS_LH "System Status Low Beam Light Left Headlamp Information : Left Headlamp Low Beam Light Internal System Failed";
CM_ SG_ 3221225472 SystmStat_OpnLoadFail_LBLS_LH "System Status Low Beam Light Left Headlamp Information : Left Headlamp Low Beam Light Open Load Failed";
CM_ SG_ 3221225472 SystmStat_ShrtCirctFail_LBLS_LH "System Status Low Beam Light Left Headlamp Information : Left Headlamp Low Beam Light Short Circuit Failed";
CM_ SG_ 3221225472 SystmStat_MssgCntr_LBLS_LH "System Status Low Beam Light Left Headlamp Information : Left Headlamp Low Beam Light Message Counter";
CM_ SG_ 3221225472 SystmStat_OverTempFail_LBLS_LH "System Status Low Beam Light Left Headlamp Information : Left Headlamp Low Beam Light Over Temperature Failed";
CM_ SG_ 3221225472 SystmStat_MstrMsgFail_LBLS_LH "System Status Low Beam Light Left Headlamp Information : Left Headlamp Low Beam Light Master ECU Message Failed";
CM_ SG_ 3221225472 SystmStat_FanFail_LBLS_LH "System Status Low Beam Light Left Headlamp Information : Left Headlamp Low Beam Light FAN Failed";
CM_ SG_ 3221225472 SystmStat_CurntCdngFail_LBLS_LH "System Status Low Beam Light Left Headlamp Information : Left Headlamp Low Beam Light Current Coding Failed";
CM_ SG_ 3221225472 SystmStat_ExtTempFail_LBLS_LH "System Status Low Beam Light Left Headlamp Information : Left Headlamp Low Beam Light External Temperature Failed";
CM_ SG_ 3221225472 SystmStat_IntnlTempFail_LBLS_LH "System Status Low Beam Light Left Headlamp Information : Left Headlamp Low Beam Light Internal Temperature Failed";
CM_ SG_ 3221225472 SystmStat_ActutorFail_LBLS_LH "System Status Low Beam Light Left Headlamp Information : Left Headlamp Low Beam Light Actuator Failed";
CM_ SG_ 3221225472 SystmStat_UndVltgFail_LBLS_LH "System Status Low Beam Light Left Headlamp Information : Left Headlamp Low Beam Light Under Voltage Failed";
CM_ SG_ 3221225472 SystmStat_FnctnStat_LBLS_LH "System Status Low Beam Light Left Headlamp Information : Left Headlamp Low Beam Light Function Status";
CM_ SG_ 3221225472 SystmStat_R_L_DtctnFail_LBLS_LH "System Status Low Beam Light Left Headlamp Information : Left Headlamp Low Beam Light Right/Left Side Detection Failed";
CM_ SG_ 3221225472 SystmStat_CSorMCFail_LBLS_LH "System Status Low Beam Light Left Headlamp Information : Left Headlamp Low Beam Light Cksm or Message Counter Failed";
CM_ SG_ 3221225472 SystmStat_IncCompFail_LBLS_LH "System Status Low Beam Light Left Headlamp Information : Left Headlamp Low Beam Light Incorrect Component Failed";
CM_ SG_ 3221225472 SystmStat_SpplyVltgVal_LBLS_LH "System Status Low Beam Light Left Headlamp Information : Left Headlamp Low Beam Light Supply Voltage Value";
CM_ SG_ 3221225472 SystmStat_ExtTempVal_LBLS_LH "System Status Low Beam Light Left Headlamp Information : Left Headlamp Low Beam Light External Temperature Value";
CM_ SG_ 3221225472 SystmStat_IntTempVal_LBLS_LH "System Status Low Beam Light Left Headlamp Information : Left Headlamp Low Beam Light Internal Temperature Value";
CM_ SG_ 3221225472 SystmStat_VINStat_LBLS_LH "System Status Low Beam Light Left Headlamp Information : Left Headlamp Low Beam Light VIN Status";
CM_ SG_ 3221225472 SystmStat_SysCalibStat_LBLS_LH "System Status Low Beam Light Left Headlamp Information : Left Headlamp Low Beam Light System Information Calibration Status";
CM_ SG_ 3221225472 SystmStat_DertngStat_LBLS_LH "System Status Low Beam Light Left Headlamp Information : Left Headlamp Low Beam Light Derating Status";
CM_ SG_ 3221225472 SystmStat_RefrncRunStat_LBLS_LH "System Status Low Beam Light Left Headlamp Information : Left Headlamp Low Beam Light Reference Run Status";
CM_ SG_ 3221225472 SystmStat_Chcksm_LBLS_RH "System Status Low Beam Light Right Headlamp Information : Right Headlamp Low Beam Light Cksm";
CM_ SG_ 3221225472 SystmStat_OvrVltgFail_LBLS_RH "System Status Low Beam Light Right Headlamp Information : Right Headlamp Low Beam Light Over Voltage Failed";
CM_ SG_ 3221225472 SystmStat_IntrnlSysFail_LBLS_RH "System Status Low Beam Light Right Headlamp Information : Right Headlamp Low Beam Light Internal System Failed";
CM_ SG_ 3221225472 SystmStat_OpnLoadFail_LBLS_RH "System Status Low Beam Light Right Headlamp Information : Right Headlamp Low Beam Light Open Load Failed";
CM_ SG_ 3221225472 SystmStat_ShrtCirctFail_LBLS_RH "System Status Low Beam Light Right Headlamp Information : Right Headlamp Low Beam Light Short Circuit Failed";
CM_ SG_ 3221225472 SystmStat_MssgCntr_LBLS_RH "System Status Low Beam Light Right Headlamp Information : Right Headlamp Low Beam Light Message Counter";
CM_ SG_ 3221225472 SystmStat_OverTempFail_LBLS_RH "System Status Low Beam Light Right Headlamp Information : Right Headlamp Low Beam Light Over Temperature Failed";
CM_ SG_ 3221225472 SystmStat_MstrMsgFail_LBLS_RH "System Status Low Beam Light Right Headlamp Information : Right Headlamp Low Beam Light Master ECU Message Failed";
CM_ SG_ 3221225472 SystmStat_FanFail_LBLS_RH "System Status Low Beam Light Right Headlamp Information : Right Headlamp Low Beam Light FAN Failed";
CM_ SG_ 3221225472 SystmStat_CurntCdngFail_LBLS_RH "System Status Low Beam Light Right Headlamp Information : Right Headlamp Low Beam Light Current Coding Failed";
CM_ SG_ 3221225472 SystmStat_ExtTempFail_LBLS_RH "System Status Low Beam Light Right Headlamp Information : Right Headlamp Low Beam Light External Temperature Failed";
CM_ SG_ 3221225472 SystmStat_IntnlTempFail_LBLS_RH "System Status Low Beam Light Right Headlamp Information : Right Headlamp Low Beam Light Internal Temperature Failed";
CM_ SG_ 3221225472 SystmStat_ActutorFail_LBLS_RH "System Status Low Beam Light Right Headlamp Information : Right Headlamp Low Beam Light Actuator Failed";
CM_ SG_ 3221225472 SystmStat_UndVltgFail_LBLS_RH "System Status Low Beam Light Right Headlamp Information : Right Headlamp Low Beam Light Under Voltage Failed";
CM_ SG_ 3221225472 SystmStat_FnctnStat_LBLS_RH "System Status Low Beam Light Right Headlamp Information : Right Headlamp Low Beam Light Function Status";
CM_ SG_ 3221225472 SystmStat_R_L_DtctnFail_LBLS_RH "System Status Low Beam Light Right Headlamp Information : Right Headlamp Low Beam Light Right/Left Side Detection Failed";
CM_ SG_ 3221225472 SystmStat_CSorMCFail_LBLS_RH "System Status Low Beam Light Right Headlamp Information : Right Headlamp Low Beam Light Cksm or Message Counter Failed";
CM_ SG_ 3221225472 SystmStat_IncCompFail_LBLS_RH "System Status Low Beam Light Right Headlamp Information : Right Headlamp Low Beam Light Incorrect Component Failed";
CM_ SG_ 3221225472 SystmStat_SpplyVltgVal_LBLS_RH "System Status Low Beam Light Right Headlamp Information : Right Headlamp Low Beam Light Supply Voltage Value";
CM_ SG_ 3221225472 SystmStat_ExtTempVal_LBLS_RH "System Status Low Beam Light Right Headlamp Information : Right Headlamp Low Beam Light External Temperature Value";
CM_ SG_ 3221225472 SystmStat_IntTempVal_LBLS_RH "System Status Low Beam Light Right Headlamp Information : Right Headlamp Low Beam Light Internal Temperature Value";
CM_ SG_ 3221225472 SystmStat_VINStat_LBLS_RH "System Status Low Beam Light Right Headlamp Information : Right Headlamp Low Beam Light VIN Status";
CM_ SG_ 3221225472 SystmStat_SysCalibStat_LBLS_RH "System Status Low Beam Light Right Headlamp Information : Right Headlamp Low Beam Light System Information Calibration Status";
CM_ SG_ 3221225472 SystmStat_DertngStat_LBLS_RH "System Status Low Beam Light Right Headlamp Information : Right Headlamp Low Beam Light Derating Status";
CM_ SG_ 3221225472 SystmStat_RefrncRunStat_LBLS_RH "System Status Low Beam Light Right Headlamp Information : Right Headlamp Low Beam Light Reference Run Status";
CM_ SG_ 3221225472 SystmStat_Chcksm_HBLS_LH "System Status High Beam Light Left Headlamp Information : Left Headlamp High Beam Light Cksm";
CM_ SG_ 3221225472 SystmStat_OvrVltgFail_HBLS_LH "System Status High Beam Light Left Headlamp Information : Left Headlamp High Beam Light Over Voltage Failed";
CM_ SG_ 3221225472 SystmStat_IntrnlSysFail_HBLS_LH "System Status High Beam Light Left Headlamp Information : Left Headlamp High Beam Light Internal System Failed";
CM_ SG_ 3221225472 SystmStat_OpnLoadFail_HBLS_LH "System Status High Beam Light Left Headlamp Information : Left Headlamp High Beam Light Open Load Failed";
CM_ SG_ 3221225472 SystmStat_ShrtCirctFail_HBLS_LH "System Status High Beam Light Left Headlamp Information : Left Headlamp High Beam Light Short Circuit Failed";
CM_ SG_ 3221225472 SystmStat_MssgCntr_HBLS_LH "System Status High Beam Light Left Headlamp Information : Left Headlamp High Beam Light Message Counter";
CM_ SG_ 3221225472 SystmStat_OverTempFail_HBLS_LH "System Status High Beam Light Left Headlamp Information : Left Headlamp High Beam Light Over Temperature Failed";
CM_ SG_ 3221225472 SystmStat_MstrMsgFail_HBLS_LH "System Status High Beam Light Left Headlamp Information : Left Headlamp High Beam Light Master ECU Message Failed";
CM_ SG_ 3221225472 SystmStat_FanFail_HBLS_LH "System Status High Beam Light Left Headlamp Information : Left Headlamp High Beam Light FAN Failed";
CM_ SG_ 3221225472 SystmStat_CurntCdngFail_HBLS_LH "System Status High Beam Light Left Headlamp Information : Left Headlamp High Beam Light Current Coding Failed";
CM_ SG_ 3221225472 SystmStat_ExtTempFail_HBLS_LH "System Status High Beam Light Left Headlamp Information : Left Headlamp High Beam Light External Temperature Failed";
CM_ SG_ 3221225472 SystmStat_IntnlTempFail_HBLS_LH "System Status High Beam Light Left Headlamp Information : Left Headlamp High Beam Light Internal Temperature Failed";
CM_ SG_ 3221225472 SystmStat_ActutorFail_HBLS_LH "System Status High Beam Light Left Headlamp Information : Left Headlamp High Beam Light Actuator Failed";
CM_ SG_ 3221225472 SystmStat_UndVltgFail_HBLS_LH "System Status High Beam Light Left Headlamp Information : Left Headlamp High Beam Light Under Voltage Failed";
CM_ SG_ 3221225472 SystmStat_FnctnStat_HBLS_LH "System Status High Beam Light Left Headlamp Information : Left Headlamp High Beam Light Function Status";
CM_ SG_ 3221225472 SystmStat_R_L_DtctnFail_HBLS_LH "System Status High Beam Light Left Headlamp Information : Left Headlamp High Beam Light Right/Left Side Detection Failed";
CM_ SG_ 3221225472 SystmStat_CSorMCFail_HBLS_LH "System Status High Beam Light Left Headlamp Information : Left Headlamp High Beam Light Cksm or Message Counter Failed";
CM_ SG_ 3221225472 SystmStat_IncCompFail_HBLS_LH "System Status High Beam Light Left Headlamp Information : Left Headlamp High Beam Light Incorrect Component Failed";
CM_ SG_ 3221225472 SystmStat_SpplyVltgVal_HBLS_LH "System Status High Beam Light Left Headlamp Information : Left Headlamp High Beam Light Supply Voltage Value";
CM_ SG_ 3221225472 SystmStat_ExtTempVal_HBLS_LH "System Status High Beam Light Left Headlamp Information : Left Headlamp High Beam Light External Temperature Value";
CM_ SG_ 3221225472 SystmStat_IntTempVal_HBLS_LH "System Status High Beam Light Left Headlamp Information : Left Headlamp High Beam Light Internal Temperature Value";
CM_ SG_ 3221225472 SystmStat_VINStat_HBLS_LH "System Status High Beam Light Left Headlamp Information : Left Headlamp High Beam Light VIN Status";
CM_ SG_ 3221225472 SystmStat_SysCalibStat_HBLS_LH "System Status High Beam Light Left Headlamp Information : Left Headlamp High Beam Light System Information Calibration Status";
CM_ SG_ 3221225472 SystmStat_DertngStat_HBLS_LH "System Status High Beam Light Left Headlamp Information : Left Headlamp High Beam Light Derating Status";
CM_ SG_ 3221225472 SystmStat_RefrncRunStat_HBLS_LH "System Status High Beam Light Left Headlamp Information : Left Headlamp High Beam Light Reference Run Status";
CM_ SG_ 3221225472 SystmStat_Chcksm_HBLS_RH "System Status High Beam Light Right Headlamp Information : Right Headlamp High Beam Light Cksm";
CM_ SG_ 3221225472 SystmStat_OvrVltgFail_HBLS_RH "System Status High Beam Light Right Headlamp Information : Right Headlamp High Beam Light Over Voltage Failed";
CM_ SG_ 3221225472 SystmStat_IntrnlSysFail_HBLS_RH "System Status High Beam Light Right Headlamp Information : Right Headlamp High Beam Light Internal System Failed";
CM_ SG_ 3221225472 SystmStat_OpnLoadFail_HBLS_RH "System Status High Beam Light Right Headlamp Information : Right Headlamp High Beam Light Open Load Failed";
CM_ SG_ 3221225472 SystmStat_ShrtCirctFail_HBLS_RH "System Status High Beam Light Right Headlamp Information : Right Headlamp High Beam Light Short Circuit Failed";
CM_ SG_ 3221225472 SystmStat_MssgCntr_HBLS_RH "System Status High Beam Light Right Headlamp Information : Right Headlamp High Beam Light Message Counter";
CM_ SG_ 3221225472 SystmStat_OverTempFail_HBLS_RH "System Status High Beam Light Right Headlamp Information : Right Headlamp High Beam Light Over Temperature Failed";
CM_ SG_ 3221225472 SystmStat_MstrMsgFail_HBLS_RH "System Status High Beam Light Right Headlamp Information : Right Headlamp High Beam Light Master ECU Message Failed";
CM_ SG_ 3221225472 SystmStat_FanFail_HBLS_RH "System Status High Beam Light Right Headlamp Information : Right Headlamp High Beam Light FAN Failed";
CM_ SG_ 3221225472 SystmStat_CurntCdngFail_HBLS_RH "System Status High Beam Light Right Headlamp Information : Right Headlamp High Beam Light Current Coding Failed";
CM_ SG_ 3221225472 SystmStat_ExtTempFail_HBLS_RH "System Status High Beam Light Right Headlamp Information : Right Headlamp High Beam Light External Temperature Failed";
CM_ SG_ 3221225472 SystmStat_IntnlTempFail_HBLS_RH "System Status High Beam Light Right Headlamp Information : Right Headlamp High Beam Light Internal Temperature Failed";
CM_ SG_ 3221225472 SystmStat_ActutorFail_HBLS_RH "System Status High Beam Light Right Headlamp Information : Right Headlamp High Beam Light Actuator Failed";
CM_ SG_ 3221225472 SystmStat_UndVltgFail_HBLS_RH "System Status High Beam Light Right Headlamp Information : Right Headlamp High Beam Light Under Voltage Failed";
CM_ SG_ 3221225472 SystmStat_FnctnStat_HBLS_RH "System Status High Beam Light Right Headlamp Information : Right Headlamp High Beam Light Function Status";
CM_ SG_ 3221225472 SystmStat_R_L_DtctnFail_HBLS_RH "System Status High Beam Light Right Headlamp Information : Right Headlamp High Beam Light Right/Left Side Detection Failed";
CM_ SG_ 3221225472 SystmStat_CSorMCFail_HBLS_RH "System Status High Beam Light Right Headlamp Information : Right Headlamp High Beam Light Cksm or Message Counter Failed";
CM_ SG_ 3221225472 SystmStat_IncCompFail_HBLS_RH "System Status High Beam Light Right Headlamp Information : Right Headlamp High Beam Light Incorrect Component Failed";
CM_ SG_ 3221225472 SystmStat_SpplyVltgVal_HBLS_RH "System Status High Beam Light Right Headlamp Information : Right Headlamp High Beam Light Supply Voltage Value";
CM_ SG_ 3221225472 SystmStat_ExtTempVal_HBLS_RH "System Status High Beam Light Right Headlamp Information : Right Headlamp High Beam Light External Temperature Value";
CM_ SG_ 3221225472 SystmStat_IntTempVal_HBLS_RH "System Status High Beam Light Right Headlamp Information : Right Headlamp High Beam Light Internal Temperature Value";
CM_ SG_ 3221225472 SystmStat_VINStat_HBLS_RH "System Status High Beam Light Right Headlamp Information : Right Headlamp High Beam Light VIN Status";
CM_ SG_ 3221225472 SystmStat_SysCalibStat_HBLS_RH "System Status High Beam Light Right Headlamp Information : Right Headlamp High Beam Light System Information Calibration Status";
CM_ SG_ 3221225472 SystmStat_DertngStat_HBLS_RH "System Status High Beam Light Right Headlamp Information : Right Headlamp High Beam Light Derating Status";
CM_ SG_ 3221225472 SystmStat_RefrncRunStat_HBLS_RH "System Status High Beam Light Right Headlamp Information : Right Headlamp High Beam Light Reference Run Status";
CM_ SG_ 3221225472 LDS_GFHBLghtDstrbtnMtrwyLvl_3_RH "Light Distribution System Information : Right Headlamp Glare Free High Beam Light Distribution Motorway Level 3";
CM_ SG_ 3221225472 LDS_GFHBLghtDstrbtnMtrwyLvl_2_RH "Light Distribution System Information : Right Headlamp Glare Free High Beam Light Distribution Motorway Level 2";
CM_ SG_ 3221225472 LDS_GFHBLghtDstrbtnMtrwyLvl_3_LH "Light Distribution System Information : Left Headlamp Glare Free High Beam Light Distribution Motorway Level 3";
CM_ SG_ 3221225472 LDS_GFHBLghtDstrbtnMtrwyLvl_2_LH "Light Distribution System Information : Left Headlamp Glare Free High Beam Light Distribution Motorway Level 2";
CM_ SG_ 3221225472 LDS_MtrwyLghtDstrbtnLvl_E0_RH "Light Distribution System Information : Right Headlamp Motorway Light Distribution Level E0";
CM_ SG_ 3221225472 LDS_MtrwyLghtDstrbtnLvl_E3_LH "Light Distribution System Information : Left Headlamp Motorway Light Distribution Level E3";
CM_ SG_ 3221225472 LDS_MtrwyLghtDstrbtnLvl_E3_RH "Light Distribution System Information : Right Headlamp Motorway Light Distribution Level E3";
CM_ SG_ 3221225472 LDS_MtrwyLghtDstrbtnLvl_E1_RH "Light Distribution System Information : Right Headlamp Motorway Light Distribution Level E1";
CM_ SG_ 3221225472 LghtDistrCksm "Light Distribution System Information : Light Distribution Cksm";
CM_ SG_ 3221225472 RespFromECU1_SoftwareProg_LH "Left Hand Headlamp ECU1 Software Programming Diagnostic Response";
CM_ SG_ 3221225472 ReqToECU3_SoftwareProg_LH "Left Hand Headlamp ECU3 Software Programming Diagnostic Request";
CM_ SG_ 3221225472 RespFromECU3_SoftwareProg_RH "Right Hand Headlamp ECU3 Software Programming Diagnostic Response";
CM_ SG_ 3221225472 ReqToECU1_SoftwareProg_LH "Left Hand Headlamp ECU1 Software Programming Diagnostic Request";
CM_ SG_ 3221225472 ReqToECU1_SoftwareProg_RH "Right Hand Headlamp ECU1 Software Programming Diagnostic Request";
CM_ SG_ 3221225472 RespFromECU3_SoftwareProg_LH "Left Hand Headlamp ECU3 Software Programming Diagnostic Response";
CM_ SG_ 3221225472 ReqToECU3_SoftwareProg_RH "Right Hand Headlamp ECU3 Software Programming Diagnostic Request";
CM_ SG_ 3221225472 LftLdm2Info "ECU 1 Left Headlamp Identification Information : Identification Byte 0";
CM_ SG_ 3221225472 LftLdm2InfoIdx "ECU 1 Left Headlamp Identification Information : Identification Byte 0";
CM_ SG_ 3221225472 RtLdm2Info "ECU 1 Right Headlamp Identification Information : Identification Byte 0";
CM_ SG_ 3221225472 RtLdm2InfoIdx "ECU 1 Right Headlamp Identification Information : Identification Byte 0";
CM_ SG_ 3221225472 LftLdm3InfoIdx "ECU 1 Left Headlamp Identification Information : Identification Byte 0";
CM_ SG_ 3221225472 LftLdm3Info "ECU 1 Left Headlamp Identification Information : Identification Byte 0";
CM_ SG_ 3221225472 RtLdm3InfoIdx "ECU 1 Right Headlamp Identification Information : Identification Byte 0";
CM_ SG_ 3221225472 RtLdm3Info "ECU 1 Right Headlamp Identification Information : Identification Byte 0";
CM_ SG_ 3221225472 LftFuncReq_8 "Glare Free High Beam LED Control Left Headlamp Information : Diagnostic Left Hand LED Number 8";
CM_ SG_ 3221225472 LftFuncReq_7 "Glare Free High Beam LED Control Left Headlamp Information : Diagnostic Left Hand LED Number 7";
CM_ SG_ 3221225472 LftFuncReq_6 "Glare Free High Beam LED Control Left Headlamp Information : Diagnostic Left Hand LED Number 6";
CM_ SG_ 3221225472 LftFuncReq_5 "Glare Free High Beam LED Control Left Headlamp Information : Diagnostic Left Hand LED Number 5";
CM_ SG_ 3221225472 LftFuncReq_4 "Glare Free High Beam LED Control Left Headlamp Information : Diagnostic Left Hand LED Number 4";
CM_ SG_ 3221225472 LftFuncReq_3 "Glare Free High Beam LED Control Left Headlamp Information : Diagnostic Left Hand LED Number 3";
CM_ SG_ 3221225472 LftFuncReq_2 "Glare Free High Beam LED Control Left Headlamp Information : Diagnostic Left Hand LED Number 2";
CM_ SG_ 3221225472 RtFuncReq_8 "Glare Free High Beam LED Control Right Headlamp Information : Diagnostic Right Hand LED Number 8";
CM_ SG_ 3221225472 RtFuncReq_7 "Glare Free High Beam LED Control Right Headlamp Information : Diagnostic Right Hand LED Number 7";
CM_ SG_ 3221225472 RtFuncReq_6 "Glare Free High Beam LED Control Right Headlamp Information : Diagnostic Right Hand LED Number 6";
CM_ SG_ 3221225472 RtFuncReq_5 "Glare Free High Beam LED Control Right Headlamp Information : Diagnostic Right Hand LED Number 5";
CM_ SG_ 3221225472 RtFuncReq_4 "Glare Free High Beam LED Control Right Headlamp Information : Diagnostic Right Hand LED Number 4";
CM_ SG_ 3221225472 RtFuncReq_3 "Glare Free High Beam LED Control Right Headlamp Information : Diagnostic Right Hand LED Number 3";
CM_ SG_ 3221225472 RtFuncReq_2 "Glare Free High Beam LED Control Right Headlamp Information : Diagnostic Right Hand LED Number 2";
CM_ SG_ 3221225472 VIN "Vehicle Identification Number Information : VIN Byte 0";
CM_ SG_ 3221225472 LftRoutineCtrl "Glare Free High Beam LED Control Left Headlamp Information : Diagnostic Left Hand LED Control Release";
CM_ SG_ 3221225472 LftFuncReq "Glare Free High Beam LED Control Left Headlamp Information : Diagnostic Left Hand LED Number 1";
CM_ SG_ 3221225472 RtRoutineCtrl "Glare Free High Beam LED Control Right Headlamp Information : Diagnostic Right Hand LED Control Release";
CM_ SG_ 3221225472 RtFuncReq "Glare Free High Beam LED Control Right Headlamp Information : Diagnostic Right Hand LED Number 1";
BA_DEF_ SG_  "GenSigSendType" ENUM  "NotUsed","OnWrite","OnWriteWithRepetition","OnChange","OnChangeWithRepetition","IfActive","IfActiveWithRepeition","NoSigSendType";
BA_DEF_ SG_  "GenSigSendOnInit" ENUM  "Not Initialized","Application","Handler";
BA_DEF_ BO_  "GenMsgSendType" ENUM  "Cyclic","NotUsed","NotUsed","NotUsed","NotUsed","NotUsed","NotUsed","NotUsed","NoMsgSendType";
BA_DEF_ BO_  "GenMsgStartDelayTime" INT 0 100000;
BA_DEF_ BO_  "MessageSubnet" ENUM  "BB","PB","CB","Body","HS","Powertrain","Chassis","Spare","PE","CC";
BA_DEF_ BO_  "DiagState" ENUM  "No","Yes";
BA_DEF_ BO_  "DiagResponse" ENUM  "No","Yes";
BA_DEF_ BO_  "DiagRequest" ENUM  "No","Yes";
BA_DEF_ BO_  "GenMsgDelayTime" INT 0 100000;
BA_DEF_ BO_  "GenMsgCycleTime" INT 0 100000;
BA_DEF_ BO_  "GenMsgILSupport" ENUM  "No","Yes";
BA_DEF_ BU_  "NmAsrCanMsgReducedTime" INT 0 65535;
BA_DEF_ BU_  "NmAsrNodeIdentifier" HEX 0 159;
BA_DEF_ BU_  "NmAsrNode" ENUM  "No","Yes";
BA_DEF_ BU_  "SourceId" HEX 0 255;
BA_DEF_ BU_  "ILUsed" ENUM  "No","Yes";
BA_DEF_ BU_  "ECU_Id" HEX 0 255;
BA_DEF_  "NmAsrCanMsgCycleTime" INT 0 65535;
BA_DEF_  "NmAsrRepeatMessageTime" INT 0 65525;
BA_DEF_  "NmAsrWaitBusSleepTime" INT 0 65535;
BA_DEF_  "NmAsrTimeoutTime" INT 0 65535;
BA_DEF_  "NmAsrBaseAddress" HEX 370 370;
BA_DEF_  "NmAsrMessageCount" INT 0 256;
BA_DEF_  "BusType" STRING ;
BA_DEF_  "SyncJumpWidthMax" INT 0 255;
BA_DEF_  "SyncJumpWidthMin" INT 0 255;
BA_DEF_  "SamplePointMax" FLOAT 0 100;
BA_DEF_  "SamplePointMin" FLOAT 0 100;
BA_DEF_  "Manufacturer" STRING ;
BA_DEF_  "BusOffRecoveryTime" INT 0 65535;
BA_DEF_  "Baudrate" INT 0 1000000;
BA_DEF_  "NmType" STRING ;
BA_DEF_  "DBName" STRING ;
BA_DEF_REL_ BU_SG_REL_  "GenSigTimeoutTime" INT 0 15000;
BA_DEF_REL_ BU_SG_REL_  "GenSigTimeoutMsg" HEX 0 65535;
BA_DEF_DEF_  "GenSigSendType" "NoSigSendType";
BA_DEF_DEF_  "GenSigSendOnInit" "Not Initialized";
BA_DEF_DEF_  "GenMsgSendType" "NoMsgSendType";
BA_DEF_DEF_  "GenMsgStartDelayTime" 0;
BA_DEF_DEF_  "MessageSubnet" "Body";
BA_DEF_DEF_  "DiagState" "No";
BA_DEF_DEF_  "DiagResponse" "No";
BA_DEF_DEF_  "DiagRequest" "No";
BA_DEF_DEF_  "GenMsgDelayTime" 0;
BA_DEF_DEF_  "GenMsgCycleTime" 0;
BA_DEF_DEF_  "GenMsgILSupport" "Yes";
BA_DEF_DEF_  "NmAsrCanMsgReducedTime" 0;
BA_DEF_DEF_  "NmAsrNodeIdentifier" 0;
BA_DEF_DEF_  "NmAsrNode" "Yes";
BA_DEF_DEF_  "SourceId" 0;
BA_DEF_DEF_  "ILUsed" "Yes";
BA_DEF_DEF_  "ECU_Id" 0;
BA_DEF_DEF_  "NmAsrCanMsgCycleTime" 1000;
BA_DEF_DEF_  "NmAsrRepeatMessageTime" 400;
BA_DEF_DEF_  "NmAsrWaitBusSleepTime" 750;
BA_DEF_DEF_  "NmAsrTimeoutTime" 1000;
BA_DEF_DEF_  "NmAsrBaseAddress" 370;
BA_DEF_DEF_  "NmAsrMessageCount" 16;
BA_DEF_DEF_  "BusType" "CAN";
BA_DEF_DEF_  "SyncJumpWidthMax" 3;
BA_DEF_DEF_  "SyncJumpWidthMin" 4;
BA_DEF_DEF_  "SamplePointMax" 80;
BA_DEF_DEF_  "SamplePointMin" 81.25;
BA_DEF_DEF_  "Manufacturer" "GM";
BA_DEF_DEF_  "BusOffRecoveryTime" 160;
BA_DEF_DEF_  "Baudrate" 500000;
BA_DEF_DEF_  "NmType" "NmAsr";
BA_DEF_DEF_  "DBName" "SubCAN";
BA_DEF_DEF_REL_ "GenSigTimeoutTime" 0;
BA_DEF_DEF_REL_ "GenSigTimeoutMsg" 0;
BA_ "NmAsrCanMsgCycleTime" 400;
BA_ "DBName" "PB";
BA_ "NmAsrCanMsgReducedTime" BU_ LDM_LH 500;
BA_ "NmAsrNodeIdentifier" BU_ LDM_LH 1;
BA_ "ECU_Id" BU_ LDM_RH 1;
BA_ "SourceId" BU_ LDM_RH 1;
BA_ "GenMsgCycleTime" BO_ 480 100;
BA_ "MessageSubnet" BO_ 480 1;
BA_ "GenMsgSendType" BO_ 480 0;
BA_ "GenMsgSendType" BO_ 370 0;
BA_ "GenMsgCycleTime" BO_ 370 400;
BA_ "GenMsgCycleTime" BO_ 511 40;
BA_ "GenMsgSendType" BO_ 511 0;
BA_REL_ "GenSigTimeoutMsg" BU_SG_REL_ LDM_LH SG_ 370 NM_Signal 370;
BA_REL_ "GenSigTimeoutTime" BU_SG_REL_ LDM_LH SG_ 370 NM_Signal 1500;
BA_REL_ "GenSigTimeoutMsg" BU_SG_REL_ LDM_RH SG_ 370 NM_Signal 370;
BA_REL_ "GenSigTimeoutTime" BU_SG_REL_ LDM_RH SG_ 370 NM_Signal 1500;
SIG_GROUP_ 480 LftRtnCtrl 1 : LftRoutineCtrl LftDiagLed;
SIG_GROUP_ 511 HdLmpLvlgCfgGrp 1 : HdlmpLvlgMtrRtdCurr HdlmpLvlgMtrRtDir HdlmpLvlgMtrStlCurr HdlmpLvlgMtrStpPerPct HdlmpLvlgMtrLtDir HdlmpLvlgRngStltoNrm HdLmpLvlgCfgMsgCnt;
